VERSION "HNNBNNNYNNNNNNNNNNNNNNNNNNNNNNNNNNNNNNNNNN/4/%%%/4/'%**4NNN///"

NS_ :

BS_:

BU_: BAP_Tester Gateway_Max Getriebe_DQ Motor_konv Parksperre Schaltbetaetigung

BO_ 2550530105 ISOx_LCU_SMH_Resp: 8 Vector__XXX
 SG_ ISOx_LCU_SMH_Resp_Data : 0|64@1+ (1.0,0.0) [0.0|18446744073709551615] ""  Gateway_Max

BO_ 2621833273 ISOx_LCU_SMH_Resp_FD: 64 Vector__XXX
 SG_ ISOx_LCU_SMH_Resp_FD_Data : 0|512@1+ (1.0,0.0) [0.0|13407807929942597099574024998205846127479365820592393377723561443721764030073546976801874298166903427690031858186486050853753882811946569946433649006084095] ""  Gateway_Max

BO_ 2549874806 ISOx_MO_01_Req: 8 Gateway_Max
 SG_ ISOx_MO_01_Req_Data : 0|64@1+ (1.0,0.0) [0.0|18446744073709551615] ""  Motor_konv

BO_ 2621440118 ISOx_MO_01_Req_FD: 64 Gateway_Max
 SG_ ISOx_MO_01_Req_FD_Data : 0|512@1+ (1.0,0.0) [0.0|13407807929942597099574024998205846127479365820592393377723561443721764030073546976801874298166903427690031858186486050853753882811946569946433649006084095] ""  Motor_konv

BO_ 2550005878 ISOx_MO_01_Resp: 8 Motor_konv
 SG_ ISOx_MO_01_Resp_Data : 0|64@1+ (1.0,0.0) [0.0|18446744073709551615] ""  Gateway_Max

BO_ 2621571190 ISOx_MO_01_Resp_FD: 64 Motor_konv
 SG_ ISOx_MO_01_Resp_FD_Data : 0|512@1+ (1.0,0.0) [0.0|13407807929942597099574024998205846127479365820592393377723561443721764030073546976801874298166903427690031858186486050853753882811946569946433649006084095] ""  Gateway_Max

BO_ 2549874821 ISOx_RSG_Req: 8 Gateway_Max
 SG_ ISOx_RSG_Req_Data : 0|64@1+ (1.0,0.0) [0.0|18446744073709551615] ""  Vector__XXX

BO_ 2621440133 ISOx_RSG_Req_FD: 64 Gateway_Max
 SG_ ISOx_RSG_Req_FD_Data : 0|512@1+ (1.0,0.0) [0.0|13407807929942597099574024998205846127479365820592393377723561443721764030073546976801874298166903427690031858186486050853753882811946569946433649006084095] ""  Vector__XXX

BO_ 2550005893 ISOx_RSG_Resp: 8 Vector__XXX
 SG_ ISOx_RSG_Resp_Data : 0|64@1+ (1.0,0.0) [0.0|18446744073709551615] ""  Gateway_Max

BO_ 2621571205 ISOx_RSG_Resp_FD: 64 Vector__XXX
 SG_ ISOx_RSG_Resp_FD_Data : 0|512@1+ (1.0,0.0) [0.0|13407807929942597099574024998205846127479365820592393377723561443721764030073546976801874298166903427690031858186486050853753882811946569946433649006084095] ""  Gateway_Max

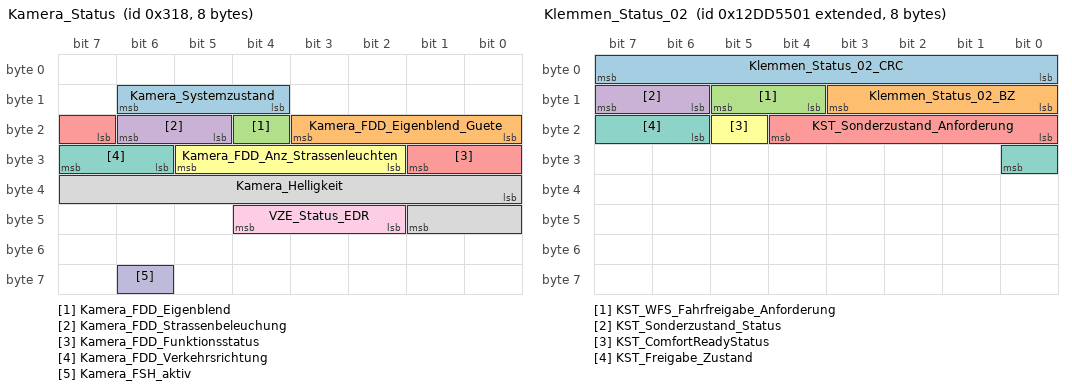
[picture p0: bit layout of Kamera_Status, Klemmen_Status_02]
BO_ 792 Kamera_Status: 8 Gateway_Max
 SG_ Kamera_Systemzustand : 12|3@1+ (1.0,0.0) [0.0|7] ""  Motor_konv
 SG_ Kamera_FDD_Eigenblend_Guete : 16|4@1+ (10,0) [0|100] "Unit_PerCent"  Vector__XXX
 SG_ Kamera_FDD_Eigenblend : 20|1@1+ (1.0,0.0) [0.0|1] ""  Vector__XXX
 SG_ Kamera_FDD_Strassenbeleuchung : 21|2@1+ (1.0,0.0) [0.0|3] ""  Vector__XXX
 SG_ Kamera_FDD_Funktionsstatus : 23|3@1+ (1.0,0.0) [0.0|7] ""  Vector__XXX
 SG_ Kamera_FDD_Anz_Strassenleuchten : 26|4@1+ (1,0) [0|14] ""  Vector__XXX
 SG_ Kamera_FDD_Verkehrsrichtung : 30|2@1+ (1.0,0.0) [0.0|3] ""  Vector__XXX
 SG_ Kamera_Helligkeit : 32|10@1+ (10,0) [0|10000] "Unit_Lux"  Vector__XXX
 SG_ VZE_Status_EDR : 42|3@1+ (1.0,0.0) [0.0|7] ""  Vector__XXX
 SG_ Kamera_FSH_aktiv : 62|1@1+ (1.0,0.0) [0.0|1] ""  Vector__XXX

BO_ 1426 Kessy_04: 8 Gateway_Max
 SG_ KY_ID_Geber1_im_Fzg : 12|1@1+ (1.0,0.0) [0.0|1] ""  Vector__XXX
 SG_ KY_ID_Geber2_im_Fzg : 13|1@1+ (1.0,0.0) [0.0|1] ""  Vector__XXX
 SG_ KY_ID_Geber3_im_Fzg : 14|1@1+ (1.0,0.0) [0.0|1] ""  Vector__XXX
 SG_ KY_ID_Geber4_im_Fzg : 15|1@1+ (1.0,0.0) [0.0|1] ""  Vector__XXX
 SG_ KY_Startknopf_Bel : 16|1@1+ (1.0,0.0) [0.0|1] ""  Vector__XXX
 SG_ KY_ID_Geber_Suche : 17|1@1+ (1.0,0.0) [0.0|1] ""  Vector__XXX
 SG_ KY_Meldungen : 18|4@1+ (1.0,0.0) [0.0|15] ""  Vector__XXX
 SG_ KY_Gong_600 : 22|1@1+ (1.0,0.0) [0.0|1] ""  Vector__XXX
 SG_ KY_Passiv_Autolock_Menue : 23|1@1+ (1.0,0.0) [0.0|1] ""  Vector__XXX
 SG_ KY_Passiv_Autolock_Akt : 24|1@1+ (1.0,0.0) [0.0|1] ""  Vector__XXX
 SG_ KY_Passiv_Autolock : 25|1@1+ (1.0,0.0) [0.0|1] ""  Vector__XXX
 SG_ KY_Passiv_Autounlock : 26|1@1+ (1.0,0.0) [0.0|1] ""  Vector__XXX
 SG_ KY_Gestik_HD : 27|1@1+ (1.0,0.0) [0.0|1] ""  Vector__XXX
 SG_ KY_StartStopp_Info : 28|2@1+ (1.0,0.0) [0.0|3] ""  Motor_konv
 SG_ KY_Fzg_Verlassen_erkannt : 30|1@1+ (1.0,0.0) [0.0|1] ""  Vector__XXX
 SG_ KY_Fzg_Zugang_erkannt : 31|1@1+ (1.0,0.0) [0.0|1] ""  Vector__XXX
 SG_ KY_EasyClose_Abbruch : 32|1@1+ (1.0,0.0) [0.0|1] ""  Vector__XXX
 SG_ KY_EasyClose_Status : 33|3@1+ (1.0,0.0) [0.0|7] ""  Vector__XXX
 SG_ KY_HD_Auffahrt : 36|1@1+ (1.0,0.0) [0.0|1] ""  Vector__XXX
 SG_ KY_HD_Zufahrt : 37|1@1+ (1.0,0.0) [0.0|1] ""  Vector__XXX
 SG_ KY_Aktive_LFScans : 38|4@1+ (1.0,0.0) [0.0|15] ""  Vector__XXX
 SG_ KY_LF_Aktiv : 42|1@1+ (1.0,0.0) [0.0|1] ""  Vector__XXX
 SG_ KY_AnzKoord_Info : 43|2@1+ (1.0,0.0) [0.0|3] ""  Vector__XXX
 SG_ KY_Schluesselposition_9 : 45|2@1+ (1.0,0.0) [0.0|3] ""  Vector__XXX
 SG_ KY_Schluesselposition_1 : 48|2@1+ (1.0,0.0) [0.0|3] ""  Vector__XXX
 SG_ KY_Schluesselposition_2 : 50|2@1+ (1.0,0.0) [0.0|3] ""  Vector__XXX
 SG_ KY_Schluesselposition_3 : 52|2@1+ (1.0,0.0) [0.0|3] ""  Vector__XXX
 SG_ KY_Schluesselposition_4 : 54|2@1+ (1.0,0.0) [0.0|3] ""  Vector__XXX
 SG_ KY_Schluesselposition_5 : 56|2@1+ (1.0,0.0) [0.0|3] ""  Vector__XXX
 SG_ KY_Schluesselposition_6 : 58|2@1+ (1.0,0.0) [0.0|3] ""  Vector__XXX
 SG_ KY_Schluesselposition_7 : 60|2@1+ (1.0,0.0) [0.0|3] ""  Vector__XXX
 SG_ KY_Schluesselposition_8 : 62|2@1+ (1.0,0.0) [0.0|3] ""  Vector__XXX

BO_ 960 Klemmen_Status_01: 4 Gateway_Max
 SG_ Klemmen_Status_01_CRC : 0|8@1+ (1,0) [0|255] ""  Getriebe_DQ,Motor_konv
 SG_ Klemmen_Status_01_BZ : 8|4@1+ (1,0) [0|15] ""  Getriebe_DQ,Motor_konv
 SG_ RSt_Fahrerhinweise : 12|4@1+ (1.0,0.0) [0.0|15] ""  Vector__XXX
 SG_ ZAS_Kl_S : 16|1@1+ (1.0,0.0) [0.0|1] ""  Vector__XXX
 SG_ ZAS_Kl_15 : 17|1@1+ (1.0,0.0) [0.0|1] ""  Getriebe_DQ,Motor_konv,Parksperre,Schaltbetaetigung
 SG_ ZAS_Kl_X : 18|1@1+ (1.0,0.0) [0.0|1] ""  Vector__XXX
 SG_ ZAS_Kl_50_Startanforderung : 19|1@1+ (1.0,0.0) [0.0|1] ""  Motor_konv
 SG_ BCM_Remotestart_Betrieb : 20|1@1+ (1.0,0.0) [0.0|1] ""  Motor_konv
 SG_ ZAS_Kl_Infotainment : 21|1@1+ (1.0,0.0) [0.0|1] ""  Vector__XXX
 SG_ BCM_Remotestart_KL15_Anf : 22|1@1+ (1.0,0.0) [0.0|1] ""  Getriebe_DQ,Motor_konv
 SG_ BCM_Remotestart_MO_Start : 23|1@1+ (1.0,0.0) [0.0|1] ""  Motor_konv
 SG_ KST_Warn_P1_ZST_def : 24|1@1+ (1.0,0.0) [0.0|1] ""  Vector__XXX
 SG_ KST_Warn_P2_ZST_def : 25|1@1+ (1.0,0.0) [0.0|1] ""  Vector__XXX
 SG_ KST_Fahrerhinweis_1 : 26|1@1+ (1.0,0.0) [0.0|1] ""  Vector__XXX
 SG_ KST_Fahrerhinweis_2 : 27|1@1+ (1.0,0.0) [0.0|1] ""  Vector__XXX
 SG_ BCM_Ausparken_Betrieb : 28|1@1+ (1.0,0.0) [0.0|1] ""  Vector__XXX
 SG_ KST_Fahrerhinweis_4 : 29|1@1+ (1.0,0.0) [0.0|1] ""  Vector__XXX
 SG_ KST_Fahrerhinweis_5 : 30|1@1+ (1.0,0.0) [0.0|1] ""  Vector__XXX
 SG_ KST_Fahrerhinweis_6 : 31|1@1+ (1.0,0.0) [0.0|1] ""  Vector__XXX

BO_ 2463978753 Klemmen_Status_02: 8 Gateway_Max
 SG_ Klemmen_Status_02_CRC : 0|8@1+ (1,0) [0|255] ""  Motor_konv
 SG_ Klemmen_Status_02_BZ : 8|4@1+ (1,0) [0|15] ""  Motor_konv
 SG_ KST_WFS_Fahrfreigabe_Anforderung : 12|2@1+ (1.0,0.0) [0.0|3] ""  Getriebe_DQ
 SG_ KST_Sonderzustand_Status : 14|2@1+ (1.0,0.0) [0.0|3] ""  Getriebe_DQ,Motor_konv
 SG_ KST_Sonderzustand_Anforderung : 16|5@1+ (1.0,0.0) [0.0|31] ""  Getriebe_DQ,Motor_konv
 SG_ KST_ComfortReadyStatus : 21|1@1+ (1.0,0.0) [0.0|1] ""  Vector__XXX
 SG_ KST_Freigabe_Zustand : 22|3@1+ (1.0,0.0) [0.0|7] ""  Vector__XXX

BO_ 1420 Klemmen_Steuerung_01: 8 Gateway_Max
 SG_ Klemmen_Steuerung_01_CRC : 0|8@1+ (1,0) [0|255] ""  Motor_konv
 SG_ Klemmen_Steuerung_01_BZ : 8|4@1+ (1,0) [0|15] ""  Motor_konv
 SG_ KST_Anf_Klemme_15 : 12|1@1+ (1.0,0.0) [0.0|1] ""  Vector__XXX
 SG_ KST_Anf_Klemme_50 : 13|1@1+ (1.0,0.0) [0.0|1] ""  Motor_konv
 SG_ KST_Anf_Klemme_S : 14|1@1+ (1.0,0.0) [0.0|1] ""  Vector__XXX
 SG_ KST_Txt_Werkstatt : 15|1@1+ (1.0,0.0) [0.0|1] ""  Vector__XXX
 SG_ KST_Txt_P_Gang : 16|1@1+ (1.0,0.0) [0.0|1] ""  Vector__XXX
 SG_ KST_Txt_Panikabschaltung : 17|1@1+ (1.0,0.0) [0.0|1] ""  Vector__XXX
 SG_ KST_Anf_Klemmenfreigabe_ELV : 18|1@1+ (1.0,0.0) [0.0|1] ""  Vector__XXX
 SG_ KST_Txt_Komfortabschaltung : 19|1@1+ (1.0,0.0) [0.0|1] ""  Vector__XXX
 SG_ KST_ZAT_betaetigt : 20|1@1+ (1.0,0.0) [0.0|1] ""  Vector__XXX
 SG_ KST_Unterdr_Zuendungsmeldung : 21|1@1+ (1.0,0.0) [0.0|1] ""  Vector__XXX
 SG_ KST_aut_Abschaltung_Zuendung : 22|1@1+ (1.0,0.0) [0.0|1] ""  Vector__XXX
 SG_ KST_Anf_Klemmenfreigabe_WFS : 23|1@1+ (1.0,0.0) [0.0|1] ""  Vector__XXX
 SG_ KST_Anf_ZV_Verriegelung : 24|1@1+ (1.0,0.0) [0.0|1] ""  Vector__XXX
 SG_ Relais_VoKo_angesteuert : 25|1@1+ (1.0,0.0) [0.0|1] ""  Vector__XXX
 SG_ RSt_Anforderung_HMS : 26|3@1+ (1.0,0.0) [0.0|7] ""  Vector__XXX
 SG_ KST_Zuendungswarnung : 29|2@1+ (1.0,0.0) [0.0|3] ""  Vector__XXX
 SG_ KST_Anzeige_Klemmenzustand : 36|3@1+ (1.0,0.0) [0.0|7] ""  Vector__XXX

BO_ 949 Klima_11: 8 Gateway_Max
 SG_ KL_Drehz_Anh : 0|1@1+ (1.0,0.0) [0.0|1] ""  Motor_konv
 SG_ KL_Vorwarn_Komp_ein : 1|1@1+ (1.0,0.0) [0.0|1] ""  Motor_konv
 SG_ KL_AC_Schalter : 2|1@1+ (1.0,0.0) [0.0|1] ""  Vector__XXX
 SG_ KL_Komp_Moment_alt : 3|1@1+ (1.0,0.0) [0.0|1] ""  Vector__XXX
 SG_ KL_Vorwarn_Zuheizer_ein : 6|1@1+ (1.0,0.0) [0.0|1] ""  Vector__XXX
 SG_ KL_Zustand : 7|1@1+ (1.0,0.0) [0.0|1] ""  Motor_konv
 SG_ KL_Kompressorkupplung_linear : 8|8@1+ (20,0) [0|4000] "Unit_MilliAmper"  Vector__XXX
 SG_ KL_Charisma_FahrPr : 16|4@1+ (1.0,0.0) [0.0|15] ""  Vector__XXX
 SG_ KL_Charisma_Status : 20|2@1+ (1.0,0.0) [0.0|3] ""  Vector__XXX
 SG_ KL_nachtr_Stopp_Anf : 22|1@1+ (1.0,0.0) [0.0|1] ""  Motor_konv
 SG_ KL_T_Charge : 23|1@1+ (1.0,0.0) [0.0|1] ""  Vector__XXX
 SG_ KL_Last_Kompr : 24|8@1+ (0.25,0) [0.00|63.50] "Unit_NewtoMeter"  Motor_konv
 SG_ KL_Spannungs_Anf : 32|2@1+ (1.0,0.0) [0.0|3] ""  Vector__XXX
 SG_ KL_Thermomanagement : 34|2@1+ (1.0,0.0) [0.0|3] ""  Motor_konv
 SG_ KL_StartStopp_Info : 36|2@1+ (1.0,0.0) [0.0|3] ""  Motor_konv
 SG_ KL_Freilauf_Info : 38|2@1+ (1.0,0.0) [0.0|3] ""  Motor_konv
 SG_ KL_Anf_KL : 40|8@1+ (0.4,0) [0.0|101.6] "Unit_PerCent"  Motor_konv
 SG_ KL_el_Zuheizer_Stufe : 48|3@1+ (1.0,0.0) [0.0|7] ""  Motor_konv
 SG_ KL_Ausstattung_Klima : 51|3@1+ (1.0,0.0) [0.0|7] ""  Motor_konv
 SG_ KL_Variante_Standheizung : 54|2@1+ (1.0,0.0) [0.0|3] ""  Vector__XXX
 SG_ KL_AirCleaner_aktiv : 56|1@1+ (1.0,0.0) [0.0|1] ""  Vector__XXX
 SG_ KL_Anf_KV : 57|7@1+ (1,0) [0|100] "Unit_PerCent"  Vector__XXX

BO_ 1640 Klima_12: 8 Gateway_Max
 SG_ KL_LRH_Taster : 0|1@1+ (1.0,0.0) [0.0|1] ""  Vector__XXX
 SG_ KL_LRH_Stufe : 1|2@1+ (1.0,0.0) [0.0|3] ""  Vector__XXX
 SG_ HSH_Taster : 3|2@1+ (1.0,0.0) [0.0|3] ""  Vector__XXX
 SG_ FSH_Taster : 5|1@1+ (1.0,0.0) [0.0|1] ""  Vector__XXX
 SG_ KL_Zuheizer_Freigabe : 6|1@1+ (1.0,0.0) [0.0|1] ""  Vector__XXX
 SG_ KL_Beschlagsgefahr : 7|1@1+ (1.0,0.0) [0.0|1] ""  Vector__XXX
 SG_ KL_SIH_Soll_li : 8|3@1+ (1,0) [0|6] ""  Vector__XXX
 SG_ KL_SIH_Soll_re : 11|3@1+ (1,0) [0|6] ""  Vector__XXX
 SG_ KRH_Soll_li : 14|2@1+ (1.0,0.0) [0.0|3] ""  Vector__XXX
 SG_ KL_SIL_Soll_li : 16|3@1+ (1,0) [0|6] ""  Vector__XXX
 SG_ KL_SIL_Soll_re : 19|3@1+ (1,0) [0|6] ""  Vector__XXX
 SG_ KRH_Soll_re : 22|2@1+ (1.0,0.0) [0.0|3] ""  Vector__XXX
 SG_ KL_Geblspng_Soll : 24|8@1+ (0.05,1.45) [1.50|14.00] "Unit_Volt"  Vector__XXX
 SG_ KL_Geblspng_Fond_Soll : 32|8@1+ (0.05,1.45) [1.50|14.00] "Unit_Volt"  Vector__XXX
 SG_ KL_I_Geblaese : 40|8@1+ (0.25,0) [0.00|63.50] "Unit_Amper"  Vector__XXX
 SG_ KL_Kompressorstrom_soll : 48|10@1+ (1,0) [0|1021] ""  Vector__XXX
 SG_ KL_Umluftklappe_Status : 58|4@1+ (1.0,0.0) [0.0|15] ""  Vector__XXX
 SG_ KL_PTC_Verbauinfo : 62|2@1+ (1.0,0.0) [0.0|3] ""  Motor_konv

BO_ 1511 Klima_EV_03: 8 Gateway_Max
 SG_ KL_HV_Heizer_Strom : 0|8@1+ (0.25,0) [0.00|63.50] "Unit_Amper"  Vector__XXX
 SG_ KL_EKK_Strom : 8|8@1+ (0.25,0) [0.00|63.50] "Unit_Amper"  Vector__XXX
 SG_ KL_Pumpe_02_Soll : 16|7@1+ (1,0) [0|100] "Unit_PerCent"  Vector__XXX
 SG_ KL_Ventil_03_Soll : 23|1@1+ (1.0,0.0) [0.0|1] ""  Vector__XXX
 SG_ KL_Ventil_10_Status : 24|3@1+ (1.0,0.0) [0.0|7] ""  Vector__XXX
 SG_ KL_Senderkennung : 27|1@1+ (1.0,0.0) [0.0|1] ""  Vector__XXX
 SG_ WP_KJ_Soll : 28|2@1+ (1.0,0.0) [0.0|3] ""  Vector__XXX
 SG_ KL_Fehler_HV_EKK : 30|2@1+ (1.0,0.0) [0.0|3] ""  Vector__XXX
 SG_ KL_Fehler_HV_Heizer : 32|2@1+ (1.0,0.0) [0.0|3] ""  Vector__XXX
 SG_ KL_BattKond_WaPu_DZMax : 34|6@1+ (2,0) [0|100] "Unit_PerCent"  Vector__XXX
 SG_ WP_Kuehlerluefter_Anf : 40|8@1+ (0.4,0) [0.0|101.6] "Unit_PerCent"  Vector__XXX
 SG_ KL_KM_ASV_01_Status : 48|2@1+ (1.0,0.0) [0.0|3] ""  Vector__XXX
 SG_ KL_KM_ASV_02_Status : 50|2@1+ (1.0,0.0) [0.0|3] ""  Vector__XXX
 SG_ KL_Vorwarn_HVHeizer_Leistung : 52|4@1+ (1.0,0.0) [0.0|15] ""  Vector__XXX
 SG_ KL_Status_EoHVL_EKK : 56|2@1+ (1.0,0.0) [0.0|3] ""  Vector__XXX
 SG_ KL_Status_EoHVL_Heizer : 58|2@1+ (1.0,0.0) [0.0|3] ""  Vector__XXX
 SG_ KL_Status_EoHVL_EKK_2 : 60|2@1+ (1.0,0.0) [0.0|3] ""  Vector__XXX
 SG_ KL_Status_EoHVL_Heizer_2 : 62|2@1+ (1.0,0.0) [0.0|3] ""  Vector__XXX

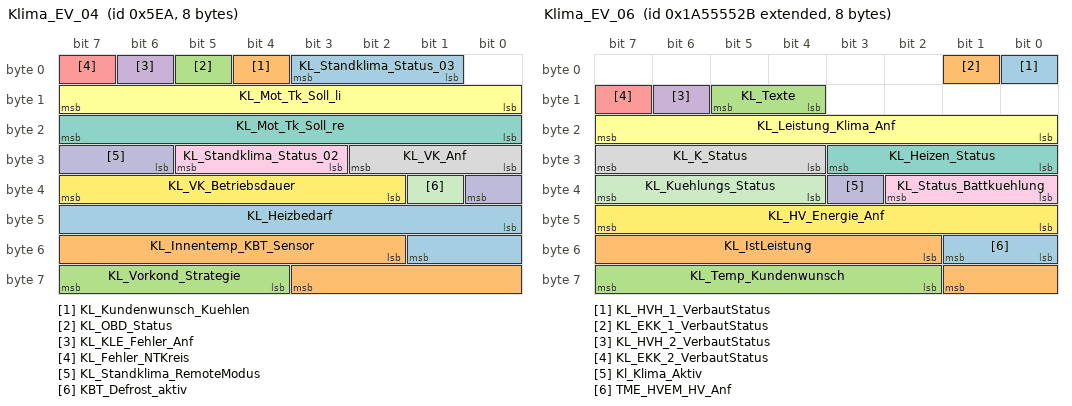
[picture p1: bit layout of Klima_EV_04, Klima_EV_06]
BO_ 1514 Klima_EV_04: 8 Gateway_Max
 SG_ KL_Standklima_Status_03 : 1|3@1+ (1.0,0.0) [0.0|7] ""  Vector__XXX
 SG_ KL_Kundenwunsch_Kuehlen : 4|1@1+ (1.0,0.0) [0.0|1] ""  Vector__XXX
 SG_ KL_OBD_Status : 5|1@1+ (1.0,0.0) [0.0|1] ""  Vector__XXX
 SG_ KL_KLE_Fehler_Anf : 6|1@1+ (1.0,0.0) [0.0|1] ""  Vector__XXX
 SG_ KL_Fehler_NTKreis : 7|1@1+ (1.0,0.0) [0.0|1] ""  Vector__XXX
 SG_ KL_Mot_Tk_Soll_li : 8|8@1+ (0.5,0) [0.0|100.0] "Unit_PerCent"  Vector__XXX
 SG_ KL_Mot_Tk_Soll_re : 16|8@1+ (0.5,0) [0.0|100.0] "Unit_PerCent"  Vector__XXX
 SG_ KL_VK_Anf : 24|3@1+ (1.0,0.0) [0.0|7] ""  Vector__XXX
 SG_ KL_Standklima_Status_02 : 27|3@1+ (1.0,0.0) [0.0|7] ""  Vector__XXX
 SG_ KL_Standklima_RemoteModus : 30|3@1+ (1.0,0.0) [0.0|7] ""  Vector__XXX
 SG_ KBT_Defrost_aktiv : 33|1@1+ (1.0,0.0) [0.0|1] ""  Vector__XXX
 SG_ KL_VK_Betriebsdauer : 34|6@1+ (1,0) [0|60] "Unit_Minut"  Vector__XXX
 SG_ KL_Heizbedarf : 40|10@1+ (0.1,0) [0.1|90.0] "Unit_DegreCelsi"  Vector__XXX
 SG_ KL_Innentemp_KBT_Sensor : 50|10@1+ (0.1,-40) [-40.0|62.0] "Unit_DegreCelsi"  Vector__XXX
 SG_ KL_Vorkond_Strategie : 60|4@1+ (1.0,0.0) [0.0|15] ""  Vector__XXX

BO_ 2589283627 Klima_EV_06: 8 Gateway_Max
 SG_ KL_HVH_1_VerbautStatus : 0|1@1+ (1.0,0.0) [0.0|1] ""  Vector__XXX
 SG_ KL_EKK_1_VerbautStatus : 1|1@1+ (1.0,0.0) [0.0|1] ""  Vector__XXX
 SG_ KL_Texte : 12|2@1+ (1.0,0.0) [0.0|3] ""  Vector__XXX
 SG_ KL_HVH_2_VerbautStatus : 14|1@1+ (1.0,0.0) [0.0|1] ""  Vector__XXX
 SG_ KL_EKK_2_VerbautStatus : 15|1@1+ (1.0,0.0) [0.0|1] ""  Vector__XXX
 SG_ KL_Leistung_Klima_Anf : 16|8@1+ (50,0) [0|12650] "Unit_Watt"  Vector__XXX
 SG_ KL_Heizen_Status : 24|4@1+ (1.0,0.0) [0.0|15] ""  Vector__XXX
 SG_ KL_K_Status : 28|4@1+ (1.0,0.0) [0.0|15] ""  Vector__XXX
 SG_ KL_Status_Battkuehlung : 32|3@1+ (1.0,0.0) [0.0|7] ""  Vector__XXX
 SG_ Kl_Klima_Aktiv : 35|1@1+ (1.0,0.0) [0.0|1] ""  Vector__XXX
 SG_ KL_Kuehlungs_Status : 36|4@1+ (1.0,0.0) [0.0|15] ""  Vector__XXX
 SG_ KL_HV_Energie_Anf : 40|8@1+ (50,0) [0|12600] "Unit_WattHour"  Vector__XXX
 SG_ TME_HVEM_HV_Anf : 48|2@1+ (1.0,0.0) [0.0|3] ""  Vector__XXX
 SG_ KL_IstLeistung : 50|8@1+ (50,0) [0|12650] "Unit_Watt"  Vector__XXX
 SG_ KL_Temp_Kundenwunsch : 58|6@1+ (0.5,15) [16.0|29.5] "Unit_DegreCelsi"  Vector__XXX

BO_ 2589283574 Klima_EV_10: 16 Gateway_Max
 SG_ KL_OBD_Status_Auth : 12|1@1+ (1.0,0.0) [0.0|1] ""  Vector__XXX
 SG_ OBDProtocol_Klima : 16|8@1+ (1.0,0.0) [0.0|255] ""  Motor_konv
 SG_ SOK_Klima_EV_10_Signatur : 64|64@1+ (1,0) [1|18446744073709551615] "Unit_None"  Vector__XXX

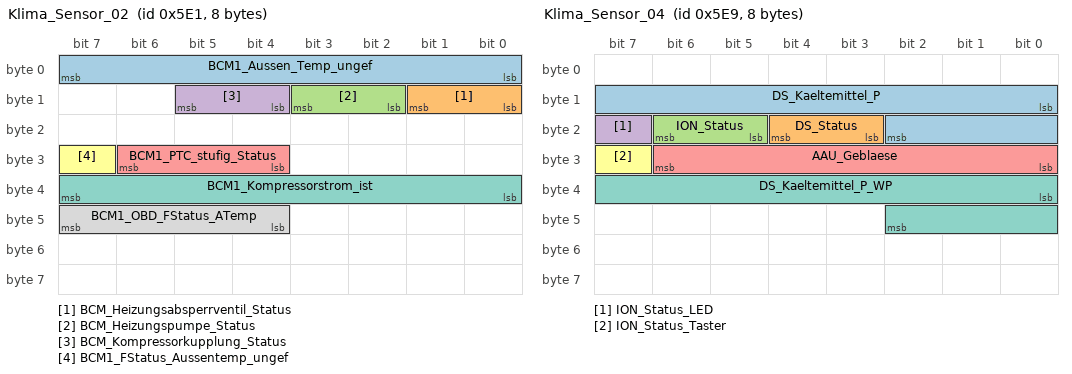
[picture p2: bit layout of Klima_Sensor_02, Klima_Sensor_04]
BO_ 1505 Klima_Sensor_02: 8 Gateway_Max
 SG_ BCM1_Aussen_Temp_ungef : 0|8@1+ (0.5,-50) [-50.0|76.0] "Unit_DegreCelsi"  Motor_konv
 SG_ BCM_Heizungsabsperrventil_Status : 8|2@1+ (1.0,0.0) [0.0|3] ""  Vector__XXX
 SG_ BCM_Heizungspumpe_Status : 10|2@1+ (1.0,0.0) [0.0|3] ""  Vector__XXX
 SG_ BCM_Kompressorkupplung_Status : 12|2@1+ (1.0,0.0) [0.0|3] ""  Vector__XXX
 SG_ BCM1_PTC_stufig_Status : 28|3@1+ (1.0,0.0) [0.0|7] ""  Vector__XXX
 SG_ BCM1_FStatus_Aussentemp_ungef : 31|1@1+ (1.0,0.0) [0.0|1] ""  Vector__XXX
 SG_ BCM1_Kompressorstrom_ist : 32|8@1+ (4,0) [0|1000] "Unit_MilliAmper"  Vector__XXX
 SG_ BCM1_OBD_FStatus_ATemp : 44|4@1+ (1.0,0.0) [0.0|15] ""  Motor_konv

BO_ 1513 Klima_Sensor_04: 8 Gateway_Max
 SG_ DS_Kaeltemittel_P : 8|11@1+ (0.0161,0) [0.0000|32.9245] "Unit_Bar"  Motor_konv
 SG_ DS_Status : 19|2@1+ (1.0,0.0) [0.0|3] ""  Vector__XXX
 SG_ ION_Status : 21|2@1+ (1.0,0.0) [0.0|3] ""  Vector__XXX
 SG_ ION_Status_LED : 23|1@1+ (1.0,0.0) [0.0|1] ""  Vector__XXX
 SG_ AAU_Geblaese : 24|7@1+ (1,0) [0|100] "Unit_PerCent"  Vector__XXX
 SG_ ION_Status_Taster : 31|1@1+ (1.0,0.0) [0.0|1] ""  Vector__XXX
 SG_ DS_Kaeltemittel_P_WP : 32|11@1+ (0.5,0) [0.0|180.0] "Unit_Bar"  Vector__XXX

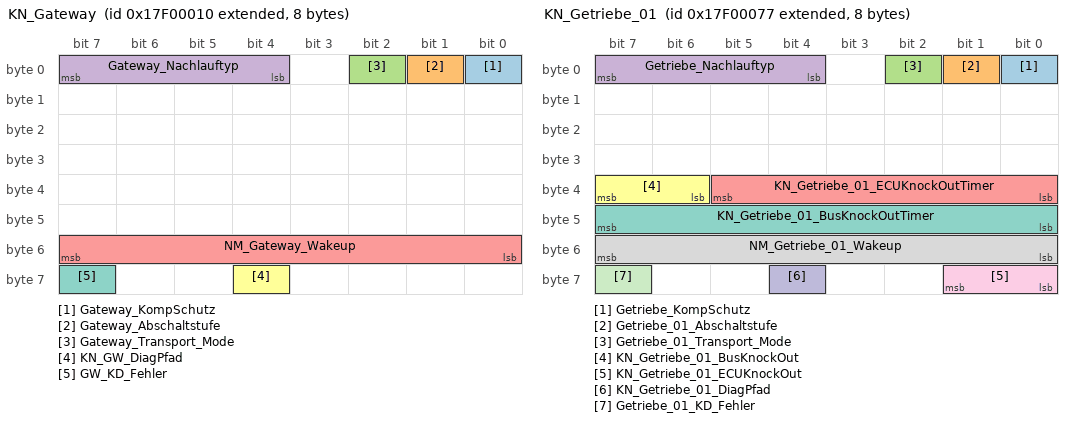
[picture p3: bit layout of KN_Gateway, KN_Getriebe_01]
BO_ 2549088272 KN_Gateway: 8 Gateway_Max
 SG_ Gateway_KompSchutz : 0|1@1+ (1.0,0.0) [0.0|1] ""  Vector__XXX
 SG_ Gateway_Abschaltstufe : 1|1@1+ (1.0,0.0) [0.0|1] ""  Vector__XXX
 SG_ Gateway_Transport_Mode : 2|1@1+ (1.0,0.0) [0.0|1] ""  Vector__XXX
 SG_ Gateway_Nachlauftyp : 4|4@1+ (1.0,0.0) [0.0|15] ""  Vector__XXX
 SG_ NM_Gateway_Wakeup : 48|8@1+ (1.0,0.0) [0.0|255] ""  Vector__XXX
 SG_ KN_GW_DiagPfad : 60|1@1+ (1.0,0.0) [0.0|1] ""  Vector__XXX
 SG_ GW_KD_Fehler : 63|1@1+ (1.0,0.0) [0.0|1] ""  Vector__XXX

BO_ 2549088375 KN_Getriebe_01: 8 Getriebe_DQ
 SG_ Getriebe_KompSchutz : 0|1@1+ (1.0,0.0) [0.0|1] ""  Vector__XXX
 SG_ Getriebe_01_Abschaltstufe : 1|1@1+ (1.0,0.0) [0.0|1] ""  Vector__XXX
 SG_ Getriebe_01_Transport_Mode : 2|1@1+ (1.0,0.0) [0.0|1] ""  Vector__XXX
 SG_ Getriebe_Nachlauftyp : 4|4@1+ (1.0,0.0) [0.0|15] ""  Gateway_Max
 SG_ KN_Getriebe_01_ECUKnockOutTimer : 32|6@1+ (1,0) [0|62] ""  Vector__XXX
 SG_ KN_Getriebe_01_BusKnockOut : 38|2@1+ (1.0,0.0) [0.0|3] ""  Vector__XXX
 SG_ KN_Getriebe_01_BusKnockOutTimer : 40|8@1+ (1,0) [0|254] ""  Vector__XXX
 SG_ NM_Getriebe_01_Wakeup : 48|8@1+ (1.0,0.0) [0.0|255] ""  Vector__XXX
 SG_ KN_Getriebe_01_ECUKnockOut : 56|2@1+ (1.0,0.0) [0.0|3] ""  Vector__XXX
 SG_ KN_Getriebe_01_DiagPfad : 60|1@1+ (1.0,0.0) [0.0|1] ""  Gateway_Max
 SG_ Getriebe_01_KD_Fehler : 63|1@1+ (1.0,0.0) [0.0|1] ""  Gateway_Max

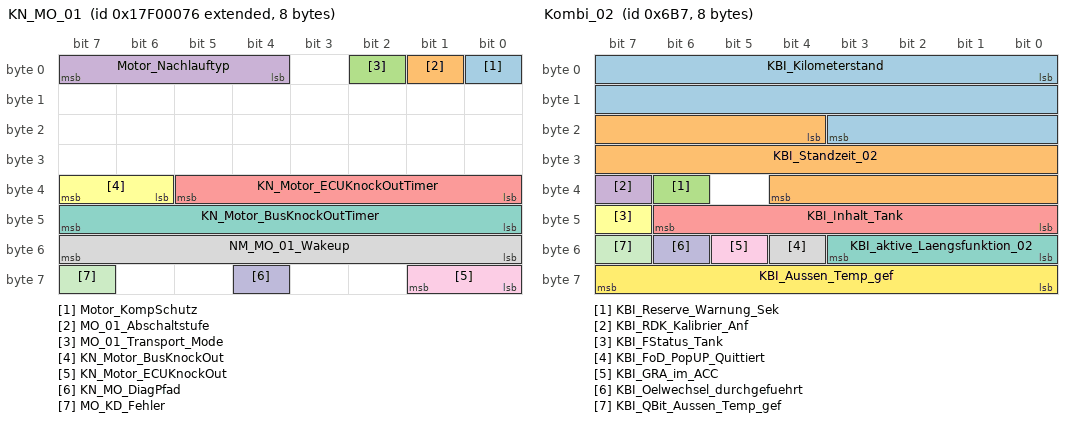
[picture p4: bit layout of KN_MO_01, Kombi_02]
BO_ 2549088374 KN_MO_01: 8 Motor_konv
 SG_ Motor_KompSchutz : 0|1@1+ (1.0,0.0) [0.0|1] ""  Vector__XXX
 SG_ MO_01_Abschaltstufe : 1|1@1+ (1.0,0.0) [0.0|1] ""  Vector__XXX
 SG_ MO_01_Transport_Mode : 2|1@1+ (1.0,0.0) [0.0|1] ""  Vector__XXX
 SG_ Motor_Nachlauftyp : 4|4@1+ (1.0,0.0) [0.0|15] ""  Gateway_Max
 SG_ KN_Motor_ECUKnockOutTimer : 32|6@1+ (1,0) [0|62] "Unit_Minut"  Vector__XXX
 SG_ KN_Motor_BusKnockOut : 38|2@1+ (1.0,0.0) [0.0|3] ""  Vector__XXX
 SG_ KN_Motor_BusKnockOutTimer : 40|8@1+ (1,0) [0|254] ""  Vector__XXX
 SG_ NM_MO_01_Wakeup : 48|8@1+ (1.0,0.0) [0.0|255] ""  Vector__XXX
 SG_ KN_Motor_ECUKnockOut : 56|2@1+ (1.0,0.0) [0.0|3] ""  Vector__XXX
 SG_ KN_MO_DiagPfad : 60|1@1+ (1.0,0.0) [0.0|1] ""  Gateway_Max
 SG_ MO_KD_Fehler : 63|1@1+ (1.0,0.0) [0.0|1] ""  Gateway_Max

BO_ 779 Kombi_01: 8 Gateway_Max
 SG_ KBI_ABS_Lampe : 0|1@1+ (1.0,0.0) [0.0|1] ""  Vector__XXX
 SG_ KBI_ESP_Lampe : 1|1@1+ (1.0,0.0) [0.0|1] ""  Vector__XXX
 SG_ KBI_BKL_Lampe : 2|1@1+ (1.0,0.0) [0.0|1] ""  Vector__XXX
 SG_ KBI_Airbag_Lampe : 3|1@1+ (1.0,0.0) [0.0|1] ""  Vector__XXX
 SG_ KBI_SILA_gueltig : 4|1@1+ (1.0,0.0) [0.0|1] ""  Vector__XXX
 SG_ KBI_Lenkung_Lampe : 5|1@1+ (1,0) [0|1] ""  Vector__XXX
 SG_ KBI_Vorglueh_System_Lampe : 6|1@1+ (1.0,0.0) [0.0|1] ""  Motor_konv
 SG_ KBI_NV_in_Anzeige : 7|1@1+ (1.0,0.0) [0.0|1] ""  Vector__XXX
 SG_ Kombi_01_BZ : 8|4@1+ (1,0) [0|15] ""  Vector__XXX
 SG_ KBI_Anzeigestatus_ACC : 12|1@1+ (1.0,0.0) [0.0|1] ""  Vector__XXX
 SG_ KBI_Anzeigestatus_GRA : 13|2@1+ (1.0,0.0) [0.0|3] ""  Motor_konv
 SG_ KBI_Oeldruck_Schalter : 15|1@1+ (1.0,0.0) [0.0|1] ""  Vector__XXX
 SG_ KBI_Tankwarnung : 16|1@1+ (1.0,0.0) [0.0|1] ""  Motor_konv
 SG_ KBI_MFA_v_Einheit_01 : 17|1@1+ (1.0,0.0) [0.0|1] ""  Motor_konv
 SG_ KBI_im_Stellgliedtest : 18|1@1+ (1.0,0.0) [0.0|1] ""  Vector__XXX
 SG_ KBI_Anzeigefehler_LDW : 19|2@1+ (1.0,0.0) [0.0|3] ""  Vector__XXX
 SG_ KBI_Tankwarnung_ungueltig : 21|1@1+ (1.0,0.0) [0.0|1] ""  Vector__XXX
 SG_ KBI_Oeldruckwarnung : 22|1@1+ (1.0,0.0) [0.0|1] ""  Vector__XXX
 SG_ KBI_Handbremse : 23|1@1+ (1.0,0.0) [0.0|1] ""  Motor_konv
 SG_ KBI_V_Digital : 24|9@1+ (1,0) [0|511] ""  Vector__XXX
 SG_ KBI_PLA_in_Anzeige : 33|1@1+ (1.0,0.0) [0.0|1] ""  Vector__XXX
 SG_ KBI_Anzeigefehler_NV : 34|1@1+ (1.0,0.0) [0.0|1] ""  Vector__XXX
 SG_ KBI_Anzeigestatus_LIM : 35|2@1+ (1.0,0.0) [0.0|3] ""  Motor_konv
 SG_ KBI_ARA_in_Anzeige : 37|1@1+ (1.0,0.0) [0.0|1] ""  Vector__XXX
 SG_ KBI_Taster_Lift : 38|1@1+ (1.0,0.0) [0.0|1] ""  Vector__XXX
 SG_ KBI_Taster_Fahrwerk : 39|1@1+ (1.0,0.0) [0.0|1] ""  Vector__XXX
 SG_ KBI_Audioabsenkung_MIB : 40|2@1+ (1.0,0.0) [0.0|3] ""  Vector__XXX
 SG_ KBI_Bestaetigung_ESP_Off : 42|2@1+ (1.0,0.0) [0.0|3] ""  Vector__XXX
 SG_ KBI_Anzeigestatus_RHP : 44|2@1+ (1.0,0.0) [0.0|3] ""  Vector__XXX
 SG_ KBI_angez_Geschw : 48|10@1+ (0.32,0) [0.00|325.12] "Unit_KiloMeterPerHour"  Motor_konv
 SG_ KBI_Konsistenz_ACC : 59|1@1+ (1.0,0.0) [0.0|1] ""  Vector__XXX
 SG_ KBI_Fehler_Anzeige_ACC : 60|1@1+ (1.0,0.0) [0.0|1] ""  Vector__XXX
 SG_ KBI_Anzeigefehler_SWA : 61|2@1+ (1.0,0.0) [0.0|3] ""  Vector__XXX
 SG_ KBI_Systemstatus : 63|1@1+ (1.0,0.0) [0.0|1] ""  Vector__XXX

BO_ 1719 Kombi_02: 8 Gateway_Max
 SG_ KBI_Kilometerstand : 0|20@1+ (1,0) [0|1048573] "Unit_KiloMeter"  Vector__XXX
 SG_ KBI_Standzeit_02 : 20|17@1+ (1,0) [0|131068] "Unit_Secon"  Getriebe_DQ,Motor_konv
 SG_ KBI_Reserve_Warnung_Sek : 38|1@1+ (1.0,0.0) [0.0|1] ""  Vector__XXX
 SG_ KBI_RDK_Kalibrier_Anf : 39|1@1+ (1.0,0.0) [0.0|1] ""  Vector__XXX
 SG_ KBI_Inhalt_Tank : 40|7@1+ (1,0) [0|125] "Unit_Liter"  Motor_konv
 SG_ KBI_FStatus_Tank : 47|1@1+ (1.0,0.0) [0.0|1] ""  Motor_konv
 SG_ KBI_aktive_Laengsfunktion_02 : 48|4@1+ (1.0,0.0) [0.0|15] ""  Motor_konv
 SG_ KBI_FoD_PopUP_Quittiert : 52|1@1+ (1.0,0.0) [0.0|1] ""  Vector__XXX
 SG_ KBI_GRA_im_ACC : 53|1@1+ (1.0,0.0) [0.0|1] ""  Vector__XXX
 SG_ KBI_Oelwechsel_durchgefuehrt : 54|1@1+ (1.0,0.0) [0.0|1] ""  Motor_konv
 SG_ KBI_QBit_Aussen_Temp_gef : 55|1@1+ (1.0,0.0) [0.0|1] ""  Motor_konv
 SG_ KBI_Aussen_Temp_gef : 56|8@1+ (0.5,-50) [-50.0|75.0] "Unit_DegreCelsi"  Motor_konv

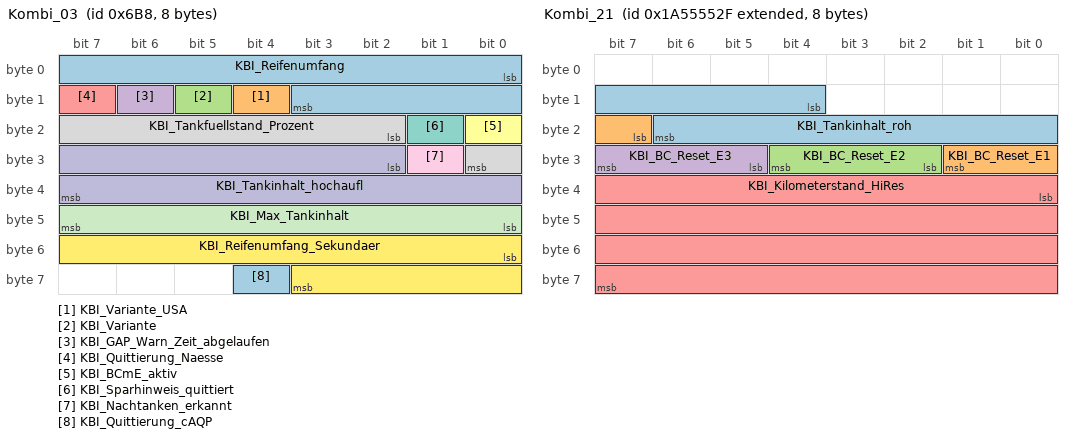
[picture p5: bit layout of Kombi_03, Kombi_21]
BO_ 1720 Kombi_03: 8 Gateway_Max
 SG_ KBI_Reifenumfang : 0|12@1+ (1,0) [0|4095] "Unit_MilliMeter"  Vector__XXX
 SG_ KBI_Variante_USA : 12|1@1+ (1.0,0.0) [0.0|1] ""  Vector__XXX
 SG_ KBI_Variante : 13|1@1+ (1.0,0.0) [0.0|1] ""  Motor_konv
 SG_ KBI_GAP_Warn_Zeit_abgelaufen : 14|1@1+ (1.0,0.0) [0.0|1] ""  Motor_konv
 SG_ KBI_Quittierung_Naesse : 15|1@1+ (1.0,0.0) [0.0|1] ""  Vector__XXX
 SG_ KBI_BCmE_aktiv : 16|1@1+ (1.0,0.0) [0.0|1] ""  Vector__XXX
 SG_ KBI_Sparhinweis_quittiert : 17|1@1+ (1.0,0.0) [0.0|1] ""  Vector__XXX
 SG_ KBI_Tankfuellstand_Prozent : 18|7@1+ (1,0) [0|100] "Unit_PerCent"  Motor_konv
 SG_ KBI_Nachtanken_erkannt : 25|1@1+ (1.0,0.0) [0.0|1] ""  Vector__XXX
 SG_ KBI_Tankinhalt_hochaufl : 26|14@1+ (0.01,0) [0.00|163.81] "Unit_Liter"  Motor_konv
 SG_ KBI_Max_Tankinhalt : 40|8@1+ (0.5,0) [0.0|126.5] ""  Vector__XXX
 SG_ KBI_Reifenumfang_Sekundaer : 48|12@1+ (1,0) [0|4095] "Unit_MilliMeter"  Vector__XXX
 SG_ KBI_Quittierung_cAQP : 60|1@1+ (1.0,0.0) [0.0|1] ""  Vector__XXX

BO_ 2589283631 Kombi_21: 8 Gateway_Max
 SG_ KBI_Tankinhalt_roh : 12|11@1+ (0.1,0) [0.0|204.5] "Unit_Liter"  Vector__XXX
 SG_ KBI_BC_Reset_E1 : 23|3@1+ (1.0,0.0) [0.0|7] ""  Vector__XXX
 SG_ KBI_BC_Reset_E2 : 26|3@1+ (1.0,0.0) [0.0|7] ""  Vector__XXX
 SG_ KBI_BC_Reset_E3 : 29|3@1+ (1.0,0.0) [0.0|7] ""  Vector__XXX
 SG_ KBI_Kilometerstand_HiRes : 32|32@1+ (0.1,0) [0.0|429496729.5] "Unit_KiloMeter"  Motor_konv

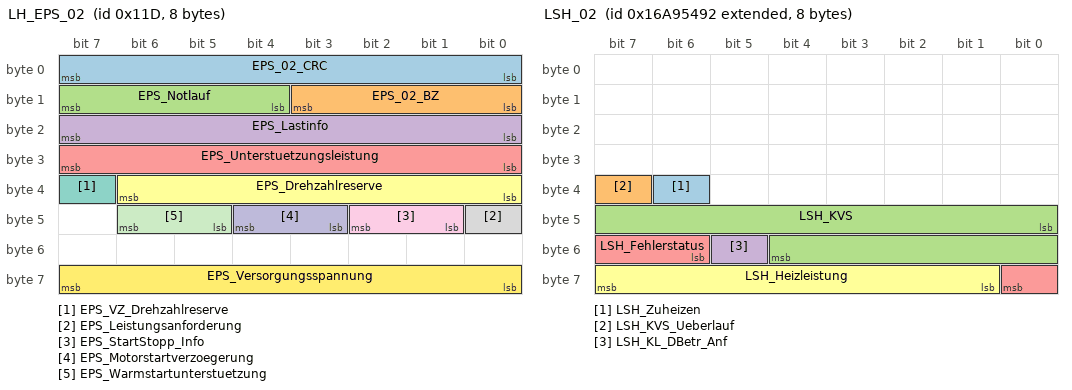
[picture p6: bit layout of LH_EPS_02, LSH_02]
BO_ 285 LH_EPS_02: 8 Gateway_Max
 SG_ EPS_02_CRC : 0|8@1+ (1,0) [0|255] ""  Vector__XXX
 SG_ EPS_02_BZ : 8|4@1+ (1,0) [0|15] ""  Vector__XXX
 SG_ EPS_Notlauf : 12|4@1+ (1.0,0.0) [0.0|15] ""  Vector__XXX
 SG_ EPS_Lastinfo : 16|8@1+ (1,0) [0|253] "Unit_Amper"  Vector__XXX
 SG_ EPS_Unterstuetzungsleistung : 24|8@1+ (0.5,0) [0.0|100.0] "Unit_PerCent"  Vector__XXX
 SG_ EPS_Drehzahlreserve : 32|7@1+ (10,0) [0|1000] "Unit_DegreOfArcPerSecon"  Vector__XXX
 SG_ EPS_VZ_Drehzahlreserve : 39|1@1+ (1.0,0.0) [0.0|1] ""  Vector__XXX
 SG_ EPS_Leistungsanforderung : 40|1@1+ (1.0,0.0) [0.0|1] ""  Vector__XXX
 SG_ EPS_StartStopp_Info : 41|2@1+ (1.0,0.0) [0.0|3] ""  Motor_konv
 SG_ EPS_Motorstartverzoegerung : 43|2@1+ (1.0,0.0) [0.0|3] ""  Vector__XXX
 SG_ EPS_Warmstartunterstuetzung : 45|2@1+ (1.0,0.0) [0.0|3] ""  Vector__XXX
 SG_ EPS_Versorgungsspannung : 56|8@1+ (0.05,5.05) [5.05|17.70] "Unit_Volt"  Vector__XXX

BO_ 982 Licht_hinten_01: 8 Gateway_Max
 SG_ Licht_hinten_01_BZ : 0|4@1+ (1,0) [0|15] ""  Vector__XXX
 SG_ BCM2_Bremsl_durch_ECD_invers : 4|1@1+ (1.0,0.0) [0.0|1] ""  Vector__XXX
 SG_ BCM2_Bremsl_durch_ECD : 5|1@1+ (1.0,0.0) [0.0|1] ""  Motor_konv
 SG_ LH_Aussenlicht_def : 7|1@1+ (1.0,0.0) [0.0|1] ""  Vector__XXX
 SG_ LH_Standlicht_H_aktiv : 8|1@1+ (1.0,0.0) [0.0|1] ""  Vector__XXX
 SG_ LH_Parklicht_HL_aktiv : 9|1@1+ (1.0,0.0) [0.0|1] ""  Vector__XXX
 SG_ LH_Parklicht_HR_aktiv : 10|1@1+ (1.0,0.0) [0.0|1] ""  Vector__XXX
 SG_ LH_Bremslicht_H_aktiv : 11|1@1+ (1.0,0.0) [0.0|1] ""  Vector__XXX
 SG_ LH_Nebelschluss_aktiv : 12|1@1+ (1.0,0.0) [0.0|1] ""  Vector__XXX
 SG_ LH_Rueckfahrlicht_aktiv : 13|1@1+ (1.0,0.0) [0.0|1] ""  Vector__XXX
 SG_ LH_Blinker_HL_akt : 14|1@1+ (1.0,0.0) [0.0|1] ""  Vector__XXX
 SG_ LH_Blinker_HR_akt : 15|1@1+ (1.0,0.0) [0.0|1] ""  Vector__XXX
 SG_ LH_Blinker_li_def : 16|1@1+ (1.0,0.0) [0.0|1] ""  Vector__XXX
 SG_ LH_Bremsl_li_def : 17|1@1+ (1.0,0.0) [0.0|1] ""  Vector__XXX
 SG_ LH_Schlusslicht_li_def : 18|1@1+ (1.0,0.0) [0.0|1] ""  Vector__XXX
 SG_ LH_Rueckf_li_def : 19|1@1+ (1.0,0.0) [0.0|1] ""  Vector__XXX
 SG_ LH_Nebel_li_def : 20|1@1+ (1.0,0.0) [0.0|1] ""  Vector__XXX
 SG_ LH_Schluss_Brems_Nebel_li_def : 21|1@1+ (1.0,0.0) [0.0|1] ""  Vector__XXX
 SG_ LH_Schluss_Brems_Nebel_re_def : 22|1@1+ (1.0,0.0) [0.0|1] ""  Vector__XXX
 SG_ LH_Zusatzschlussl_def : 23|1@1+ (1.0,0.0) [0.0|1] ""  Vector__XXX
 SG_ LH_Schluss_Brems_li_def : 24|1@1+ (1.0,0.0) [0.0|1] ""  Vector__XXX
 SG_ LH_Schluss_Nebel_li_def : 25|1@1+ (1.0,0.0) [0.0|1] ""  Vector__XXX
 SG_ LH_SL_BRL_BLK_li_def : 26|1@1+ (1.0,0.0) [0.0|1] ""  Vector__XXX
 SG_ LH_Brems_Blk_li_def : 27|1@1+ (1.0,0.0) [0.0|1] ""  Vector__XXX
 SG_ LH_Diag_Status_re_def : 28|1@1+ (1.0,0.0) [0.0|1] ""  Vector__XXX
 SG_ LH_Diag_Status_li_def : 29|1@1+ (1.0,0.0) [0.0|1] ""  Vector__XXX
 SG_ LH_Diag_LED_li_def : 30|1@1+ (1.0,0.0) [0.0|1] ""  Vector__XXX
 SG_ LH_Diag_LED_re_def : 31|1@1+ (1.0,0.0) [0.0|1] ""  Vector__XXX
 SG_ LH_Blinker_re_def : 32|1@1+ (1.0,0.0) [0.0|1] ""  Vector__XXX
 SG_ LH_Bremsl_re_def : 33|1@1+ (1.0,0.0) [0.0|1] ""  Vector__XXX
 SG_ LH_Schlusslicht_re_def : 34|1@1+ (1.0,0.0) [0.0|1] ""  Vector__XXX
 SG_ LH_Rueckf_re_def : 35|1@1+ (1.0,0.0) [0.0|1] ""  Vector__XXX
 SG_ LH_Nebel_re_def : 36|1@1+ (1.0,0.0) [0.0|1] ""  Vector__XXX
 SG_ LH_Schluss_Brems_re_def : 40|1@1+ (1.0,0.0) [0.0|1] ""  Vector__XXX
 SG_ LH_Schluss_Nebel_re_def : 41|1@1+ (1.0,0.0) [0.0|1] ""  Vector__XXX
 SG_ LH_SL_BRL_BLK_re_def : 42|1@1+ (1.0,0.0) [0.0|1] ""  Vector__XXX
 SG_ LH_Brems_Blk_re_def : 43|1@1+ (1.0,0.0) [0.0|1] ""  Vector__XXX
 SG_ LH_Kennzl_def : 48|1@1+ (1.0,0.0) [0.0|1] ""  Vector__XXX
 SG_ LH_3_Bremsl_def : 49|1@1+ (1.0,0.0) [0.0|1] ""  Motor_konv
 SG_ LH_Nebel_mi_def : 50|1@1+ (1.0,0.0) [0.0|1] ""  Vector__XXX
 SG_ LH_Rueckf_mi_def : 51|1@1+ (1.0,0.0) [0.0|1] ""  Vector__XXX
 SG_ LH_Bremsl_li_ges_def : 54|1@1+ (1.0,0.0) [0.0|1] ""  Motor_konv
 SG_ LH_Bremsl_re_ges_def : 55|1@1+ (1.0,0.0) [0.0|1] ""  Motor_konv

BO_ 2527679634 LSH_02: 8 Gateway_Max
 SG_ LSH_Zuheizen : 38|1@1+ (1.0,0.0) [0.0|1] ""  Vector__XXX
 SG_ LSH_KVS_Ueberlauf : 39|1@1+ (1.0,0.0) [0.0|1] ""  Vector__XXX
 SG_ LSH_KVS : 40|13@1+ (1,0) [0|8191] "Unit_MilliLiter"  Vector__XXX
 SG_ LSH_KL_DBetr_Anf : 53|1@1+ (1.0,0.0) [0.0|1] ""  Vector__XXX
 SG_ LSH_Fehlerstatus : 54|3@1+ (1.0,0.0) [0.0|7] ""  Vector__XXX
 SG_ LSH_Heizleistung : 57|7@1+ (1,0) [0|100] "Unit_PerCent"  Vector__XXX

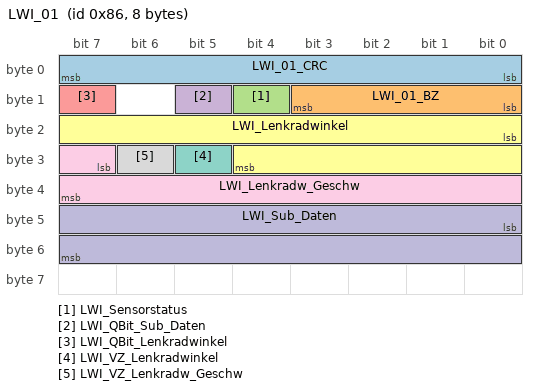
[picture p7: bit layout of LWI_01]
BO_ 134 LWI_01: 8 Gateway_Max
 SG_ LWI_01_CRC : 0|8@1+ (1,0) [0|255] ""  Vector__XXX
 SG_ LWI_01_BZ : 8|4@1+ (1,0) [0|15] ""  Vector__XXX
 SG_ LWI_Sensorstatus : 12|1@1+ (1.0,0.0) [0.0|1] ""  Motor_konv
 SG_ LWI_QBit_Sub_Daten : 13|1@1+ (1.0,0.0) [0.0|1] ""  Vector__XXX
 SG_ LWI_QBit_Lenkradwinkel : 15|1@1+ (1.0,0.0) [0.0|1] ""  Getriebe_DQ,Motor_konv
 SG_ LWI_Lenkradwinkel : 16|13@1+ (0.1,0) [0.0|800.0] "Unit_DegreOfArc"  Getriebe_DQ,Motor_konv
 SG_ LWI_VZ_Lenkradwinkel : 29|1@1+ (1.0,0.0) [0.0|1] ""  Getriebe_DQ,Motor_konv
 SG_ LWI_VZ_Lenkradw_Geschw : 30|1@1+ (1.0,0.0) [0.0|1] ""  Motor_konv
 SG_ LWI_Lenkradw_Geschw : 31|9@1+ (5,0) [0|2500] "Unit_DegreOfArcPerSecon"  Motor_konv
 SG_ LWI_Sub_Daten : 40|16@1+ (1,0) [0|65535] ""  Vector__XXX

BO_ 1153 MainUnit_01: 8 Gateway_Max
 SG_ ZR_LoGeWa_Event_Kombiwarnung : 0|4@1+ (1.0,0.0) [0.0|15] ""  Vector__XXX
 SG_ Nav_FoD_Status : 4|3@1+ (1.0,0.0) [0.0|7] ""  Motor_konv
 SG_ MIB_ASW_Diagnose : 7|1@1+ (1.0,0.0) [0.0|1] ""  Vector__XXX
 SG_ ZR_Lichter_Tag : 8|1@1+ (1.0,0.0) [0.0|1] ""  Vector__XXX
 SG_ MIB_Tongenerator_PH_verfuegbar : 9|3@1+ (1.0,0.0) [0.0|7] ""  Vector__XXX
 SG_ MMI_Counter_Bedienevent : 12|4@1+ (1.0,0.0) [0.0|15] ""  Vector__XXX
 SG_ DSSS_Warning : 16|5@1+ (1.0,0.0) [0.0|31] ""  Vector__XXX
 SG_ ZR_Kindersicherung_RSE : 21|1@1+ (1.0,0.0) [0.0|1] ""  Vector__XXX
 SG_ ZR_RSE_aktivieren : 22|1@1+ (1.0,0.0) [0.0|1] ""  Vector__XXX
 SG_ MMI_SDS_aktiv : 23|1@1+ (1.0,0.0) [0.0|1] ""  Vector__XXX
 SG_ MU_SecondDisplay : 24|3@1+ (1.0,0.0) [0.0|7] ""  Vector__XXX
 SG_ MMI_Telefon_aktiv : 27|1@1+ (1.0,0.0) [0.0|1] ""  Vector__XXX
 SG_ MMI_Gurt_Mic_ref : 28|1@1+ (1.0,0.0) [0.0|1] ""  Vector__XXX
 SG_ ZR_Sta_Inszenierung : 29|2@1+ (1.0,0.0) [0.0|3] ""  Vector__XXX
 SG_ ZR_AppConnect_Zustand : 31|1@1+ (1.0,0.0) [0.0|1] ""  Vector__XXX
 SG_ MU_Update_Time : 32|8@1+ (0.1,0) [0.0|25.5] "Unit_Hours"  Vector__XXX
 SG_ ZR_Parken_Sondermodus : 48|4@1+ (1.0,0.0) [0.0|15] ""  Vector__XXX

CM_ BO_ 960 "MQB";
CM_ BO_ 949 "ab MQB 7.4";
CM_ BO_ 1640 "ab MQB IS-4";
CM_ BO_ 1505 "ab MQB 7.3";
CM_ BO_ 779 "MQB";
CM_ BO_ 982 "MQB";
CM_ BO_ 134 "ab MQB mit CRC in Byte 1";

CM_ SG_ 2550530105 ISOx_LCU_SMH_Resp_Data "OffBoard Tester Diagnose Response LCU_SMH";

CM_ SG_ 2621833273 ISOx_LCU_SMH_Resp_FD_Data "OffBoard Tester Diagnose Response LCU_SMH";

CM_ SG_ 2549874806 ISOx_MO_01_Req_Data "Diagnose Request";

CM_ SG_ 2621440118 ISOx_MO_01_Req_FD_Data "Diagnose Request MO_01";

CM_ SG_ 2550005878 ISOx_MO_01_Resp_Data "OffBoard Tester Diagnose Response MO_01";

CM_ SG_ 2621571190 ISOx_MO_01_Resp_FD_Data "Diagnose Response MO_01";

CM_ SG_ 2549874821 ISOx_RSG_Req_Data "OffBoard Tester Diagnose Request RSG";

CM_ SG_ 2621440133 ISOx_RSG_Req_FD_Data "OffBoard Tester Diagnose Response RSG";

CM_ SG_ 2550005893 ISOx_RSG_Resp_Data "OffBoard Tester Diagnose Response RSG";

CM_ SG_ 2621571205 ISOx_RSG_Resp_FD_Data "OffBoard Tester Diagnose Response RSG";

CM_ SG_ 792 Kamera_FDD_Anz_Strassenleuchten "Anzahl der erkannten Straßenleuchten";
CM_ SG_ 792 Kamera_FDD_Eigenblend "Dieses Signal gibt an, ob von der Kamera eine Eigenblendung, z.B. Nebel, erkannt wird.";
CM_ SG_ 792 Kamera_FDD_Eigenblend_Guete "Diese Signal gibt an, welches Maß einer Eigenblendung vorliegt.";
CM_ SG_ 792 Kamera_FDD_Funktionsstatus "Status der Fahrzeugdetektion bei Dunkelheit";
CM_ SG_ 792 Kamera_FDD_Strassenbeleuchung "Status Straßenbeleuchungsdetektion";
CM_ SG_ 792 Kamera_FDD_Verkehrsrichtung "Gibt bei Nacht die auf Grund der entgegenkommenden Fahrzeuge erkannte Verkehrsrichtung an";
CM_ SG_ 792 Kamera_FSH_aktiv "Bei aktivierter (lokaler) Frontscheibenheizung wird die Scheibentemperaturmessung des Klimafeuchtesensors beeinflusst. Über das Signal wird dem Klima-SG mitgeteilt, dass die lokale Scheibenheizung aktiviert ist, um entsprechende Korrekturwerte bei der Sch";
CM_ SG_ 792 Kamera_Helligkeit "Helligkeitsinformation der gemessenen Aussenhelligkeit der multifunktionalen Kamera
Bei mehr als 10.000 Lux geht das Signal in die Sättigung.";
CM_ SG_ 792 Kamera_Systemzustand "Systemzustand der Kamera";
CM_ SG_ 792 VZE_Status_EDR "Das Signal zeigt den Status der VZE für den EventDataRecorder an.";

CM_ SG_ 1426 KY_Aktive_LFScans "Signalisierung eines aktiven Kessy-Scans (LF auf 125kHz) mit Angabe der Scanart";
CM_ SG_ 1426 KY_AnzKoord_Info "Signalisierung, ob beim Kessy-Scan ein Schlüssel gefunden wurde (1) oder nicht (2)";
CM_ SG_ 1426 KY_EasyClose_Abbruch "ID-Geber während HD-Zufahrt im Nahbereich EasyClose erkannt";
CM_ SG_ 1426 KY_EasyClose_Status "Signal zur LED Ansteuerung im HD-Verriegelungstaster für die Funktion EasyClose.";
CM_ SG_ 1426 KY_Fzg_Verlassen_erkannt "Fahrer/Schlüssel hat das Fahrzeug verlassen und FT wurde geschlossen";
CM_ SG_ 1426 KY_Fzg_Zugang_erkannt "Fahrer/Schlüssel hat Fahrzeug betreten und die FT geschlossen";
CM_ SG_ 1426 KY_Gestik_HD "Aktive Funktion (Gestikgesteuerte Heckklappe) im Kessy-SG";
CM_ SG_ 1426 KY_Gong_600 "Gong zum Meldungstext (1=aktiv)";
CM_ SG_ 1426 KY_HD_Auffahrt "Auffahrt HD nach Wiedereintritt ID-Geber in EasyClose Nahbereich";
CM_ SG_ 1426 KY_HD_Zufahrt "Zufahrt HD nach erfolgreicher Funktion EasyClose";
CM_ SG_ 1426 KY_ID_Geber1_im_Fzg "1 = ID-Geber 1 im Innenraum erkannt";
CM_ SG_ 1426 KY_ID_Geber2_im_Fzg "1 = ID-Geber 2 im Innenraum erkannt";
CM_ SG_ 1426 KY_ID_Geber3_im_Fzg "1 = ID-Geber 3 im Innenraum erkannt";
CM_ SG_ 1426 KY_ID_Geber4_im_Fzg "1 = ID-Geber 4 im Innenraum erkannt";
CM_ SG_ 1426 KY_ID_Geber_Suche "1 = Transponder Scan aktiv";
CM_ SG_ 1426 KY_LF_Aktiv "LF Schluesselkommunikation
";
CM_ SG_ 1426 KY_Meldungen "Kessy-Meldungen:
0 = keine Meldung
1 = Meldung: 'Schlüssel nicht gefunden!' bei Kl.15 ein
2= Meldung: 'Schlüssel im Kofferraum!'
3 = Meldung: 'Schlüssel im Fahrzeug'
4 = Meldung: 'KESSY defekt'
5-15: tbd";
CM_ SG_ 1426 KY_Passiv_Autolock "Aktive Funktion (Passiv Autolock) im Kessy-SG";
CM_ SG_ 1426 KY_Passiv_Autolock_Akt "1 = Funktionszustand im Kessy-SG: 'Passiv Autolock / Autounlock'";
CM_ SG_ 1426 KY_Passiv_Autolock_Menue "1 = Menue-Eintrag 'Passiv Autolock / Autounlock' aktivieren";
CM_ SG_ 1426 KY_Passiv_Autounlock "Aktive Funktion (Passiv Autounlock) im Kessy-SG";
CM_ SG_ 1426 KY_Schluesselposition_1 "Status des ID-Gebers 1 aus der letzten durchgeführten Schlüsselsuche für Remote Parkfunktionen

0 = nicht_gefunden
1 = im_Innenraum_gefunden
2 = im_Außenraum_gefunden_nah, Distanz <= parametrierter Schwelle
3 = im_Außenraum_gefunden_fern, Distanz > p";
CM_ SG_ 1426 KY_Schluesselposition_2 "Status des ID-Gebers 2 aus der letzten durchgeführten Schlüsselsuche für Remote Parkfunktionen

0 = nicht_gefunden
1 = im_Innenraum_gefunden
2 = im_Außenraum_gefunden_nah, Distanz <= parametrierter Schwelle
3 = im_Außenraum_gefunden_fern, Distanz > p";
CM_ SG_ 1426 KY_Schluesselposition_3 "Status des ID-Gebers 3 aus der letzten durchgeführten Schlüsselsuche für Remote Parkfunktionen

0 = nicht_gefunden
1 = im_Innenraum_gefunden
2 = im_Außenraum_gefunden_nah, Distanz <= parametrierter Schwelle
3 = im_Außenraum_gefunden_fern, Distanz > p";
CM_ SG_ 1426 KY_Schluesselposition_4 "Status des ID-Gebers 4 aus der letzten durchgeführten Schlüsselsuche für Remote Parkfunktionen

0 = nicht_gefunden
1 = im_Innenraum_gefunden
2 = im_Außenraum_gefunden_nah, Distanz <= parametrierter Schwelle
3 = im_Außenraum_gefunden_fern, Distanz > p";
CM_ SG_ 1426 KY_Schluesselposition_5 "Status des ID-Gebers 5 aus der letzten durchgeführten Schlüsselsuche für Remote Parkfunktionen

0 = nicht_gefunden
1 = im_Innenraum_gefunden
2 = im_Außenraum_gefunden_nah, Distanz <= parametrierter Schwelle
3 = im_Außenraum_gefunden_fern, Distanz > p";
CM_ SG_ 1426 KY_Schluesselposition_6 "Status des ID-Gebers 6 aus der letzten durchgeführten Schlüsselsuche für Remote Parkfunktionen

0 = nicht_gefunden
1 = im_Innenraum_gefunden
2 = im_Außenraum_gefunden_nah, Distanz <= parametrierter Schwelle
3 = im_Außenraum_gefunden_fern, Distanz > p";
CM_ SG_ 1426 KY_Schluesselposition_7 "Status des ID-Gebers 7 aus der letzten durchgeführten Schlüsselsuche für Remote Parkfunktionen

0 = nicht_gefunden
1 = im_Innenraum_gefunden
2 = im_Außenraum_gefunden_nah, Distanz <= parametrierter Schwelle
3 = im_Außenraum_gefunden_fern, Distanz > p";
CM_ SG_ 1426 KY_Schluesselposition_8 "Status des ID-Gebers 8 aus der letzten durchgeführten Schlüsselsuche für Remote Parkfunktionen

0 = nicht_gefunden
1 = im_Innenraum_gefunden
2 = im_Außenraum_gefunden_nah, Distanz <= parametrierter Schwelle
3 = im_Außenraum_gefunden_fern, Distanz > p";
CM_ SG_ 1426 KY_Schluesselposition_9 "Status des ID-Gebers 9 (MDK) aus der letzten durchgeführten Schlüsselsuche für Remote Parkfunktionen

0 = nicht_gefunden
1 = im_Innenraum_gefunden
2 = im_Außenraum_gefunden_nah, Distanz <= parametrierter Schwelle
3 = im_Außenraum_gefunden_fern, Dista";
CM_ SG_ 1426 KY_Startknopf_Bel "Startknopf beleuchten";
CM_ SG_ 1426 KY_StartStopp_Info "Stopp-Freigabe und Start-Anforderung an den Start-Stopp-Koordinator";

CM_ SG_ 960 BCM_Ausparken_Betrieb "Anforderung zur erneuten Lampenaufprüfung und Anzeige von Warnhinweisen nach einem pilotierten Ausparkvorgang (Trigger: fallende Flanke)";
CM_ SG_ 960 BCM_Remotestart_Betrieb "Zeigt den Status des RemoteStarts an, d.h. KL15_RSt ist aktiviert und der Motorlauf ist im RSt-Betrieb aktiv.";
CM_ SG_ 960 BCM_Remotestart_KL15_Anf "Zeigt den Status der Aktivierung der KL15_RST durch das BCM an.";
CM_ SG_ 960 BCM_Remotestart_MO_Start "Nachdem das BCM die Remotestart MSG Freigabe sicher erkannt hat, fordert das BCM wiederum über dieses Signal vom MSG einen Motorstart durchzuführen.";
CM_ SG_ 960 Klemmen_Status_01_BZ "4bit Botschaftszaehler; wird in jeder Sendebotschaft inkrementiert";
CM_ SG_ 960 Klemmen_Status_01_CRC "Für MLB:
'Berechnung siehe Lastenheft 'Kommunikationsabsicherung für FlexRay und CAN''

Ab MQB und MLBevo:
'Berechnung siehe Lastenheft 'End-to-End Kommunikationsabsicherung''

Endwerte siehe Begleitdokument 'S-PDU Kennungsfolgen'";
CM_ SG_ 960 KST_Fahrerhinweis_1 "Signalisierung Fahrerhinweis 1 der Klemmensteuerung an das Kombi";
CM_ SG_ 960 KST_Fahrerhinweis_2 "Signalisierung Fahrerhinweis 2 der Klemmensteuerung an das Kombi";
CM_ SG_ 960 KST_Fahrerhinweis_4 "Signalisierung Fahrerhinweis 4 der Klemmensteuerung an das Kombi";
CM_ SG_ 960 KST_Fahrerhinweis_5 "Anzeigesignal für RemoteStart";
CM_ SG_ 960 KST_Fahrerhinweis_6 "Signal aktiviert die Kombi-Anzeigeinstrumente (Drehzahl, Tankinhalt, Kühlmitteltemperatur) während aktiviertem RemoteStart-Betrieb";
CM_ SG_ 960 KST_Warn_P1_ZST_def "Kombi Prio Warnung Klemmensteuerung 
Zündschloß defekt, Service aufsuchen!";
CM_ SG_ 960 KST_Warn_P2_ZST_def "Kombi Prio Warnung Klemmensteuerung
Zündschloß defekt!
";
CM_ SG_ 960 RSt_Fahrerhinweise "Über das Signal fordert das BCM Fahrerhinweise im Kombi für die Funktion RemoteStart an.";
CM_ SG_ 960 ZAS_Kl_15 "Klemme 15: Zuendung (SW-Kl.15)
";
CM_ SG_ 960 ZAS_Kl_50_Startanforderung "Klemme 50: Startwunsch Fahrer
";
CM_ SG_ 960 ZAS_Kl_Infotainment "Separate Klemmeninformation für das Infotainment. Signal entspricht im wesentlichen einer Klemme S Information, kann aber über einen Vor - bzw. Nachlauf zu Klemme S verfügen. 
Ein konkreter Anwendungsfall für einen Nachlauf ist die Abschaltung der Klemme";
CM_ SG_ 960 ZAS_Kl_S "Klemme S: S-Kontakt (Schluessel steckt)
";
CM_ SG_ 960 ZAS_Kl_X "Klemme 75
";

CM_ SG_ 2463978753 Klemmen_Status_02_BZ "4bit Botschaftszähler, wird mit jeder Sendebotschaft inkrementiert";
CM_ SG_ 2463978753 Klemmen_Status_02_CRC "Für MLB:
Berechnung siehe Lastenheft 'Kommunikationsabsicherung für FlexRay und CAN'
Ab MQB und MLBevo:
Berechnung siehe Lastenheft 'End-to-End Kommunikationsabsicherung'

Endwerte siehe Begleitdokument 'S-PDU Kennungsfolgen'";
CM_ SG_ 2463978753 KST_ComfortReadyStatus "Zustand des ComfortReadyStatus über den Komfortfunktionen aktiviert werden können.";
CM_ SG_ 2463978753 KST_Freigabe_Zustand "Gibt den Sperr- bzw. Freigabezustand der Klemmensteuerung während SW-Update (z. B. Infotainment) an";
CM_ SG_ 2463978753 KST_Sonderzustand_Anforderung "Hiermit wird die aktive bzw. aktuell angeforderte (s. KST_Sonderzustand_Status) Sonderfunktion identifiziert";
CM_ SG_ 2463978753 KST_Sonderzustand_Status "Hiermit wird signalisiert, dass eine Sonderfunktion aktiv ist und die Klemme 15 durch diese angefordert wurde bzw. ein Übergang von Sonderfunktionen stattfindet";
CM_ SG_ 2463978753 KST_WFS_Fahrfreigabe_Anforderung "Hiermit wird den Wegfahrsperren-Teilnehmern signalisiert welche Art der Fahrfreigabe von der anfordernden Sonderfunktion benötigt wird";

CM_ SG_ 1420 Klemmen_Steuerung_01_BZ "4bit Botschaftszaehler; wird in jeder Sendebotschaft inkrementiert";
CM_ SG_ 1420 Klemmen_Steuerung_01_CRC "Ab MQB und MLBevo:
'Berechnung siehe Lastenheft 'End-to-End Kommunikationsabsicherung''

Endwerte siehe Begleitdokument 'S-PDU Kennungsfolgen'";
CM_ SG_ 1420 KST_Anf_Klemme_15 "Anforderung der Klemme 15 an das BCM. Signal wird zur Plausibilisierung parallel zum Klemmensignal auf dem CAN übertragen.";
CM_ SG_ 1420 KST_Anf_Klemme_50 "Anforderung der Klemme 50 an das MSG. Signal wird zur Plausibilisierung parallel zum Klemmensignal auf dem CAN übertragen.";
CM_ SG_ 1420 KST_Anf_Klemme_S "Anforderung der Klemme S an das BCM. Signal wird zur Plausibilisierung parallel zum Klemmensignal auf dem CAN übertragen.";
CM_ SG_ 1420 KST_Anf_Klemmenfreigabe_ELV "Klemmensteuerung fordert Klemmen-Freigabe durch die ELV an.";
CM_ SG_ 1420 KST_Anf_Klemmenfreigabe_WFS "Anforderung der Freigabe von der WFS zum Einschalten von Klemme 15 und Klemme S";
CM_ SG_ 1420 KST_Anf_ZV_Verriegelung "Neuer Verriegelungstrigger für die ZV nach der automatischen Klemmenabschaltung.

Wird bei Kessyfahrzeugen mit StartStop ein aktiver Stop-Mode und Fahrerverlassen erkannt, startet ein 30 Sekunden-Timer. Innerhalb dieser 30 Sekunden hat der Fahrer die Mö";
CM_ SG_ 1420 KST_Anzeige_Klemmenzustand "Klemmensteuerung zeigt (Fehler-)zustände nach/während Update Infotainment bzgl. Klemme 50 an";
CM_ SG_ 1420 KST_aut_Abschaltung_Zuendung "Falls bei eingeschalteter Zündung das Abblendlicht aktiv war, muss nach der automatischen Abschaltung der Kl_15 & Kl_S, dass Standlicht aktiv bleiben. Das Signal sendet die Information, dass eine automatische Abschaltung der Kl_15 und Kl_S erfogt.";
CM_ SG_ 1420 KST_Txt_Komfortabschaltung "Dieses Signal fordert im Kombi die Meldung an, die den Fahrer über die ausgeführte automatische Zündungsabschaltung informiert. Signal wird für10s gesendet.";
CM_ SG_ 1420 KST_Txt_P_Gang "Text: 'Wählhebel in Position P bringen!'";
CM_ SG_ 1420 KST_Txt_Panikabschaltung "Text: 'Notabschaltung''";
CM_ SG_ 1420 KST_Txt_Werkstatt "Text: 'Klemmensteuerung! Werkstatt!'";
CM_ SG_ 1420 KST_Unterdr_Zuendungsmeldung "Bei aktivem Signal soll die Zündungsmeldung durch das Kombi unterdrückt werden.";
CM_ SG_ 1420 KST_ZAT_betaetigt "Zündanlass-Taster (ZAT) betätigt";
CM_ SG_ 1420 KST_Zuendungswarnung "Bei aktivem Signal soll je nach gesetztem Status eine Warnung durch das Kombi ausgegeben werden";
CM_ SG_ 1420 Relais_VoKo_angesteuert "Signal zur Rückmeldung, ob das Relais für die Verbraucher von erweiterte Voko / RemoteStart angesteuert wird.";
CM_ SG_ 1420 RSt_Anforderung_HMS "Anforderung vom RSt (Remote Start) an das HMS (Haltemanagement System)";

CM_ SG_ 949 KL_AC_Schalter "AC Schalter
";
CM_ SG_ 949 KL_AirCleaner_aktiv "Status des Zustands der AirCare Funktion (Umluft) im Fahrzeug";
CM_ SG_ 949 KL_Anf_KL "Anforderung Kühlerlüfter der Klimaanlage in Prozent

";
CM_ SG_ 949 KL_Anf_KV "Anforderung des Kühlerrollos in %";
CM_ SG_ 949 KL_Ausstattung_Klima "Austtattungsart der Klimabedienung";
CM_ SG_ 949 KL_Charisma_FahrPr "MLBevo: Aktuelles Fahrprogramm des Charisma-Teilnehmers (siehe Systemlastenheft Drive Select)
MQB: Istwert der Kennlinie (siehe Systemlastenheft MQB FPA)";
CM_ SG_ 949 KL_Charisma_Status "Charisma Systemstatus des Charisma-Teilnehmers

Wert 0x3 ist nur für Fahrzeuge ab MQB relevant";
CM_ SG_ 949 KL_Drehz_Anh "Drehzahlanhebung vom Motor angefordert

";
CM_ SG_ 949 KL_el_Zuheizer_Stufe "Vorgabe für Motorsteuergeraet PTC-Stufe; im MLB-B8 und MQB nur Stufe 0...3

";
CM_ SG_ 949 KL_Freilauf_Info "Freilauf Informationssignal von Klima zum Freilaufkoordinator. Klima kann über dieses Signal den Freilauf freigeben, verhindern bzw. explizit anfordern.";
CM_ SG_ 949 KL_Kompressorkupplung_linear "Sollwert zur Ansteuerung der Kompressorkupplung";
CM_ SG_ 949 KL_Last_Kompr "Aktuelles Verlustmoment der Klimaanlage bezogen auf die Kurbelwelle. Wird der Klimakompressor nicht angesteuert, ist das Schleppmoment bezogen auf die Kurbelwelle zu senden.";
CM_ SG_ 949 KL_nachtr_Stopp_Anf "Dieses Signal dient dem Motor als Trigger, dass ein nachträglicher Motorstopp eingeleitet werden kann, wenn es die Bedingungen des StSt Koordinators dies zulassen. ";
CM_ SG_ 949 KL_Spannungs_Anf "Forderung des Klima-SG's zur Spannungsanhebung.";
CM_ SG_ 949 KL_StartStopp_Info "Stopp-Freigabe und Start-Anforderung an den Start-Stopp-Koordinator";
CM_ SG_ 949 KL_T_Charge "Signal für Tastenbetätigung Charge-Taste (SOC Increasing)";
CM_ SG_ 949 KL_Thermomanagement "Stufen des Thermomanagements;
Bei Klemme 15 AUS und erkannten Timeout zum Klimabedienteil (z.B. Klimabedienteil während des Motorsteuergeräte-Kommunikations-Nachlaufs bereits im NM-Zustand ¿Bus Sleep¿)
erfolgt keine Ansteuerung der Wasserpumpe durch die";
CM_ SG_ 949 KL_Variante_Standheizung "Identifikation der Variante der Standheizungen zur Berechnung der energetischen Zielzeit";
CM_ SG_ 949 KL_Vorwarn_Komp_ein "Vorwarnung Kompressor ein; 140ms vorher; Information für Motor zum Aufbau Momentenreserve";
CM_ SG_ 949 KL_Vorwarn_Zuheizer_ein "Vorwarnung Zuheizerbetrieb
";
CM_ SG_ 949 KL_Zustand "Beschreibt den Zustand des Klima-/Heizungsbedienteils. (OFF-Mode Bedienteil)

PAG (MLB): Beschreibt den Zustand des Kompressors";

CM_ SG_ 1640 FSH_Taster "Tasterbetätigung Frontscheibenheizung
";
CM_ SG_ 1640 HSH_Taster "An-/Abforderung Heckscheibenheizung über spezielles Tastersignal
";
CM_ SG_ 1640 KL_Beschlagsgefahr "Beschlagsgefahr auf der Frontscheibe im Bereich des Spiegelfusses. Dient zur präventiven Ansteuerung der  Kamera-Scheibenheizung, um Kamera-Blindheit zu vermeiden
PHEV: volle Leistungsfreigabe 
HV Heizer und HV EKK bei Scheibenbeschlag ";
CM_ SG_ 1640 KL_Geblspng_Fond_Soll "Ausgabe des Sollwertes für die Spannung des Klimagebläsemotores hinten.






";
CM_ SG_ 1640 KL_Geblspng_Soll "Ausgabe des Sollwertes für die Spannung des Klimagebläsemotores vorne.







";
CM_ SG_ 1640 KL_I_Geblaese "Stromaufnahme Gebläse";
CM_ SG_ 1640 KL_Kompressorstrom_soll "Sollvorgabe Klima-Kompressorstrom";
CM_ SG_ 1640 KL_LRH_Stufe "Eingestellte Temperaturstufe der Lenkradheizung";
CM_ SG_ 1640 KL_LRH_Taster "Tasterbetätigung Lenkradheizung";
CM_ SG_ 1640 KL_PTC_Verbauinfo "Im Klima- bzw. Heizungsbedienteil wird der Verbau eines PTCs und dessen elektr. Leistungsklasse codiert";
CM_ SG_ 1640 KL_SIH_Soll_li "Einstellung Sitzheizung Fahrer (0...6)";
CM_ SG_ 1640 KL_SIH_Soll_re "Einstellung Sitzheizung Beifahrer (0...6)";
CM_ SG_ 1640 KL_SIL_Soll_li "Einstellung Sitzlüftung Fahrer (0...6)";
CM_ SG_ 1640 KL_SIL_Soll_re "Einstellung Sitzlüftung Beifahrer (0...6)";
CM_ SG_ 1640 KL_Umluftklappe_Status "Status Umluftklappe";
CM_ SG_ 1640 KL_Zuheizer_Freigabe "Freigabe Zuheizer
";
CM_ SG_ 1640 KRH_Soll_li "Ausgabe des Sollwertes für die Kopfraumheizung links.";
CM_ SG_ 1640 KRH_Soll_re "Ausgabe des Sollwertes für die Kopfraumheizung rechts.";

CM_ SG_ 1511 KL_BattKond_WaPu_DZMax "Maximal-Drehzahl der Wasserpumpe im Batteriekühlkreislauf als Vorgabe für BMS";
CM_ SG_ 1511 KL_EKK_Strom "EKK  Stromaufnahme (Hochvolt)";
CM_ SG_ 1511 KL_Fehler_HV_EKK "Fehlersignal bei Erkennung HV Fehler am elektrischen Klimakompressor EKK
Sender: Klima MQB (evtl. Wärmepumpen SG MQB, OBD SG MQB)";
CM_ SG_ 1511 KL_Fehler_HV_Heizer "Fehlersignal bei Erkennung HV Fehler am HV Heizer
Sender: Klima MQB (evtl. Wärmepumpen SG MQB, OBD SG MQB)";
CM_ SG_ 1511 KL_HV_Heizer_Strom "Strom HV-Heizer für Reichweitenberechnung";
CM_ SG_ 1511 KL_KM_ASV_01_Status "Schaltstatus Kältemittel Absperrventil
VW370/9 PHEV = Ventil vor Verdampfer";
CM_ SG_ 1511 KL_KM_ASV_02_Status "Schaltstatus Kältemittel Absperrventil
VW370/9 PHEV = Ventil vor Chiller";
CM_ SG_ 1511 KL_Pumpe_02_Soll "Anforderung KM-Pumpe Klimakreislauf
Init (126dec)      = 0% Ansteuerung Pumpe
Fehler (127dec) = 100% Ansteuerung Pumpe";
CM_ SG_ 1511 KL_Senderkennung "Gibt an, welches SG (Klima oder WP) die Botschaft sendet";
CM_ SG_ 1511 KL_Status_EoHVL_EKK "Erkennung einer offenen HV-Leitung (EoHVL). Bewertet anhand einer Spannungsgrenze.";
CM_ SG_ 1511 KL_Status_EoHVL_EKK_2 "Erkennung einer offenen HV-Leitung (EoHVL). Bewertet anhand einer Spannungsgrenze.";
CM_ SG_ 1511 KL_Status_EoHVL_Heizer "Erkennung einer offenen HV-Leitung (EoHVL). Bewertet anhand einer Spannungsgrenze.";
CM_ SG_ 1511 KL_Status_EoHVL_Heizer_2 "Erkennung einer offenen HV-Leitung (EoHVL). Bewertet anhand einer Spannungsgrenze.";
CM_ SG_ 1511 KL_Ventil_03_Soll "Anforderung Batteriebypass-Ventil im Klimakreislauf";
CM_ SG_ 1511 KL_Ventil_10_Status "Status Ventil_Wärmepumpe; 
nicht angesteuert: Motor- und Heizkreislauf getrennt; 
angesteuert: Motor- und Heizkreislauf verbunden.";
CM_ SG_ 1511 KL_Vorwarn_HVHeizer_Leistung "Vorwarnung der Heizerleistung für die Stromregelung. Botschaft: Klima_EV_03, da das Signal entweder vom Klimasteuergerät oder dem Wärmepumpensteuergerät gesendet werden soll.";
CM_ SG_ 1511 WP_KJ_Soll "Anforderung der Kuehlerjalousiestellung durch Waermepumpen SG";
CM_ SG_ 1511 WP_Kuehlerluefter_Anf "Anforderung Kühlerlüfter durch Wärmepumpen SG";

CM_ SG_ 1514 KBT_Defrost_aktiv "Defrostmodus im KBT aktiv";
CM_ SG_ 1514 KL_Fehler_NTKreis "Über dieses Fehlersignal werden andere Steuergeräte am NT-Kreis über einen Fehler in der Klimatisierung informiert und können so Folgefehlereinträge vermeiden.";
CM_ SG_ 1514 KL_Heizbedarf "Bedarf an Heizmenge für Innenraumklimatisierung";
CM_ SG_ 1514 KL_Innentemp_KBT_Sensor "Temperatur Innenraum vor Klimabedienteil";
CM_ SG_ 1514 KL_KLE_Fehler_Anf "Anfrage der Klimatisierung an das MSG, ob ein Fehler im Kühlerlüfter vorliegt.";
CM_ SG_ 1514 KL_Kundenwunsch_Kuehlen "KBT meldet aktiven Kühlungswunsch an Waermepumpen SG";
CM_ SG_ 1514 KL_Mot_Tk_Soll_li "Stellung Temperaturklappe Soll links";
CM_ SG_ 1514 KL_Mot_Tk_Soll_re "Stellung Temperaturklappe Soll rechts";
CM_ SG_ 1514 KL_OBD_Status "Dieses Bit steuert die MIL-Lampe an (Motorsteuergerät reicht diese Info an Kombi weiter).";
CM_ SG_ 1514 KL_Standklima_RemoteModus "Modus (Lüften, Kühlen, Heizen) der Standklimatisierung (Innenraum) zur Remote Anzeige";
CM_ SG_ 1514 KL_Standklima_Status_02 "Status der Standklimatisierung (Innenraum)";
CM_ SG_ 1514 KL_Standklima_Status_03 "Standklimatisierung Innenraum";
CM_ SG_ 1514 KL_VK_Anf "Starten einer Standklimatisierung ausgehend von der Climatronic Richtung Lademanagment.";
CM_ SG_ 1514 KL_VK_Betriebsdauer "Berechnete notwendige Betriebsdauer der Vorkonditionierung des Innerraumes (Standklimatisierung). ";
CM_ SG_ 1514 KL_Vorkond_Strategie "Strategie der Vorkonditionierung des Innenraums";

CM_ SG_ 2589283627 KL_EKK_1_VerbautStatus "Verbaustatus EKK1";
CM_ SG_ 2589283627 KL_EKK_2_VerbautStatus "Verbau Information zweiter EKK";
CM_ SG_ 2589283627 KL_Heizen_Status "Anforderungspriorität Unterkomponente zur Priorisierung und Leistungsverteilung im HV-EM";
CM_ SG_ 2589283627 KL_HV_Energie_Anf "Anforderung HV - Energiebedarf, für VoKo 
";
CM_ SG_ 2589283627 KL_HVH_1_VerbautStatus "Verbau Information HV_Heizer1";
CM_ SG_ 2589283627 KL_HVH_2_VerbautStatus "Verbau Information zusaetzlicher Heizer";
CM_ SG_ 2589283627 KL_IstLeistung "Gesamt-Ist-Leistung für Komfort- und Thermomanagement";
CM_ SG_ 2589283627 KL_K_Status "Satus der Klimatisierung und Wärmepumpe wird ausgegeben.";
CM_ SG_ 2589283627 Kl_Klima_Aktiv "Rückmeldung über HV Klimaaktivität durch Klimasteuergerät für BEV/PHEV";
CM_ SG_ 2589283627 KL_Kuehlungs_Status "Anforderungspriorität Unterkomponente zur Priorisierung und Leistungsverteilung im HV-EM";
CM_ SG_ 2589283627 KL_Leistung_Klima_Anf "Leistungsanforderung ans HVEM von Klima";
CM_ SG_ 2589283627 KL_Status_Battkuehlung "Statusinformation über den akuellen Zustand der aktiven Batteriekühlung durch die Klimaanlage";
CM_ SG_ 2589283627 KL_Temp_Kundenwunsch "Temeratur, die auf der Fahrerseite der Climatronic vom Kunden vorgegeben wird.";
CM_ SG_ 2589283627 KL_Texte "Ein Defizit in Heizleistung bzw. Kühlleistung soll dem Kunden angezeigt werden";
CM_ SG_ 2589283627 TME_HVEM_HV_Anf "Anforderung 'HV-Netz aktivieren' wegen Innenraumkonditionierung mit HV-Komponente";

CM_ SG_ 2589283574 KL_OBD_Status_Auth "Ansteuerung der MIL-Lampe über den MIL-Master (Motorsteuergerät)
Redundantes Signal (SOK gesichert) zu KL_OBD_Status";
CM_ SG_ 2589283574 OBDProtocol_Klima "Bestätigung des aktuell umgesetzten Scan Tool Protokolls";
CM_ SG_ 2589283574 SOK_Klima_EV_10_Signatur "Signatur im Rahmen der durch SOK geschützen Broadcast-Kommunikation

Geschützte Funktion: OBD-Malfunction Indicator Light (MIL)
Geschützte PDU: Klima_EV_10";

CM_ SG_ 1505 BCM1_Aussen_Temp_ungef "ungefilterter Wert des Aussentemperatursensors
";
CM_ SG_ 1505 BCM1_FStatus_Aussentemp_ungef "Fehlerstatus für Aussentemperatur (Kombianzeige)";
CM_ SG_ 1505 BCM1_Kompressorstrom_ist "IST-Strom vom Klima-Kompressor";
CM_ SG_ 1505 BCM1_OBD_FStatus_ATemp "Fehlerstatus Umgebungstemperatursensor (OBD relevanter Sensor)
";
CM_ SG_ 1505 BCM1_PTC_stufig_Status "Status des BCM1-Heizverbrauchers PTC (stufig)";
CM_ SG_ 1505 BCM_Heizungsabsperrventil_Status "Das Signal beschreibt den Zustand des Heizungsabsperrventils, welches als Portexpander vom BCM1 elektrisch angesteuert wird.";
CM_ SG_ 1505 BCM_Heizungspumpe_Status "Das Signal beschreibt den Zustand der Heizungspumpe, welche als Portexpander vom BCM1 elektrisch angesteuert wird.";
CM_ SG_ 1505 BCM_Kompressorkupplung_Status "Das Signal beschreibt den Zustand der Klimakompressorkupplung, welche als Portexpander vom BCM1 elektrisch angesteuert wird.";

CM_ SG_ 1513 AAU_Geblaese "Ansteuergrad des Gebläses";
CM_ SG_ 1513 DS_Kaeltemittel_P "Drucksensor Kältemittel Druck, das Signal wird bei Kl.15 AUS mit dem letzten empfangenen Wert gesendet";
CM_ SG_ 1513 DS_Kaeltemittel_P_WP "Drucksensor Kältemittel Druck, das Signal wird bei Kl.15 AUS mit dem letzten empfangenen Wert gesendet für die Wärmepumpe";
CM_ SG_ 1513 DS_Status "Status des Drucksensors (= LIN-Slave BCM1);
bei Kl.15 AUS wird für 4s noch der letzte Wert gesendet, danach wird das Signal mit dem Wert 3 (= Fehler) gesendet";
CM_ SG_ 1513 ION_Status "Status Hochspannung Ionisator";
CM_ SG_ 1513 ION_Status_LED "Status Funktions LED";
CM_ SG_ 1513 ION_Status_Taster "Status Kundenwunsch (Bedientaster) Ionisator";

CM_ SG_ 2549088272 Gateway_Abschaltstufe "Funktionseinschränkung aufgrund aktiver Abschaltstufe";
CM_ SG_ 2549088272 Gateway_KompSchutz "Funktionseinschränkung aufgrund Komponentenschutz aktiv";
CM_ SG_ 2549088272 Gateway_Nachlauftyp "Abgebildet wird die von der Hardware vorgegebene Möglichkeit, die Kommunikation nach Klemme 15 = AUS aufrecht zu erhalten. Es wird ein Init-Wert gesendet.";
CM_ SG_ 2549088272 Gateway_Transport_Mode "Funktionseinschränkung aufgrund aktivem Transport Mode und/oder Transport Schutz";
CM_ SG_ 2549088272 GW_KD_Fehler "Kundendienstfehlerbit Gateway zur Anzeige eines im Gateway abgelegten Fehlerspeichereintrages.";
CM_ SG_ 2549088272 KN_GW_DiagPfad "Kennzeichnung der Diagnosefähigkeit des BusInterfaces eines Steuergerätes (Knoten)
Umfang LAH 80127

Bei Nutzung des Signal explizit pro angebundenem BusInterface zu setzen:
MQB auf Diag-CAN = 0 (aktiv)
MLBevo auf Diag-CAN = 0 (aktiv)
alle weiteren ";
CM_ SG_ 2549088272 NM_Gateway_Wakeup "enthält die Weckursache; stehen mehrere Weckursachen parallel an, dann muss der kleinste Wert übertragen werden";

CM_ SG_ 2549088375 Getriebe_01_Abschaltstufe "Funktionseinschränkung aufgrund aktiver Abschaltstufe";
CM_ SG_ 2549088375 Getriebe_01_KD_Fehler "Bei gesetztem Bit ist mindestens ein Kundendienstfehler eingetragen";
CM_ SG_ 2549088375 Getriebe_01_Transport_Mode "Funktionseinschränkung aufgrund aktivem Transport Mode und/oder Transport Schutz";
CM_ SG_ 2549088375 Getriebe_KompSchutz "Funktionseinschränkung aufgrund Komponentenschutz aktiv";
CM_ SG_ 2549088375 Getriebe_Nachlauftyp "Abgebildet wird die von der Hardware vorgegebene Möglichkeit, die Kommunikation nach Klemme 15 = AUS aufrecht zu erhalten. Es wird ein Init-Wert gesendet.
0 = Kommunikation nur bei KL15=EIN (kein Nachlauf, nicht weckfähig)
1 = Kommunikation nach KL15=AU";
CM_ SG_ 2549088375 KN_Getriebe_01_BusKnockOut "Ausgabe des BusKnockout-Status";
CM_ SG_ 2549088375 KN_Getriebe_01_BusKnockOutTimer "Ausgabe des BusKnockOut-Timer";
CM_ SG_ 2549088375 KN_Getriebe_01_DiagPfad "Kennzeichnung der Diagnosefähigkeit des BusInterfaces eines Steuergerätes (Knoten)
Umfang LAH 80127

Bei Nutzung des Signal explizit pro angebundenem BusInterface zu setzen:
MQBw_Baseline auf A-CANFD = 0 (aktiv)";
CM_ SG_ 2549088375 KN_Getriebe_01_ECUKnockOut "Ausgabe des ECUKnockout-Status";
CM_ SG_ 2549088375 KN_Getriebe_01_ECUKnockOutTimer "Ausgabe des ECUKnockOut-Timer";
CM_ SG_ 2549088375 NM_Getriebe_01_Wakeup "enthält die Weckursache; stehen mehrere Weckursachen parallel an, dann muss der kleinste Wert übertragen werden";

CM_ SG_ 2549088374 KN_MO_DiagPfad "Kennzeichnung der Diagnosefähigkeit des BusInterfaces eines Steuergerätes (Knoten)
Umfang LAH 80127

Bei Nutzung des Signal explizit pro angebundenem BusInterface zu setzen:

MLBevo auf FlexRay A-Kanal = 0 (aktiv)
MQB auf A-CAN = 0 (aktiv)
MQB2020 ";
CM_ SG_ 2549088374 KN_Motor_BusKnockOut "Ausgabe des BusKnockout-Status in der Knotenbotschaft";
CM_ SG_ 2549088374 KN_Motor_BusKnockOutTimer "Ausgabe des BusKnockOut-Timer in der Knotenbotschaft";
CM_ SG_ 2549088374 KN_Motor_ECUKnockOut "Ausgabe des ECUKnockout-Status in der Knotenbotschaft";
CM_ SG_ 2549088374 KN_Motor_ECUKnockOutTimer "Ausgabe des ECUKnockOut-Timer in der Knotenbotschaft";
CM_ SG_ 2549088374 MO_01_Abschaltstufe "Funktionseinschränkung aufgrund aktiver Abschaltstufe";
CM_ SG_ 2549088374 MO_01_Transport_Mode "Funktionseinschränkung aufgrund aktivem Transport Mode und/oder Transport Schutz";
CM_ SG_ 2549088374 MO_KD_Fehler "Kundendienstfehlerspeicherbit";
CM_ SG_ 2549088374 Motor_KompSchutz "Funktionseinschränkung aufgrund Komponentenschutz aktiv";
CM_ SG_ 2549088374 Motor_Nachlauftyp "Abgebildet wird die von der Hardware vorgegebene Möglichkeit, die Kommunikation nach Klemme 15 = AUS aufrecht zu erhalten. Es wird ein Init-Wert gesendet.
0 = Kommunikation nur bei KL15=EIN (kein Nachlauf, nicht weckfähig)
1 = Kommunikation nach KL15=AU";
CM_ SG_ 2549088374 NM_MO_01_Wakeup "enthält die Weckursache; stehen mehrere Weckursachen parallel an, dann muss der kleinste Wert übertragen werden";

CM_ SG_ 779 KBI_ABS_Lampe "ABS-Sicherheits-Lampe wurde eingeschaltet.";
CM_ SG_ 779 KBI_Airbag_Lampe "Airbag Sicherheits-Lampe wurde eingeschaltet ";
CM_ SG_ 779 KBI_angez_Geschw "Im Tacho angezeigte Geschwindigkeit inklusive der Voreilung

";
CM_ SG_ 779 KBI_Anzeigefehler_NV "Über dieses Signal teilt das Kombiinstrument dem Nightvision-Steuergerät mit, dass ein Fehler vom Kombiinstrument diagnostiziert wurde, der zur Abschaltung der Nightvision-Funktion führen muss.";
CM_ SG_ 779 KBI_Anzeigefehler_SWA "Signal bezieht sich nur auf die SWA-Lampe, Vorhalt für Kombis mit SWA-Lampe. ";
CM_ SG_ 779 KBI_Anzeigestatus_ACC "Status der ACC-Anzeige im nicht permanenten Displaybereich";
CM_ SG_ 779 KBI_Anzeigestatus_GRA "Anzeigestatus der GRA High Wunschgeschwindigkeitsanzeige im Kombiinstrument.
Bei VW bedeutet 'nicht vorhanden' GRA-low fähig (LED immer verbaut).
0 = nicht vorhanden
1 = Wunschgeschwindigkeits-Anzeigemöglichkeit vorhanden
2 = reserviert
3 = Fehler (B";
CM_ SG_ 779 KBI_Anzeigestatus_LIM "Anzeigestatus der Speedlimiter Wunschgeschwindigkeitsanzeige im Kombiinstrument (permanenter Anzeigebereich)
0 = nicht vorhanden
1 = Wunschgeschwindigkeits-Anzeigemöglichkeit vorhanden
2 = reserviert
3 = Fehler (Botschaftsüberwachung, Timeout, Akustik";
CM_ SG_ 779 KBI_Anzeigestatus_RHP "Anzeigestatus des roten RHP-Symbols.";
CM_ SG_ 779 KBI_ARA_in_Anzeige "Anzeige von ARA im Kombi aktiv";
CM_ SG_ 779 KBI_Audioabsenkung_MIB "Anforderung der Audioabsenkung im MIB";
CM_ SG_ 779 KBI_Bestaetigung_ESP_Off "ESP Off Bestätigung vom Kombi ans ESC";
CM_ SG_ 779 KBI_BKL_Lampe "Sicherheits-Lampe Bremskontrolle wurde eingeschaltet;
";
CM_ SG_ 779 KBI_ESP_Lampe "ESP-Sicherheits-Lampe wurde eingeschaltet ";
CM_ SG_ 779 KBI_Fehler_Anzeige_ACC "Rückmeldung an ACC, dass mindestens eine der ACC-relevanten Anzeigen -rote Fahrerübernahme, Mitteldisplay, Gong - fehlerhaft sind.";
CM_ SG_ 779 KBI_Handbremse "Handbremsen-Information vom Kombi.
Das Signal bezieht sich ausschließlich auf den Zustand der konventionellen Handbremse.";
CM_ SG_ 779 KBI_im_Stellgliedtest "Kombi im Stellgliedtest, Signal muss eingelesen werden, um Fehlfunktion aufgrund der Bewegung der Stellglieder (Drehzahlmesser, Tacho) des Kombis zu verhindern";
CM_ SG_ 779 KBI_Konsistenz_ACC "Rückmeldung an ACC, dass die Botschaften zur Ansteuerung von Anzeigen nicht bzw. nicht konsistent empfangen wurden (Timeout-, BZ-, CHK- und DLC-Fehler)                                                                                                        ";
CM_ SG_ 779 KBI_Lenkung_Lampe "Sicherheits-Lampe der Lenkung (Lenkhilfe EPS, Audi-Dynamic-Steering ...) wurde eingeschaltet.

0x0 = Lenkungs-Lampe aus
0x1 = Lenkungs-Lampe ein";
CM_ SG_ 779 KBI_MFA_v_Einheit_01 "Einheit der Geschwindigkeit, die vom Fahrer im Car-Menü gewählt wurde. Veränderliche Grösse, im Gegensatz zur Einheit des Tachokranzes.";
CM_ SG_ 779 KBI_NV_in_Anzeige "Das Bit gibt dem NV die Information, ob NV-Bild im Kombi in der Anzeige ist. (Information ist notwendig um Kontrasverstellungen nur dann zuzulassen, wenn der Fahrer das Feedback über das  Kombidisplay bekommt.)";
CM_ SG_ 779 KBI_Oeldruck_Schalter "Das Signal bildet den Status des Öldrucks über den am Kombi angeschlossenen Öldruckschalter ab.";
CM_ SG_ 779 KBI_Oeldruckwarnung "Öldruckwarnung im Kombi aktiv";
CM_ SG_ 779 KBI_PLA_in_Anzeige "Das Signal wird als aktive Rückmeldung genutzt, ob die Info des PLA im Kombi angezeigt wird. Wenn nach Anforderung des Displays das Signal zweimal auf 0 ist, wird der Parkvorgang abgebrochen.
Ein Kombi, dass PLA Anzeige nicht unterstützt, schickt dauerha";
CM_ SG_ 779 KBI_SILA_gueltig "Rückmeldeinformation (Bit 1-6) ist gültig";
CM_ SG_ 779 KBI_Systemstatus "Signalisiert erkannte FuSi-relevante Fehler im Kombi
(keinen Ausfall der Akustik oder des Displays)";
CM_ SG_ 779 KBI_Tankwarnung "Fahrer wird gewarnt, dass er den Reservebereich erreicht hat. Fzg.spezifische Warnschwelle";
CM_ SG_ 779 KBI_Tankwarnung_ungueltig "Validiert den Inhalt des Signales KBI_Tankwarnung";
CM_ SG_ 779 KBI_Taster_Fahrwerk "Betätigung Taster 'Fahrwerk' im Kombi";
CM_ SG_ 779 KBI_Taster_Lift "Betätigung Taster 'Lift' im Kombi J1 zur Verarbeitung im Porsche EFP Steuergerät";
CM_ SG_ 779 KBI_V_Digital "Ausgabe der im Kombi angezeigten digitalen Geschwindigkeit.

Einheit ist im KBI_MFA_v_Einheit_01 definiert";
CM_ SG_ 779 KBI_Vorglueh_System_Lampe "Rückmeldung der Vorglühlampe bzw. Motor Systemlampe (MO_Systemlampe) an den Motor (bei Diesel und Otto!). Hardwaremässig gleiche LED im Kombi (EPC- oder Glühwendel), Unterscheidung nur über Ziffernblatt.";

CM_ SG_ 1719 KBI_aktive_Laengsfunktion_02 "Auswahl, der vom Fahrer gewünschten Laengsregelfunktion";
CM_ SG_ 1719 KBI_FoD_PopUP_Quittiert "Angezeigte FoD-Warnung im Kombi wurde vom Fahrer quittiert; 
Signal wird für die Dauer von 2 Sekunden gesendet";
CM_ SG_ 1719 KBI_FStatus_Tank "Signal wird gesetzt:

a) Während der Fehlerentprellzeit (20 s Entprellung)

b) Bei erkanntem Fehler wird der Tankinhalt während der laufenden KL15-Phase über den 
    Verbrauch zurückgerechnet. In dieser Zeit ist das Bit ebenfalls gesetzt. Nach einem";
CM_ SG_ 1719 KBI_GRA_im_ACC "Gibt den vom Fahrer ausgewählten Modus (ACC oder GRA_im_ACC) an.";
CM_ SG_ 1719 KBI_Inhalt_Tank "Restmenge 2 bzw. 2,5l nicht auflösbar

";
CM_ SG_ 1719 KBI_Kilometerstand "Fehler wird ausgegeben, falls Kilometerstand nicht restaurierbar
";
CM_ SG_ 1719 KBI_Oelwechsel_durchgefuehrt "Nach einen Ölwechsel (Service) ist die Ethanol Warmfahrwarnung zu unterdrücken.";
CM_ SG_ 1719 KBI_QBit_Aussen_Temp_gef "0x0 = gültiger Wert
0x1 = Ersatz-, Init- oder Fehlerwert";
CM_ SG_ 1719 KBI_RDK_Kalibrier_Anf "Bei gesetztem Bit soll die RDK die aktuellen Istdrücke zu Solldrücken übernehmen (nur bei Nichtverbau einer Headunit erforderlich).";
CM_ SG_ 1719 KBI_Reserve_Warnung_Sek "Signalisiert die Reservewarnung für die Energiespeicher CNG, LPG, HV-Batterie.
Fahrer wird gewarnt, dass er den Reservebereich erreicht hat. Fzg.spezifische Warnschwelle.";
CM_ SG_ 1719 KBI_Standzeit_02 "Zähler welcher die Standzeit des Motors wiedergibt.
Das Signal beschreibt den Anteil der Motor-Standzeit zwischen Zündung aus und nächstem Motorstart.";

CM_ SG_ 1720 KBI_BCmE_aktiv "Anzeige BCmE aktiv (BCmE-Screen oder Einsparhinweis in der Anzeige)";
CM_ SG_ 1720 KBI_GAP_Warn_Zeit_abgelaufen "Die Zeit, z.B. 1460 Tage, bis zur finalen Warnstufe der Gasanlagenprüfung wurde berechnet. Berechnung erfolgt auf Basis der aktuellen Uhrzeit mit einem Tageszähler. Keine Berechnung des Zählers bei Kl.30 AUS.";
CM_ SG_ 1720 KBI_Max_Tankinhalt "Mitteilung des maximalen Tankinhalts an das Reichweitenmodul";
CM_ SG_ 1720 KBI_Nachtanken_erkannt "Statusinformation Nachtankmodus";
CM_ SG_ 1720 KBI_Quittierung_cAQP "Quittierungsbestätigung vom Fahrer für Funktion cAQP";
CM_ SG_ 1720 KBI_Quittierung_Naesse "Quittierungsbestätigung vom Fahrer";
CM_ SG_ 1720 KBI_Reifenumfang "Mittlerer Radumfang aus der K-Zahl gerechnet in Millimeter.  Byte 2 Bit 5,4 reserviert, Byte 2 Bit 3..0 und Byte 1 Bit 7..0; Wertebereich 0..4096 mm
";
CM_ SG_ 1720 KBI_Reifenumfang_Sekundaer "Fahrzeuge mit unterschiedlichen Reifenumfängen Vorderachse / Hinterachse:

Primärachse: KBI_Reifenumfang
Sekundärachse: KBI_Reifenumfang_Sekundaer
";
CM_ SG_ 1720 KBI_Sparhinweis_quittiert "angezeigter Sparhinweis ist quittiert. Signal wird nach zwei Sendebotschaften wieder auf '0' gesetzt.";
CM_ SG_ 1720 KBI_Tankfuellstand_Prozent "Tankfüllstand in %";
CM_ SG_ 1720 KBI_Tankinhalt_hochaufl "angezeigter Tankinhalt hochauflösend zur Restreichweitenberechnung";
CM_ SG_ 1720 KBI_Variante "Zeigt an ob es sich um ein konventionelles Zeiger-Kombiinstrument handelt oder um eine Volldisplay-Kombiinstrument";
CM_ SG_ 1720 KBI_Variante_USA "In diesem Signal wird die HW-Variante des Kombis ausgegeben, ACC plausibilisiert auf dieses Signal hin seine US-Codierung";

CM_ SG_ 2589283631 KBI_BC_Reset_E1 "Signalisierung BC Reset. Bei jedem BC Reset wird um 1 hochgezaehlt, bei 0x6 erfolgt Ueberlauf auf 0x1. Bei SG-Reset und Datenverlust vom BC wird der Wert SG_Reset angenommen. Während der Init-Phase wird Init gesendet, nach der Init-Phase der letzte gültig";
CM_ SG_ 2589283631 KBI_BC_Reset_E2 "Signalisierung BC Reset. Bei jedem BC Reset wird um 1 hochgezaehlt, 
bei 0x6 erfolgt Ueberlauf auf 0x1. Bei SG-Reset und Datenverlust vom 
BC wird der Wert SG_Reset angenommen. Während der Init-Phase wird Init gesendet, nach der Init-Phase der letzte gü";
CM_ SG_ 2589283631 KBI_BC_Reset_E3 "Signalisierung BC Reset. Bei jedem BC Reset wird um 1 hochgezaehlt, 
bei 0x6 erfolgt Ueberlauf auf 0x1. Bei SG-Reset und Datenverlust vom 
BC wird der Wert SG_Reset angenommen. Während der Init-Phase wird Init gesendet, nach der Init-Phase der letzte gü";
CM_ SG_ 2589283631 KBI_Kilometerstand_HiRes "Aufgrund gesetzlicher Anforderung muß Motor-SG den Kilometerstand an GST Mode$01 ausgeben.
Vgl. SAEJ1979 Festlegung zum PID$A6: Auflösung 0,1km / Bit
4 Byte länge (Doubleword)";
CM_ SG_ 2589283631 KBI_Tankinhalt_roh "Überträgt den ungefilterten und kalibrierten Tankinhalt (incl. Überhub im Vollbereich). Die Bereitstellung des Signale erfolgt nicht nach OBD Richtlinien. Die OBD konforme Verarbeitung erfolgt im Empfänger";

CM_ SG_ 285 EPS_02_BZ "Botschaft asynchron geroutet. Zählerwert kann springen.";
CM_ SG_ 285 EPS_02_CRC "Für MLB:
'Berechnung siehe Lastenheft 'Kommunikationsabsicherung für FlexRay und CAN''

Ab MQB und MLBevo:
'Berechnung siehe Lastenheft 'End-to-End Kommunikationsabsicherung''

Endwerte siehe Begleitdokument 'S-PDU Kennungsfolgen'
";
CM_ SG_ 285 EPS_Drehzahlreserve "Signal beschreibt wieviel Drehzahlreserve in EPS besteht (abhängig von Bordnetzspannung)";
CM_ SG_ 285 EPS_Lastinfo "entspricht Stromaufnahme des Lenkhilfe-SG, Auflösung = 1A";
CM_ SG_ 285 EPS_Leistungsanforderung "Signal informiert BEM, daß EPS einen erhöhten Leistungs-/Spannungsbedarf hat";
CM_ SG_ 285 EPS_Motorstartverzoegerung "Das Signal gibt eine Empfehlung, ob der Motorstart verzögert werden sollte. Es beschreibt aber kein Motorstartverbot. Der Motor darf trotz gesetztem Bit einen Motorstart vollziehen.";
CM_ SG_ 285 EPS_Notlauf "Bit-Feld zeigt an, dass sich die Lenkhilfe in einem Notlaufprogramm 
befindet und durch welche Ursache dieses aktiviert wurde; 
das Betriebsverhalten der Lenkhilfe wird an das bestehende Defizit angepasst.

Erläuterung Notlauf-Ursachen:

- Unterspan";
CM_ SG_ 285 EPS_StartStopp_Info "Das Signal gibt eine Motorstoppempfehlung für StartStop. 
Bei einem zu großem Handlenkmoment von X Nm wird eine Empfehlung ausgesprochen keinen Motorstopp durchzuführen.";
CM_ SG_ 285 EPS_Unterstuetzungsleistung "Die Unterstützungsleistung gibt prozentual an, in welchem Verhältnis die tatsächlich abgegebene Leistung zur Nominalleistung steht, d.h.:

0% = keine Servounterstützung

100% = maximale Servounterstützung (Nominalleistung);

0% < Unterstützungsleist";
CM_ SG_ 285 EPS_Versorgungsspannung "Gibt die am Steuergerät anliegende Spannung aus.
";
CM_ SG_ 285 EPS_VZ_Drehzahlreserve "Vorzeichen zur Drehzahlsreserve";
CM_ SG_ 285 EPS_Warmstartunterstuetzung "Erweiterte Spannungsanforderung für den Start-Stopp-Wiederstart";

CM_ SG_ 982 BCM2_Bremsl_durch_ECD "Bremslicht (ECD-Bremsung)
";
CM_ SG_ 982 BCM2_Bremsl_durch_ECD_invers "Inversbit Bremslicht (ECD-Bremsung) (Kommunikationsabsicherung)";
CM_ SG_ 982 LH_3_Bremsl_def "Fehlerstatus 3. Bremsleuchte
";
CM_ SG_ 982 LH_Aussenlicht_def "Aussenlicht kann nicht mehr korrekt angesteuert werden (EEPROM Codierung kann nicht mehr ausgelesen werden)
";
CM_ SG_ 982 LH_Blinker_HL_akt "Blinker hinten links
";
CM_ SG_ 982 LH_Blinker_HR_akt "Blinker hinten rechts
";
CM_ SG_ 982 LH_Blinker_li_def "Fehlerstatus Blinker hinten links
";
CM_ SG_ 982 LH_Blinker_re_def "Fehlerstatus Blinker hinten rechts
";
CM_ SG_ 982 LH_Brems_Blk_li_def "Konfiguration BRL + BLK links 
";
CM_ SG_ 982 LH_Brems_Blk_re_def "Konfiguration BRL + BLK rechts
";
CM_ SG_ 982 LH_Bremsl_li_def "Fehlerstatus Bremslicht hinten links (Detektion Einzelausfall)
";
CM_ SG_ 982 LH_Bremsl_li_ges_def "Fehlerstatus Bremslicht hinten links (Detektion Totalausfall)
";
CM_ SG_ 982 LH_Bremsl_re_def "Fehlerstatus Bremslicht hinten rechts  (Detektion Einzelausfall)
";
CM_ SG_ 982 LH_Bremsl_re_ges_def "Fehlerstatus Bremslicht hinten rechts (Detektion Totalausfall)";
CM_ SG_ 982 LH_Bremslicht_H_aktiv "Bremslicht hinten
";
CM_ SG_ 982 LH_Diag_LED_li_def "Heckleuchte links defekt";
CM_ SG_ 982 LH_Diag_LED_re_def "Heckleuchte rechts defekt";
CM_ SG_ 982 LH_Diag_Status_li_def "Außenlicht Diagnose 
Systemstörung links";
CM_ SG_ 982 LH_Diag_Status_re_def "Außenlicht Diagnose Systemstörung rechts ";
CM_ SG_ 982 LH_Kennzl_def "Fehlerstatus Kennzeichenbeleuchtung hinten
";
CM_ SG_ 982 LH_Nebel_li_def "Fehlererkennung Nebelschlusslicht hinten links";
CM_ SG_ 982 LH_Nebel_mi_def "Fehlererkennung Nebelschlusslicht hinten Mitte


";
CM_ SG_ 982 LH_Nebel_re_def "Fehlererkennung Nebelschlusslicht hinten rechts
";
CM_ SG_ 982 LH_Nebelschluss_aktiv "Nebelschlusslicht
";
CM_ SG_ 982 LH_Parklicht_HL_aktiv "Parklicht hinten links 
";
CM_ SG_ 982 LH_Parklicht_HR_aktiv "Parklicht hinten rechts 
";
CM_ SG_ 982 LH_Rueckf_li_def "Fehlererkennung Rückfahrlicht hinten links
";
CM_ SG_ 982 LH_Rueckf_mi_def "Fehlererkennung Rückfahrlicht Mitte
";
CM_ SG_ 982 LH_Rueckf_re_def "Fehlererkennung Rückfahrlicht hinten rechts
";
CM_ SG_ 982 LH_Rueckfahrlicht_aktiv "Rueckfahrlicht";
CM_ SG_ 982 LH_Schluss_Brems_li_def "Konfiguration SL+ BRL + PL links und SL+ BRL  links
";
CM_ SG_ 982 LH_Schluss_Brems_Nebel_li_def "Signal wird gesetzt, wenn eine Unterbrechung oder  ein Kurzschluss am Lampenausgang für Schluss_Brems_Nebelschlusslicht erkannt wird.";
CM_ SG_ 982 LH_Schluss_Brems_Nebel_re_def "Signal wird gesetzt, wenn eine Unterbrechung oder  ein Kurzschluss am Lampenausgang für Schluss_Brems_Nebelschlusslicht erkannt wird.";
CM_ SG_ 982 LH_Schluss_Brems_re_def "Konfiguration SL+ BRL + PL rechts und SL+ BRL  rechts
";
CM_ SG_ 982 LH_Schluss_Nebel_li_def "Konfiguration SL + NSL links oder SL + NSL + PL links
";
CM_ SG_ 982 LH_Schluss_Nebel_re_def "Konfiguration SL + NSL rechts oder SL + NSL + PL rechts
";
CM_ SG_ 982 LH_Schlusslicht_li_def "Fehlererkennung Schlusslicht hinten links
";
CM_ SG_ 982 LH_Schlusslicht_re_def "Fehlererkennung Schlusslicht hinten rechts";
CM_ SG_ 982 LH_SL_BRL_BLK_li_def "Konfiguration SL + BRL + BLK links oder SL + BRL + BLK + PL links
";
CM_ SG_ 982 LH_SL_BRL_BLK_re_def "Konfiguration SL + BRL + BLK rechts oder SL + BRL + BLK + PL rechts
";
CM_ SG_ 982 LH_Standlicht_H_aktiv "Standlicht hinten
";
CM_ SG_ 982 LH_Zusatzschlussl_def "mindestens ein Zusatzschlusslicht in der Heckbeleuchtung defekt.";
CM_ SG_ 982 Licht_hinten_01_BZ "überlaufender 4bit Botschaftszaehler; wird in jeder Sendebotschaft inkrementiert";

CM_ SG_ 2527679634 LSH_Fehlerstatus "Fehlerstatus Luftstandheizung";
CM_ SG_ 2527679634 LSH_Heizleistung "Heizleistung in %";
CM_ SG_ 2527679634 LSH_KL_DBetr_Anf "Sicherheitsabfrage der Luftstandheizung, ob Dauerstandheizbetrieb wirklich gestartet werden soll.
Bestätigungsbit für Anforderung KL_LSH_DBetr_Ein";
CM_ SG_ 2527679634 LSH_KVS "Kraftstoffverbrauch";
CM_ SG_ 2527679634 LSH_KVS_Ueberlauf "Kraftstoffverbrauch Ueberlauf";
CM_ SG_ 2527679634 LSH_Zuheizen "Rückmeldung von der Luftstandheizung, dass das Gerät im Zuheizbetrieb ist.";

CM_ SG_ 134 LWI_01_CRC "Für MLB:
'Berechnung siehe Lastenheft 'Kommunikationsabsicherung für FlexRay und CAN''

Ab MQB und MLBevo:
'Berechnung siehe Lastenheft 'End-to-End Kommunikationsabsicherung'

Endwerte siehe Begleitdokument 'S-PDU Kennungsfolgen'";
CM_ SG_ 134 LWI_Lenkradw_Geschw "Wertebereich = +/- 2500 Grad/s
Auflösung = 5 Grad/s

Hinweis: Zusätzlich gestellte Winkel bei Dynamiklenkung beachten !";
CM_ SG_ 134 LWI_Lenkradwinkel "Wertebereich = +/- 800 Grad
Auflösung = 0,1 Grad
ACHTUNG: spezifizierte Interne Auflösung des Sensors beträgt aber nur Schrittweite 0,5 Grad!

Hinweis:
MLB: Zusätzlich gestellte Winkel bei Dynamiklenkung beachten !
MQB: Nicht konstante Lenkübersetzu";
CM_ SG_ 134 LWI_QBit_Lenkradwinkel "Das QBit wird auch bei nicht abgeglichenem Lenkradwinkelsensor gesetzt";
CM_ SG_ 134 LWI_QBit_Sub_Daten "Es gilt die Signalspezifikation laut LAH";
CM_ SG_ 134 LWI_Sub_Daten "Verschlüsseltes Datenpaket vom Sub-Rechner des LWS, Verwendung nur durch SCU und ESP_ADS
Verwendung gemäß 'Sicherheitsanforderungen an Empfängersteuergeräte'

Im MLB gilt die Signalspezifikation: LAH 8K0953B
Im MLBevo gilt die Signalspezifikation LAH.";
CM_ SG_ 134 LWI_VZ_Lenkradw_Geschw "Vorzeichen Lenkradwinkelgeschwindigkeit gemäss DIN70000; 
Nullstellung = +0";
CM_ SG_ 134 LWI_VZ_Lenkradwinkel "Vorzeichen Lenkradwinkel gemäss DIN70000; 
Nullstellung = +0";

CM_ SG_ 1153 DSSS_Warning "DSSS - Driving Safety Support System Meldungen";
CM_ SG_ 1153 MIB_ASW_Diagnose "Diagnose Rückmeldung vom MIB zu Heckradar Entry. ASW Warnton Verfügbarkeit.";
CM_ SG_ 1153 MIB_Tongenerator_PH_verfuegbar "Verfügbarkeit des Tongenerators im MIB für die Nutzung durch die Parkhilfe";
CM_ SG_ 1153 MMI_Counter_Bedienevent "Signal wird inkrementiert, wenn Bedienevent stattgefunden hat.";
CM_ SG_ 1153 MMI_Gurt_Mic_ref "Referenzsignal für das Gurtmikrofon Steuergerät zur Signalisierung ob der Downlink aktiv oder inaktiv ist";
CM_ SG_ 1153 MMI_SDS_aktiv "Signal wird gesetzt, solange die Sprachbedienung aktiv ist.";
CM_ SG_ 1153 MU_SecondDisplay "Dient zur Überwachung der zweiten LVDS Leitung.";
CM_ SG_ 1153 MU_Update_Time "Ermöglicht auslesen der Historiendaten, wann ein Update lief";
CM_ SG_ 1153 Nav_FoD_Status "FoD Status der Navigation";
CM_ SG_ 1153 ZR_AppConnect_Zustand "Ist Zustand des AppConnect Kontextes im MIB";
CM_ SG_ 1153 ZR_Kindersicherung_RSE "Sperren der Rearseat Unit (Komplette Weckfähigkeit)";
CM_ SG_ 1153 ZR_Lichter_Tag "Berechnete Kennzeichnung des Sonnenstandes über bzw. oder unter Horizont.";
CM_ SG_ 1153 ZR_LoGeWa_Event_Kombiwarnung "Event für Kombiwarnung";
CM_ SG_ 1153 ZR_Parken_Sondermodus "Rückkanal zum pilotierten Parken zur Signalisierung Status Sondermodus";
CM_ SG_ 1153 ZR_RSE_aktivieren "Weckfähigkeit der RSE";
CM_ SG_ 1153 ZR_Sta_Inszenierung "MIB sendet Status über Inszenierungssound (welcome sound) an BCM1
Zweck: Synchronisierung mit weiteren Teilnehmern der Startupinszenierung";
BA_DEF_REL_ BU_SG_REL_  "GenSigTimeoutTime" INT 0 65535;
BA_DEF_ BO_  "DiagRequest" ENUM "No", "Yes";
BA_DEF_ BO_  "DiagResponse" ENUM "No", "Yes";
BA_DEF_ BO_  "DiagState" ENUM "No", "Yes";
BA_DEF_ BO_  "GenMsgChkConstant" HEX 0 4095;
BA_DEF_ BO_  "GenMsgCycleTime" INT 0 65535;
BA_DEF_ BO_  "GenMsgCycleTimeFast" INT 0 65535;
BA_DEF_ BO_  "GenMsgDelayTime" INT 0 100000;
BA_DEF_ BO_  "GenMsgILSupport" ENUM "No", "Yes";
BA_DEF_ BO_  "GenMsgNrOfRepetition" INT 0 100;
BA_DEF_ BO_  "GenMsgPDUConstants" STRING;
BA_DEF_ BO_  "GenMsgSendType" ENUM "Cyclic", "not_used", "not_used", "not_used", "not_used", "not_used", "not_used", "IfActive", "NoMsgSendType";
BA_DEF_ BO_  "GenMsgStartDelayTime" INT 0 100000;
BA_DEF_ BO_  "NmMessage" ENUM "No", "Yes";
BA_DEF_ BO_  "NmhMessage" ENUM "No", "Yes";
BA_DEF_ BO_  "MsgType" ENUM "Application", "NM ", "NMH", "TP2.0", "ISO-TP ", "BAP", "EID", "KS", "XCP_PRE_CONFIGURED", "XCP_RUNTIME_CONFIGURED";
BA_DEF_ BO_  "VAGTP20_API" HEX 0 255;
BA_DEF_ BO_  "VAGTP20_DynConnection" ENUM "No", "Yes";
BA_DEF_ BO_  "VAGTP20_DynSetup" ENUM "No", "Yes";
BA_DEF_ BO_  "VAGTP20_StatConnection" ENUM "No", "Yes";
BA_DEF_ BO_  "CANFD_BRS" ENUM "0", "1";
BA_DEF_ BO_  "VFrameFormat" ENUM "StandardCAN", "ExtendedCAN", "reserved", "reserved", "reserved", "reserved", "reserved", "reserved", "reserved", "reserved", "reserved", "reserved", "reserved", "reserved", "StandardCAN_FD", "ExtendedCAN_FD";
BA_DEF_ SG_  "GenSigActiveRepetitions" INT -2147483648 2147483647;
BA_DEF_ SG_  "GenSigInactiveValue" INT -2147483648 2147483647;
BA_DEF_ SG_  "GenSigSendType" ENUM "Cyclic", "OnWrite", "OnWriteWithRepetition", "OnChange", "OnChangeWithRepetition", "IfActive", "IfActiveWithRepetition", "NoSigSendType", "OnChangeAndIfActive", "OnChangeAndIfActiveWithRepetition";
BA_DEF_ SG_  "GenSigStartValue" INT -2147483648 2147483647;
BA_DEF_ SG_  "NWM-WakeupAllowed" ENUM "No", "Yes";
BA_DEF_ SG_  "GenSigFuncType" ENUM "NoFunction", "MsgCounter", "CRC-8", "XOR", "XOR-2", "DatedBit", "SW-Kl15", "CHK", "Constant", "Protocol", "CRC-8-SAE_J1850", "CRC-32", "DataLength", "DataID", "MsgCounter16", "SOK-Signatur", "Cluster";
BA_DEF_ SG_  "GenSigSwitchedByIgnition" ENUM "No", "Yes";
BA_DEF_ SG_  "Fehlerwert" HEX 0 2147483647;
BA_DEF_ SG_  "GenSigMissingSourceValue" HEX 0 2147483647;
BA_DEF_DEF_REL_  "GenSigTimeoutTime" 0;
BA_DEF_DEF_  "DiagRequest" "No";
BA_DEF_DEF_  "DiagResponse" "No";
BA_DEF_DEF_  "DiagState" "No";
BA_DEF_DEF_  "GenMsgChkConstant" 0;
BA_DEF_DEF_  "GenMsgCycleTime" 0;
BA_DEF_DEF_  "GenMsgCycleTimeFast" 0;
BA_DEF_DEF_  "GenMsgDelayTime" 0;
BA_DEF_DEF_  "GenMsgILSupport" "No";
BA_DEF_DEF_  "GenMsgNrOfRepetition" 0;
BA_DEF_DEF_  "GenMsgPDUConstants" "";
BA_DEF_DEF_  "GenMsgSendType" "NoMsgSendType";
BA_DEF_DEF_  "GenMsgStartDelayTime" 0;
BA_DEF_DEF_  "NmMessage" "No";
BA_DEF_DEF_  "NmhMessage" "No";
BA_DEF_DEF_  "MsgType" "Application";
BA_DEF_DEF_  "VAGTP20_API" 0;
BA_DEF_DEF_  "VAGTP20_DynConnection" "No";
BA_DEF_DEF_  "VAGTP20_DynSetup" "No";
BA_DEF_DEF_  "VAGTP20_StatConnection" "No";
BA_DEF_DEF_  "CANFD_BRS" "1";
BA_DEF_DEF_  "VFrameFormat" "StandardCAN";
BA_DEF_DEF_  "GenSigActiveRepetitions" 0;
BA_DEF_DEF_  "GenSigInactiveValue" 0;
BA_DEF_DEF_  "GenSigSendType" "NoSigSendType";
BA_DEF_DEF_  "GenSigStartValue" 0;
BA_DEF_DEF_  "NWM-WakeupAllowed" "No";
BA_DEF_DEF_  "GenSigFuncType" "NoFunction";
BA_DEF_DEF_  "GenSigSwitchedByIgnition" "Yes";
BA_DEF_DEF_  "Fehlerwert" 0;
BA_DEF_DEF_  "GenSigMissingSourceValue" 0;
BA_ "DiagResponse" BO_ 2550530105 1;
BA_ "MsgType" BO_ 2550530105 4;
BA_ "VFrameFormat" BO_ 2550530105 15;
BA_ "DiagResponse" BO_ 2621833273 1;
BA_ "MsgType" BO_ 2621833273 4;
BA_ "VFrameFormat" BO_ 2621833273 15;
BA_ "DiagRequest" BO_ 2549874806 1;
BA_ "MsgType" BO_ 2549874806 4;
BA_ "VFrameFormat" BO_ 2549874806 15;
BA_ "DiagRequest" BO_ 2621440118 1;
BA_ "MsgType" BO_ 2621440118 4;
BA_ "VFrameFormat" BO_ 2621440118 15;
BA_ "DiagResponse" BO_ 2550005878 1;
BA_ "MsgType" BO_ 2550005878 4;
BA_ "VFrameFormat" BO_ 2550005878 15;
BA_ "DiagResponse" BO_ 2621571190 1;
BA_ "MsgType" BO_ 2621571190 4;
BA_ "VFrameFormat" BO_ 2621571190 15;
BA_ "DiagRequest" BO_ 2549874821 1;
BA_ "MsgType" BO_ 2549874821 4;
BA_ "VFrameFormat" BO_ 2549874821 15;
BA_ "DiagRequest" BO_ 2621440133 1;
BA_ "MsgType" BO_ 2621440133 4;
BA_ "VFrameFormat" BO_ 2621440133 15;
BA_ "DiagResponse" BO_ 2550005893 1;
BA_ "MsgType" BO_ 2550005893 4;
BA_ "VFrameFormat" BO_ 2550005893 15;
BA_ "DiagResponse" BO_ 2621571205 1;
BA_ "MsgType" BO_ 2621571205 4;
BA_ "VFrameFormat" BO_ 2621571205 15;
BA_ "GenMsgCycleTime" BO_ 792 80;
BA_ "GenMsgILSupport" BO_ 792 1;
BA_ "GenMsgSendType" BO_ 792 0;
BA_ "VFrameFormat" BO_ 792 14;
BA_ "GenMsgCycleTime" BO_ 1426 200;
BA_ "GenMsgDelayTime" BO_ 1426 20;
BA_ "GenMsgILSupport" BO_ 1426 1;
BA_ "GenMsgSendType" BO_ 1426 0;
BA_ "VFrameFormat" BO_ 1426 14;
BA_ "GenMsgChkConstant" BO_ 960 195;
BA_ "GenMsgCycleTime" BO_ 960 100;
BA_ "GenMsgDelayTime" BO_ 960 10;
BA_ "GenMsgILSupport" BO_ 960 1;
BA_ "GenMsgPDUConstants" BO_ 960 "0xc3,0xc3,0xc3,0xc3,0xc3,0xc3,0xc3,0xc3,0xc3,0xc3,0xc3,0xc3,0xc3,0xc3,0xc3,0xc3";
BA_ "GenMsgSendType" BO_ 960 0;
BA_ "VFrameFormat" BO_ 960 14;
BA_ "GenMsgCycleTime" BO_ 2463978753 1000;
BA_ "GenMsgCycleTimeFast" BO_ 2463978753 100;
BA_ "GenMsgDelayTime" BO_ 2463978753 10;
BA_ "GenMsgILSupport" BO_ 2463978753 1;
BA_ "GenMsgNrOfRepetition" BO_ 2463978753 5;
BA_ "GenMsgPDUConstants" BO_ 2463978753 "0x80,0xf1,0xa5,0xaf,0x94,0x59,0xe8,0x8c,0x03,0xd4,0xf5,0x5e,0xec,0x73,0x81,0x50";
BA_ "GenMsgSendType" BO_ 2463978753 0;
BA_ "VFrameFormat" BO_ 2463978753 15;
BA_ "GenMsgCycleTime" BO_ 1420 1000;
BA_ "GenMsgCycleTimeFast" BO_ 1420 20;
BA_ "GenMsgDelayTime" BO_ 1420 10;
BA_ "GenMsgILSupport" BO_ 1420 1;
BA_ "GenMsgNrOfRepetition" BO_ 1420 5;
BA_ "GenMsgPDUConstants" BO_ 1420 "0x9b,0xb5,0x9d,0x06,0x01,0xe7,0x8f,0xc1,0xd0,0x10,0x47,0xe9,0xd3,0xca,0x05,0xf0";
BA_ "GenMsgSendType" BO_ 1420 0;
BA_ "VFrameFormat" BO_ 1420 14;
BA_ "GenMsgCycleTime" BO_ 949 100;
BA_ "GenMsgILSupport" BO_ 949 1;
BA_ "GenMsgSendType" BO_ 949 0;
BA_ "VFrameFormat" BO_ 949 14;
BA_ "GenMsgCycleTime" BO_ 1640 200;
BA_ "GenMsgCycleTimeFast" BO_ 1640 100;
BA_ "GenMsgDelayTime" BO_ 1640 50;
BA_ "GenMsgILSupport" BO_ 1640 1;
BA_ "GenMsgNrOfRepetition" BO_ 1640 5;
BA_ "GenMsgSendType" BO_ 1640 0;
BA_ "VFrameFormat" BO_ 1640 14;
BA_ "GenMsgCycleTime" BO_ 1511 200;
BA_ "GenMsgILSupport" BO_ 1511 1;
BA_ "GenMsgSendType" BO_ 1511 0;
BA_ "VFrameFormat" BO_ 1511 14;
BA_ "GenMsgCycleTime" BO_ 1514 500;
BA_ "GenMsgILSupport" BO_ 1514 1;
BA_ "GenMsgSendType" BO_ 1514 0;
BA_ "VFrameFormat" BO_ 1514 14;
BA_ "GenMsgCycleTime" BO_ 2589283627 500;
BA_ "GenMsgILSupport" BO_ 2589283627 1;
BA_ "GenMsgSendType" BO_ 2589283627 0;
BA_ "VFrameFormat" BO_ 2589283627 15;
BA_ "GenMsgCycleTime" BO_ 2589283574 500;
BA_ "GenMsgILSupport" BO_ 2589283574 1;
BA_ "GenMsgSendType" BO_ 2589283574 0;
BA_ "VFrameFormat" BO_ 2589283574 15;
BA_ "GenMsgCycleTime" BO_ 1505 200;
BA_ "GenMsgILSupport" BO_ 1505 1;
BA_ "GenMsgSendType" BO_ 1505 0;
BA_ "VFrameFormat" BO_ 1505 14;
BA_ "GenMsgCycleTime" BO_ 1513 200;
BA_ "GenMsgILSupport" BO_ 1513 1;
BA_ "GenMsgSendType" BO_ 1513 0;
BA_ "VFrameFormat" BO_ 1513 14;
BA_ "GenMsgCycleTime" BO_ 2549088272 500;
BA_ "GenMsgILSupport" BO_ 2549088272 1;
BA_ "GenMsgSendType" BO_ 2549088272 0;
BA_ "VFrameFormat" BO_ 2549088272 15;
BA_ "GenMsgCycleTime" BO_ 2549088375 500;
BA_ "GenMsgILSupport" BO_ 2549088375 1;
BA_ "GenMsgSendType" BO_ 2549088375 0;
BA_ "VFrameFormat" BO_ 2549088375 15;
BA_ "GenMsgCycleTime" BO_ 2549088374 500;
BA_ "GenMsgILSupport" BO_ 2549088374 1;
BA_ "GenMsgSendType" BO_ 2549088374 0;
BA_ "VFrameFormat" BO_ 2549088374 15;
BA_ "GenMsgCycleTime" BO_ 779 50;
BA_ "GenMsgILSupport" BO_ 779 1;
BA_ "GenMsgSendType" BO_ 779 0;
BA_ "VFrameFormat" BO_ 779 14;
BA_ "GenMsgCycleTime" BO_ 1719 1000;
BA_ "GenMsgDelayTime" BO_ 1719 100;
BA_ "GenMsgILSupport" BO_ 1719 1;
BA_ "GenMsgSendType" BO_ 1719 0;
BA_ "VFrameFormat" BO_ 1719 14;
BA_ "GenMsgCycleTime" BO_ 1720 1000;
BA_ "GenMsgILSupport" BO_ 1720 1;
BA_ "GenMsgSendType" BO_ 1720 0;
BA_ "VFrameFormat" BO_ 1720 14;
BA_ "GenMsgCycleTime" BO_ 2589283631 500;
BA_ "GenMsgILSupport" BO_ 2589283631 1;
BA_ "GenMsgSendType" BO_ 2589283631 0;
BA_ "VFrameFormat" BO_ 2589283631 15;
BA_ "GenMsgChkConstant" BO_ 285 28;
BA_ "GenMsgCycleTime" BO_ 285 200;
BA_ "GenMsgDelayTime" BO_ 285 20;
BA_ "GenMsgILSupport" BO_ 285 1;
BA_ "GenMsgPDUConstants" BO_ 285 "0x1c,0x1c,0x1c,0x1c,0x1c,0x1c,0x1c,0x1c,0x1c,0x1c,0x1c,0x1c,0x1c,0x1c,0x1c,0x1c";
BA_ "GenMsgSendType" BO_ 285 0;
BA_ "VFrameFormat" BO_ 285 14;
BA_ "GenMsgCycleTime" BO_ 982 100;
BA_ "GenMsgDelayTime" BO_ 982 20;
BA_ "GenMsgILSupport" BO_ 982 1;
BA_ "GenMsgSendType" BO_ 982 0;
BA_ "VFrameFormat" BO_ 982 14;
BA_ "GenMsgCycleTime" BO_ 2527679634 200;
BA_ "GenMsgILSupport" BO_ 2527679634 1;
BA_ "GenMsgSendType" BO_ 2527679634 0;
BA_ "VFrameFormat" BO_ 2527679634 15;
BA_ "GenMsgChkConstant" BO_ 134 134;
BA_ "GenMsgCycleTime" BO_ 134 10;
BA_ "GenMsgILSupport" BO_ 134 1;
BA_ "GenMsgPDUConstants" BO_ 134 "0x86,0x86,0x86,0x86,0x86,0x86,0x86,0x86,0x86,0x86,0x86,0x86,0x86,0x86,0x86,0x86";
BA_ "GenMsgSendType" BO_ 134 0;
BA_ "VFrameFormat" BO_ 134 14;
BA_ "GenMsgCycleTime" BO_ 1153 500;
BA_ "GenMsgCycleTimeFast" BO_ 1153 50;
BA_ "GenMsgDelayTime" BO_ 1153 50;
BA_ "GenMsgILSupport" BO_ 1153 1;
BA_ "GenMsgNrOfRepetition" BO_ 1153 5;
BA_ "GenMsgSendType" BO_ 1153 0;
BA_ "VFrameFormat" BO_ 1153 14;
BA_ "GenSigSendType" SG_ 2550530105 ISOx_LCU_SMH_Resp_Data 3;
BA_ "GenSigFuncType" SG_ 2550530105 ISOx_LCU_SMH_Resp_Data 9;
BA_ "GenSigSwitchedByIgnition" SG_ 2550530105 ISOx_LCU_SMH_Resp_Data 0;
BA_ "GenSigSendType" SG_ 2621833273 ISOx_LCU_SMH_Resp_FD_Data 3;
BA_ "GenSigFuncType" SG_ 2621833273 ISOx_LCU_SMH_Resp_FD_Data 9;
BA_ "GenSigSwitchedByIgnition" SG_ 2621833273 ISOx_LCU_SMH_Resp_FD_Data 0;
BA_ "GenSigSendType" SG_ 2549874806 ISOx_MO_01_Req_Data 3;
BA_ "GenSigFuncType" SG_ 2549874806 ISOx_MO_01_Req_Data 9;
BA_ "GenSigSwitchedByIgnition" SG_ 2549874806 ISOx_MO_01_Req_Data 0;
BA_ "GenSigSendType" SG_ 2621440118 ISOx_MO_01_Req_FD_Data 3;
BA_ "GenSigFuncType" SG_ 2621440118 ISOx_MO_01_Req_FD_Data 9;
BA_ "GenSigSwitchedByIgnition" SG_ 2621440118 ISOx_MO_01_Req_FD_Data 0;
BA_ "GenSigSendType" SG_ 2550005878 ISOx_MO_01_Resp_Data 3;
BA_ "GenSigFuncType" SG_ 2550005878 ISOx_MO_01_Resp_Data 9;
BA_ "GenSigSwitchedByIgnition" SG_ 2550005878 ISOx_MO_01_Resp_Data 0;
BA_ "GenSigSendType" SG_ 2621571190 ISOx_MO_01_Resp_FD_Data 3;
BA_ "GenSigFuncType" SG_ 2621571190 ISOx_MO_01_Resp_FD_Data 9;
BA_ "GenSigSwitchedByIgnition" SG_ 2621571190 ISOx_MO_01_Resp_FD_Data 0;
BA_ "GenSigSendType" SG_ 2549874821 ISOx_RSG_Req_Data 3;
BA_ "GenSigFuncType" SG_ 2549874821 ISOx_RSG_Req_Data 9;
BA_ "GenSigSwitchedByIgnition" SG_ 2549874821 ISOx_RSG_Req_Data 0;
BA_ "GenSigSendType" SG_ 2621440133 ISOx_RSG_Req_FD_Data 3;
BA_ "GenSigFuncType" SG_ 2621440133 ISOx_RSG_Req_FD_Data 9;
BA_ "GenSigSwitchedByIgnition" SG_ 2621440133 ISOx_RSG_Req_FD_Data 0;
BA_ "GenSigSendType" SG_ 2550005893 ISOx_RSG_Resp_Data 3;
BA_ "GenSigFuncType" SG_ 2550005893 ISOx_RSG_Resp_Data 9;
BA_ "GenSigSwitchedByIgnition" SG_ 2550005893 ISOx_RSG_Resp_Data 0;
BA_ "GenSigSendType" SG_ 2621571205 ISOx_RSG_Resp_FD_Data 3;
BA_ "GenSigFuncType" SG_ 2621571205 ISOx_RSG_Resp_FD_Data 9;
BA_ "GenSigSwitchedByIgnition" SG_ 2621571205 ISOx_RSG_Resp_FD_Data 0;
BA_ "GenSigSendType" SG_ 792 Kamera_FDD_Anz_Strassenleuchten 0;
BA_ "GenSigStartValue" SG_ 792 Kamera_FDD_Anz_Strassenleuchten 15;
BA_ "GenSigSendType" SG_ 792 Kamera_FDD_Eigenblend 0;
BA_ "GenSigSendType" SG_ 792 Kamera_FDD_Eigenblend_Guete 0;
BA_ "GenSigStartValue" SG_ 792 Kamera_FDD_Eigenblend_Guete 14;
BA_ "Fehlerwert" SG_ 792 Kamera_FDD_Eigenblend_Guete 15;
BA_ "GenSigSendType" SG_ 792 Kamera_FDD_Funktionsstatus 0;
BA_ "GenSigStartValue" SG_ 792 Kamera_FDD_Funktionsstatus 6;
BA_ "GenSigSendType" SG_ 792 Kamera_FDD_Strassenbeleuchung 0;
BA_ "GenSigSendType" SG_ 792 Kamera_FDD_Verkehrsrichtung 0;
BA_ "GenSigStartValue" SG_ 792 Kamera_FDD_Verkehrsrichtung 2;
BA_ "GenSigSendType" SG_ 792 Kamera_FSH_aktiv 0;
BA_ "GenSigSendType" SG_ 792 Kamera_Helligkeit 0;
BA_ "GenSigStartValue" SG_ 792 Kamera_Helligkeit 1022;
BA_ "Fehlerwert" SG_ 792 Kamera_Helligkeit 1023;
BA_ "GenSigSendType" SG_ 792 Kamera_Systemzustand 0;
BA_ "GenSigStartValue" SG_ 792 Kamera_Systemzustand 1;
BA_ "GenSigSendType" SG_ 792 VZE_Status_EDR 0;
BA_ "GenSigSendType" SG_ 1426 KY_Aktive_LFScans 3;
BA_ "GenSigSwitchedByIgnition" SG_ 1426 KY_Aktive_LFScans 0;
BA_ "GenSigSendType" SG_ 1426 KY_AnzKoord_Info 3;
BA_ "GenSigSwitchedByIgnition" SG_ 1426 KY_AnzKoord_Info 0;
BA_ "GenSigSendType" SG_ 1426 KY_EasyClose_Abbruch 3;
BA_ "GenSigSwitchedByIgnition" SG_ 1426 KY_EasyClose_Abbruch 0;
BA_ "GenSigSendType" SG_ 1426 KY_EasyClose_Status 3;
BA_ "GenSigSwitchedByIgnition" SG_ 1426 KY_EasyClose_Status 0;
BA_ "GenSigSendType" SG_ 1426 KY_Fzg_Verlassen_erkannt 3;
BA_ "GenSigSwitchedByIgnition" SG_ 1426 KY_Fzg_Verlassen_erkannt 0;
BA_ "GenSigSendType" SG_ 1426 KY_Fzg_Zugang_erkannt 3;
BA_ "GenSigSwitchedByIgnition" SG_ 1426 KY_Fzg_Zugang_erkannt 0;
BA_ "GenSigSendType" SG_ 1426 KY_Gestik_HD 3;
BA_ "GenSigSwitchedByIgnition" SG_ 1426 KY_Gestik_HD 0;
BA_ "GenSigSendType" SG_ 1426 KY_Gong_600 3;
BA_ "GenSigSwitchedByIgnition" SG_ 1426 KY_Gong_600 0;
BA_ "GenSigSendType" SG_ 1426 KY_HD_Auffahrt 3;
BA_ "GenSigSwitchedByIgnition" SG_ 1426 KY_HD_Auffahrt 0;
BA_ "GenSigSendType" SG_ 1426 KY_HD_Zufahrt 3;
BA_ "GenSigSwitchedByIgnition" SG_ 1426 KY_HD_Zufahrt 0;
BA_ "GenSigSendType" SG_ 1426 KY_ID_Geber1_im_Fzg 3;
BA_ "GenSigSwitchedByIgnition" SG_ 1426 KY_ID_Geber1_im_Fzg 0;
BA_ "GenSigSendType" SG_ 1426 KY_ID_Geber2_im_Fzg 3;
BA_ "GenSigSwitchedByIgnition" SG_ 1426 KY_ID_Geber2_im_Fzg 0;
BA_ "GenSigSendType" SG_ 1426 KY_ID_Geber3_im_Fzg 3;
BA_ "GenSigSwitchedByIgnition" SG_ 1426 KY_ID_Geber3_im_Fzg 0;
BA_ "GenSigSendType" SG_ 1426 KY_ID_Geber4_im_Fzg 3;
BA_ "GenSigSwitchedByIgnition" SG_ 1426 KY_ID_Geber4_im_Fzg 0;
BA_ "GenSigSendType" SG_ 1426 KY_ID_Geber_Suche 3;
BA_ "GenSigSwitchedByIgnition" SG_ 1426 KY_ID_Geber_Suche 0;
BA_ "GenSigSendType" SG_ 1426 KY_LF_Aktiv 3;
BA_ "GenSigSwitchedByIgnition" SG_ 1426 KY_LF_Aktiv 0;
BA_ "GenSigSendType" SG_ 1426 KY_Meldungen 3;
BA_ "GenSigSwitchedByIgnition" SG_ 1426 KY_Meldungen 0;
BA_ "GenSigSendType" SG_ 1426 KY_Passiv_Autolock 3;
BA_ "GenSigSwitchedByIgnition" SG_ 1426 KY_Passiv_Autolock 0;
BA_ "GenSigSendType" SG_ 1426 KY_Passiv_Autolock_Akt 3;
BA_ "GenSigSwitchedByIgnition" SG_ 1426 KY_Passiv_Autolock_Akt 0;
BA_ "GenSigSendType" SG_ 1426 KY_Passiv_Autolock_Menue 3;
BA_ "GenSigSwitchedByIgnition" SG_ 1426 KY_Passiv_Autolock_Menue 0;
BA_ "GenSigSendType" SG_ 1426 KY_Passiv_Autounlock 3;
BA_ "GenSigSwitchedByIgnition" SG_ 1426 KY_Passiv_Autounlock 0;
BA_ "GenSigSendType" SG_ 1426 KY_Schluesselposition_1 3;
BA_ "GenSigSwitchedByIgnition" SG_ 1426 KY_Schluesselposition_1 0;
BA_ "GenSigSendType" SG_ 1426 KY_Schluesselposition_2 3;
BA_ "GenSigSwitchedByIgnition" SG_ 1426 KY_Schluesselposition_2 0;
BA_ "GenSigSendType" SG_ 1426 KY_Schluesselposition_3 3;
BA_ "GenSigSwitchedByIgnition" SG_ 1426 KY_Schluesselposition_3 0;
BA_ "GenSigSendType" SG_ 1426 KY_Schluesselposition_4 3;
BA_ "GenSigSwitchedByIgnition" SG_ 1426 KY_Schluesselposition_4 0;
BA_ "GenSigSendType" SG_ 1426 KY_Schluesselposition_5 3;
BA_ "GenSigSwitchedByIgnition" SG_ 1426 KY_Schluesselposition_5 0;
BA_ "GenSigSendType" SG_ 1426 KY_Schluesselposition_6 3;
BA_ "GenSigSwitchedByIgnition" SG_ 1426 KY_Schluesselposition_6 0;
BA_ "GenSigSendType" SG_ 1426 KY_Schluesselposition_7 3;
BA_ "GenSigSwitchedByIgnition" SG_ 1426 KY_Schluesselposition_7 0;
BA_ "GenSigSendType" SG_ 1426 KY_Schluesselposition_8 3;
BA_ "GenSigSwitchedByIgnition" SG_ 1426 KY_Schluesselposition_8 0;
BA_ "GenSigSendType" SG_ 1426 KY_Schluesselposition_9 3;
BA_ "GenSigSwitchedByIgnition" SG_ 1426 KY_Schluesselposition_9 0;
BA_ "GenSigSendType" SG_ 1426 KY_Startknopf_Bel 3;
BA_ "GenSigSwitchedByIgnition" SG_ 1426 KY_Startknopf_Bel 0;
BA_ "GenSigSendType" SG_ 1426 KY_StartStopp_Info 3;
BA_ "GenSigSwitchedByIgnition" SG_ 1426 KY_StartStopp_Info 0;
BA_ "GenSigSendType" SG_ 960 BCM_Ausparken_Betrieb 3;
BA_ "GenSigSwitchedByIgnition" SG_ 960 BCM_Ausparken_Betrieb 0;
BA_ "GenSigSendType" SG_ 960 BCM_Remotestart_Betrieb 3;
BA_ "GenSigSwitchedByIgnition" SG_ 960 BCM_Remotestart_Betrieb 0;
BA_ "GenSigSendType" SG_ 960 BCM_Remotestart_KL15_Anf 3;
BA_ "GenSigSwitchedByIgnition" SG_ 960 BCM_Remotestart_KL15_Anf 0;
BA_ "GenSigSendType" SG_ 960 BCM_Remotestart_MO_Start 3;
BA_ "GenSigSwitchedByIgnition" SG_ 960 BCM_Remotestart_MO_Start 0;
BA_ "GenSigSendType" SG_ 960 Klemmen_Status_01_BZ 0;
BA_ "GenSigFuncType" SG_ 960 Klemmen_Status_01_BZ 1;
BA_ "GenSigSwitchedByIgnition" SG_ 960 Klemmen_Status_01_BZ 0;
BA_ "GenSigSendType" SG_ 960 Klemmen_Status_01_CRC 0;
BA_ "GenSigFuncType" SG_ 960 Klemmen_Status_01_CRC 2;
BA_ "GenSigSwitchedByIgnition" SG_ 960 Klemmen_Status_01_CRC 0;
BA_ "GenSigSendType" SG_ 960 KST_Fahrerhinweis_1 3;
BA_ "GenSigSwitchedByIgnition" SG_ 960 KST_Fahrerhinweis_1 0;
BA_ "GenSigSendType" SG_ 960 KST_Fahrerhinweis_2 3;
BA_ "GenSigSwitchedByIgnition" SG_ 960 KST_Fahrerhinweis_2 0;
BA_ "GenSigSendType" SG_ 960 KST_Fahrerhinweis_4 3;
BA_ "GenSigSwitchedByIgnition" SG_ 960 KST_Fahrerhinweis_4 0;
BA_ "GenSigSendType" SG_ 960 KST_Fahrerhinweis_5 3;
BA_ "GenSigSwitchedByIgnition" SG_ 960 KST_Fahrerhinweis_5 0;
BA_ "GenSigSendType" SG_ 960 KST_Fahrerhinweis_6 3;
BA_ "GenSigSwitchedByIgnition" SG_ 960 KST_Fahrerhinweis_6 0;
BA_ "GenSigSendType" SG_ 960 KST_Warn_P1_ZST_def 3;
BA_ "GenSigSwitchedByIgnition" SG_ 960 KST_Warn_P1_ZST_def 0;
BA_ "GenSigSendType" SG_ 960 KST_Warn_P2_ZST_def 3;
BA_ "GenSigSwitchedByIgnition" SG_ 960 KST_Warn_P2_ZST_def 0;
BA_ "GenSigSendType" SG_ 960 RSt_Fahrerhinweise 3;
BA_ "GenSigSwitchedByIgnition" SG_ 960 RSt_Fahrerhinweise 0;
BA_ "GenSigSendType" SG_ 960 ZAS_Kl_15 3;
BA_ "NWM-WakeupAllowed" SG_ 960 ZAS_Kl_15 1;
BA_ "GenSigFuncType" SG_ 960 ZAS_Kl_15 6;
BA_ "GenSigSwitchedByIgnition" SG_ 960 ZAS_Kl_15 0;
BA_ "GenSigSendType" SG_ 960 ZAS_Kl_50_Startanforderung 3;
BA_ "GenSigSwitchedByIgnition" SG_ 960 ZAS_Kl_50_Startanforderung 0;
BA_ "GenSigSendType" SG_ 960 ZAS_Kl_Infotainment 3;
BA_ "GenSigSwitchedByIgnition" SG_ 960 ZAS_Kl_Infotainment 0;
BA_ "GenSigSendType" SG_ 960 ZAS_Kl_S 3;
BA_ "GenSigSwitchedByIgnition" SG_ 960 ZAS_Kl_S 0;
BA_ "GenSigSendType" SG_ 960 ZAS_Kl_X 3;
BA_ "GenSigSwitchedByIgnition" SG_ 960 ZAS_Kl_X 0;
BA_ "GenSigSendType" SG_ 2463978753 Klemmen_Status_02_BZ 0;
BA_ "GenSigFuncType" SG_ 2463978753 Klemmen_Status_02_BZ 1;
BA_ "GenSigSwitchedByIgnition" SG_ 2463978753 Klemmen_Status_02_BZ 0;
BA_ "GenSigSendType" SG_ 2463978753 Klemmen_Status_02_CRC 0;
BA_ "GenSigFuncType" SG_ 2463978753 Klemmen_Status_02_CRC 2;
BA_ "GenSigSwitchedByIgnition" SG_ 2463978753 Klemmen_Status_02_CRC 0;
BA_ "GenSigSendType" SG_ 2463978753 KST_ComfortReadyStatus 4;
BA_ "GenSigSwitchedByIgnition" SG_ 2463978753 KST_ComfortReadyStatus 0;
BA_ "GenSigSendType" SG_ 2463978753 KST_Freigabe_Zustand 4;
BA_ "GenSigSwitchedByIgnition" SG_ 2463978753 KST_Freigabe_Zustand 0;
BA_ "GenSigSendType" SG_ 2463978753 KST_Sonderzustand_Anforderung 4;
BA_ "GenSigSwitchedByIgnition" SG_ 2463978753 KST_Sonderzustand_Anforderung 0;
BA_ "Fehlerwert" SG_ 2463978753 KST_Sonderzustand_Anforderung 31;
BA_ "GenSigSendType" SG_ 2463978753 KST_Sonderzustand_Status 4;
BA_ "GenSigSwitchedByIgnition" SG_ 2463978753 KST_Sonderzustand_Status 0;
BA_ "Fehlerwert" SG_ 2463978753 KST_Sonderzustand_Status 3;
BA_ "GenSigSendType" SG_ 2463978753 KST_WFS_Fahrfreigabe_Anforderung 4;
BA_ "GenSigSwitchedByIgnition" SG_ 2463978753 KST_WFS_Fahrfreigabe_Anforderung 0;
BA_ "GenSigSendType" SG_ 1420 Klemmen_Steuerung_01_BZ 0;
BA_ "GenSigFuncType" SG_ 1420 Klemmen_Steuerung_01_BZ 1;
BA_ "GenSigSwitchedByIgnition" SG_ 1420 Klemmen_Steuerung_01_BZ 0;
BA_ "GenSigSendType" SG_ 1420 Klemmen_Steuerung_01_CRC 0;
BA_ "GenSigFuncType" SG_ 1420 Klemmen_Steuerung_01_CRC 2;
BA_ "GenSigSwitchedByIgnition" SG_ 1420 Klemmen_Steuerung_01_CRC 0;
BA_ "GenSigSendType" SG_ 1420 KST_Anf_Klemme_15 4;
BA_ "GenSigSwitchedByIgnition" SG_ 1420 KST_Anf_Klemme_15 0;
BA_ "GenSigSendType" SG_ 1420 KST_Anf_Klemme_50 4;
BA_ "GenSigSwitchedByIgnition" SG_ 1420 KST_Anf_Klemme_50 0;
BA_ "GenSigSendType" SG_ 1420 KST_Anf_Klemme_S 3;
BA_ "GenSigSwitchedByIgnition" SG_ 1420 KST_Anf_Klemme_S 0;
BA_ "GenSigSendType" SG_ 1420 KST_Anf_Klemmenfreigabe_ELV 3;
BA_ "GenSigSwitchedByIgnition" SG_ 1420 KST_Anf_Klemmenfreigabe_ELV 0;
BA_ "GenSigSendType" SG_ 1420 KST_Anf_Klemmenfreigabe_WFS 3;
BA_ "GenSigSwitchedByIgnition" SG_ 1420 KST_Anf_Klemmenfreigabe_WFS 0;
BA_ "GenSigSendType" SG_ 1420 KST_Anf_ZV_Verriegelung 3;
BA_ "GenSigSwitchedByIgnition" SG_ 1420 KST_Anf_ZV_Verriegelung 0;
BA_ "GenSigSendType" SG_ 1420 KST_Anzeige_Klemmenzustand 3;
BA_ "GenSigSwitchedByIgnition" SG_ 1420 KST_Anzeige_Klemmenzustand 0;
BA_ "GenSigSendType" SG_ 1420 KST_aut_Abschaltung_Zuendung 4;
BA_ "GenSigSwitchedByIgnition" SG_ 1420 KST_aut_Abschaltung_Zuendung 0;
BA_ "GenSigSendType" SG_ 1420 KST_Txt_Komfortabschaltung 3;
BA_ "GenSigSwitchedByIgnition" SG_ 1420 KST_Txt_Komfortabschaltung 0;
BA_ "GenSigSendType" SG_ 1420 KST_Txt_P_Gang 3;
BA_ "GenSigSwitchedByIgnition" SG_ 1420 KST_Txt_P_Gang 0;
BA_ "GenSigSendType" SG_ 1420 KST_Txt_Panikabschaltung 3;
BA_ "GenSigSwitchedByIgnition" SG_ 1420 KST_Txt_Panikabschaltung 0;
BA_ "GenSigSendType" SG_ 1420 KST_Txt_Werkstatt 3;
BA_ "GenSigSwitchedByIgnition" SG_ 1420 KST_Txt_Werkstatt 0;
BA_ "GenSigSendType" SG_ 1420 KST_Unterdr_Zuendungsmeldung 3;
BA_ "GenSigSwitchedByIgnition" SG_ 1420 KST_Unterdr_Zuendungsmeldung 0;
BA_ "GenSigSendType" SG_ 1420 KST_ZAT_betaetigt 3;
BA_ "GenSigSwitchedByIgnition" SG_ 1420 KST_ZAT_betaetigt 0;
BA_ "GenSigSendType" SG_ 1420 KST_Zuendungswarnung 4;
BA_ "GenSigSwitchedByIgnition" SG_ 1420 KST_Zuendungswarnung 0;
BA_ "GenSigSendType" SG_ 1420 Relais_VoKo_angesteuert 3;
BA_ "GenSigSwitchedByIgnition" SG_ 1420 Relais_VoKo_angesteuert 0;
BA_ "GenSigSendType" SG_ 1420 RSt_Anforderung_HMS 3;
BA_ "GenSigSwitchedByIgnition" SG_ 1420 RSt_Anforderung_HMS 0;
BA_ "GenSigSendType" SG_ 949 KL_AC_Schalter 0;
BA_ "GenSigSwitchedByIgnition" SG_ 949 KL_AC_Schalter 0;
BA_ "GenSigSendType" SG_ 949 KL_AirCleaner_aktiv 0;
BA_ "GenSigSwitchedByIgnition" SG_ 949 KL_AirCleaner_aktiv 0;
BA_ "GenSigSendType" SG_ 949 KL_Anf_KL 0;
BA_ "GenSigSwitchedByIgnition" SG_ 949 KL_Anf_KL 0;
BA_ "Fehlerwert" SG_ 949 KL_Anf_KL 255;
BA_ "GenSigSendType" SG_ 949 KL_Anf_KV 0;
BA_ "GenSigStartValue" SG_ 949 KL_Anf_KV 126;
BA_ "GenSigSwitchedByIgnition" SG_ 949 KL_Anf_KV 0;
BA_ "GenSigSendType" SG_ 949 KL_Ausstattung_Klima 0;
BA_ "GenSigSwitchedByIgnition" SG_ 949 KL_Ausstattung_Klima 0;
BA_ "GenSigSendType" SG_ 949 KL_Charisma_FahrPr 0;
BA_ "GenSigSwitchedByIgnition" SG_ 949 KL_Charisma_FahrPr 0;
BA_ "GenSigSendType" SG_ 949 KL_Charisma_Status 0;
BA_ "GenSigSwitchedByIgnition" SG_ 949 KL_Charisma_Status 0;
BA_ "GenSigSendType" SG_ 949 KL_Drehz_Anh 0;
BA_ "GenSigSwitchedByIgnition" SG_ 949 KL_Drehz_Anh 0;
BA_ "GenSigSendType" SG_ 949 KL_el_Zuheizer_Stufe 0;
BA_ "GenSigSwitchedByIgnition" SG_ 949 KL_el_Zuheizer_Stufe 0;
BA_ "GenSigSendType" SG_ 949 KL_Freilauf_Info 0;
BA_ "GenSigSwitchedByIgnition" SG_ 949 KL_Freilauf_Info 0;
BA_ "GenSigSendType" SG_ 949 KL_Komp_Moment_alt 0;
BA_ "GenSigFuncType" SG_ 949 KL_Komp_Moment_alt 5;
BA_ "GenSigSwitchedByIgnition" SG_ 949 KL_Komp_Moment_alt 0;
BA_ "GenSigSendType" SG_ 949 KL_Kompressorkupplung_linear 0;
BA_ "GenSigStartValue" SG_ 949 KL_Kompressorkupplung_linear 254;
BA_ "GenSigSwitchedByIgnition" SG_ 949 KL_Kompressorkupplung_linear 0;
BA_ "GenSigSendType" SG_ 949 KL_Last_Kompr 0;
BA_ "GenSigSwitchedByIgnition" SG_ 949 KL_Last_Kompr 0;
BA_ "Fehlerwert" SG_ 949 KL_Last_Kompr 255;
BA_ "GenSigSendType" SG_ 949 KL_nachtr_Stopp_Anf 0;
BA_ "GenSigSwitchedByIgnition" SG_ 949 KL_nachtr_Stopp_Anf 0;
BA_ "GenSigSendType" SG_ 949 KL_Spannungs_Anf 0;
BA_ "GenSigSwitchedByIgnition" SG_ 949 KL_Spannungs_Anf 0;
BA_ "GenSigSendType" SG_ 949 KL_StartStopp_Info 0;
BA_ "GenSigSwitchedByIgnition" SG_ 949 KL_StartStopp_Info 0;
BA_ "GenSigSendType" SG_ 949 KL_T_Charge 0;
BA_ "GenSigSwitchedByIgnition" SG_ 949 KL_T_Charge 0;
BA_ "GenSigSendType" SG_ 949 KL_Thermomanagement 0;
BA_ "GenSigSwitchedByIgnition" SG_ 949 KL_Thermomanagement 0;
BA_ "GenSigSendType" SG_ 949 KL_Variante_Standheizung 0;
BA_ "GenSigSwitchedByIgnition" SG_ 949 KL_Variante_Standheizung 0;
BA_ "GenSigSendType" SG_ 949 KL_Vorwarn_Komp_ein 0;
BA_ "GenSigSwitchedByIgnition" SG_ 949 KL_Vorwarn_Komp_ein 0;
BA_ "GenSigSendType" SG_ 949 KL_Vorwarn_Zuheizer_ein 0;
BA_ "GenSigSwitchedByIgnition" SG_ 949 KL_Vorwarn_Zuheizer_ein 0;
BA_ "GenSigSendType" SG_ 949 KL_Zustand 0;
BA_ "GenSigSwitchedByIgnition" SG_ 949 KL_Zustand 0;
BA_ "GenSigActiveRepetitions" SG_ 1640 FSH_Taster 5;
BA_ "GenSigSendType" SG_ 1640 FSH_Taster 4;
BA_ "GenSigSwitchedByIgnition" SG_ 1640 FSH_Taster 0;
BA_ "GenSigActiveRepetitions" SG_ 1640 HSH_Taster 5;
BA_ "GenSigSendType" SG_ 1640 HSH_Taster 4;
BA_ "GenSigSwitchedByIgnition" SG_ 1640 HSH_Taster 0;
BA_ "GenSigSendType" SG_ 1640 KL_Beschlagsgefahr 3;
BA_ "GenSigSwitchedByIgnition" SG_ 1640 KL_Beschlagsgefahr 0;
BA_ "GenSigSendType" SG_ 1640 KL_Geblspng_Fond_Soll 0;
BA_ "GenSigSwitchedByIgnition" SG_ 1640 KL_Geblspng_Fond_Soll 0;
BA_ "Fehlerwert" SG_ 1640 KL_Geblspng_Fond_Soll 255;
BA_ "GenSigSendType" SG_ 1640 KL_Geblspng_Soll 0;
BA_ "GenSigSwitchedByIgnition" SG_ 1640 KL_Geblspng_Soll 0;
BA_ "Fehlerwert" SG_ 1640 KL_Geblspng_Soll 255;
BA_ "GenSigSendType" SG_ 1640 KL_I_Geblaese 0;
BA_ "GenSigSwitchedByIgnition" SG_ 1640 KL_I_Geblaese 0;
BA_ "Fehlerwert" SG_ 1640 KL_I_Geblaese 255;
BA_ "GenSigSendType" SG_ 1640 KL_Kompressorstrom_soll 0;
BA_ "GenSigStartValue" SG_ 1640 KL_Kompressorstrom_soll 1022;
BA_ "GenSigSwitchedByIgnition" SG_ 1640 KL_Kompressorstrom_soll 0;
BA_ "Fehlerwert" SG_ 1640 KL_Kompressorstrom_soll 1023;
BA_ "GenSigSendType" SG_ 1640 KL_LRH_Stufe 3;
BA_ "GenSigStartValue" SG_ 1640 KL_LRH_Stufe 1;
BA_ "GenSigSwitchedByIgnition" SG_ 1640 KL_LRH_Stufe 0;
BA_ "GenSigActiveRepetitions" SG_ 1640 KL_LRH_Taster 5;
BA_ "GenSigSendType" SG_ 1640 KL_LRH_Taster 4;
BA_ "GenSigSwitchedByIgnition" SG_ 1640 KL_LRH_Taster 0;
BA_ "GenSigSendType" SG_ 1640 KL_PTC_Verbauinfo 0;
BA_ "GenSigSwitchedByIgnition" SG_ 1640 KL_PTC_Verbauinfo 0;
BA_ "GenSigSendType" SG_ 1640 KL_SIH_Soll_li 3;
BA_ "GenSigSwitchedByIgnition" SG_ 1640 KL_SIH_Soll_li 0;
BA_ "GenSigSendType" SG_ 1640 KL_SIH_Soll_re 3;
BA_ "GenSigSwitchedByIgnition" SG_ 1640 KL_SIH_Soll_re 0;
BA_ "GenSigSendType" SG_ 1640 KL_SIL_Soll_li 3;
BA_ "GenSigSwitchedByIgnition" SG_ 1640 KL_SIL_Soll_li 0;
BA_ "GenSigSendType" SG_ 1640 KL_SIL_Soll_re 3;
BA_ "GenSigSwitchedByIgnition" SG_ 1640 KL_SIL_Soll_re 0;
BA_ "GenSigSendType" SG_ 1640 KL_Umluftklappe_Status 0;
BA_ "GenSigStartValue" SG_ 1640 KL_Umluftklappe_Status 14;
BA_ "GenSigSwitchedByIgnition" SG_ 1640 KL_Umluftklappe_Status 0;
BA_ "Fehlerwert" SG_ 1640 KL_Umluftklappe_Status 15;
BA_ "GenSigSendType" SG_ 1640 KL_Zuheizer_Freigabe 3;
BA_ "GenSigSwitchedByIgnition" SG_ 1640 KL_Zuheizer_Freigabe 0;
BA_ "GenSigSendType" SG_ 1640 KRH_Soll_li 3;
BA_ "GenSigSwitchedByIgnition" SG_ 1640 KRH_Soll_li 0;
BA_ "GenSigSendType" SG_ 1640 KRH_Soll_re 3;
BA_ "GenSigSwitchedByIgnition" SG_ 1640 KRH_Soll_re 0;
BA_ "GenSigSendType" SG_ 1511 KL_BattKond_WaPu_DZMax 0;
BA_ "GenSigStartValue" SG_ 1511 KL_BattKond_WaPu_DZMax 62;
BA_ "GenSigSwitchedByIgnition" SG_ 1511 KL_BattKond_WaPu_DZMax 0;
BA_ "Fehlerwert" SG_ 1511 KL_BattKond_WaPu_DZMax 63;
BA_ "GenSigSendType" SG_ 1511 KL_EKK_Strom 0;
BA_ "GenSigStartValue" SG_ 1511 KL_EKK_Strom 255;
BA_ "GenSigSwitchedByIgnition" SG_ 1511 KL_EKK_Strom 0;
BA_ "GenSigSendType" SG_ 1511 KL_Fehler_HV_EKK 0;
BA_ "GenSigSwitchedByIgnition" SG_ 1511 KL_Fehler_HV_EKK 0;
BA_ "Fehlerwert" SG_ 1511 KL_Fehler_HV_EKK 3;
BA_ "GenSigSendType" SG_ 1511 KL_Fehler_HV_Heizer 0;
BA_ "GenSigSwitchedByIgnition" SG_ 1511 KL_Fehler_HV_Heizer 0;
BA_ "Fehlerwert" SG_ 1511 KL_Fehler_HV_Heizer 3;
BA_ "GenSigSendType" SG_ 1511 KL_HV_Heizer_Strom 0;
BA_ "GenSigStartValue" SG_ 1511 KL_HV_Heizer_Strom 255;
BA_ "GenSigSwitchedByIgnition" SG_ 1511 KL_HV_Heizer_Strom 0;
BA_ "GenSigSendType" SG_ 1511 KL_KM_ASV_01_Status 0;
BA_ "GenSigSwitchedByIgnition" SG_ 1511 KL_KM_ASV_01_Status 0;
BA_ "Fehlerwert" SG_ 1511 KL_KM_ASV_01_Status 3;
BA_ "GenSigSendType" SG_ 1511 KL_KM_ASV_02_Status 0;
BA_ "GenSigSwitchedByIgnition" SG_ 1511 KL_KM_ASV_02_Status 0;
BA_ "Fehlerwert" SG_ 1511 KL_KM_ASV_02_Status 3;
BA_ "GenSigSendType" SG_ 1511 KL_Pumpe_02_Soll 0;
BA_ "GenSigStartValue" SG_ 1511 KL_Pumpe_02_Soll 126;
BA_ "GenSigSwitchedByIgnition" SG_ 1511 KL_Pumpe_02_Soll 0;
BA_ "Fehlerwert" SG_ 1511 KL_Pumpe_02_Soll 127;
BA_ "GenSigSendType" SG_ 1511 KL_Senderkennung 0;
BA_ "GenSigSwitchedByIgnition" SG_ 1511 KL_Senderkennung 0;
BA_ "GenSigSendType" SG_ 1511 KL_Status_EoHVL_EKK 0;
BA_ "GenSigSwitchedByIgnition" SG_ 1511 KL_Status_EoHVL_EKK 0;
BA_ "Fehlerwert" SG_ 1511 KL_Status_EoHVL_EKK 3;
BA_ "GenSigSendType" SG_ 1511 KL_Status_EoHVL_EKK_2 0;
BA_ "GenSigSwitchedByIgnition" SG_ 1511 KL_Status_EoHVL_EKK_2 0;
BA_ "Fehlerwert" SG_ 1511 KL_Status_EoHVL_EKK_2 3;
BA_ "GenSigSendType" SG_ 1511 KL_Status_EoHVL_Heizer 0;
BA_ "GenSigSwitchedByIgnition" SG_ 1511 KL_Status_EoHVL_Heizer 0;
BA_ "Fehlerwert" SG_ 1511 KL_Status_EoHVL_Heizer 3;
BA_ "GenSigSendType" SG_ 1511 KL_Status_EoHVL_Heizer_2 0;
BA_ "GenSigSwitchedByIgnition" SG_ 1511 KL_Status_EoHVL_Heizer_2 0;
BA_ "Fehlerwert" SG_ 1511 KL_Status_EoHVL_Heizer_2 3;
BA_ "GenSigSendType" SG_ 1511 KL_Ventil_03_Soll 0;
BA_ "GenSigSwitchedByIgnition" SG_ 1511 KL_Ventil_03_Soll 0;
BA_ "GenSigSendType" SG_ 1511 KL_Ventil_10_Status 0;
BA_ "GenSigStartValue" SG_ 1511 KL_Ventil_10_Status 6;
BA_ "GenSigSwitchedByIgnition" SG_ 1511 KL_Ventil_10_Status 0;
BA_ "Fehlerwert" SG_ 1511 KL_Ventil_10_Status 7;
BA_ "GenSigSendType" SG_ 1511 KL_Vorwarn_HVHeizer_Leistung 0;
BA_ "GenSigSwitchedByIgnition" SG_ 1511 KL_Vorwarn_HVHeizer_Leistung 0;
BA_ "Fehlerwert" SG_ 1511 KL_Vorwarn_HVHeizer_Leistung 15;
BA_ "GenSigSendType" SG_ 1511 WP_KJ_Soll 0;
BA_ "GenSigSwitchedByIgnition" SG_ 1511 WP_KJ_Soll 0;
BA_ "Fehlerwert" SG_ 1511 WP_KJ_Soll 3;
BA_ "GenSigSendType" SG_ 1511 WP_Kuehlerluefter_Anf 0;
BA_ "GenSigSwitchedByIgnition" SG_ 1511 WP_Kuehlerluefter_Anf 0;
BA_ "Fehlerwert" SG_ 1511 WP_Kuehlerluefter_Anf 255;
BA_ "GenSigSendType" SG_ 1514 KBT_Defrost_aktiv 0;
BA_ "GenSigSwitchedByIgnition" SG_ 1514 KBT_Defrost_aktiv 0;
BA_ "GenSigSendType" SG_ 1514 KL_Fehler_NTKreis 0;
BA_ "GenSigSwitchedByIgnition" SG_ 1514 KL_Fehler_NTKreis 0;
BA_ "Fehlerwert" SG_ 1514 KL_Fehler_NTKreis 1;
BA_ "GenSigSendType" SG_ 1514 KL_Heizbedarf 0;
BA_ "GenSigStartValue" SG_ 1514 KL_Heizbedarf 1022;
BA_ "GenSigSwitchedByIgnition" SG_ 1514 KL_Heizbedarf 0;
BA_ "Fehlerwert" SG_ 1514 KL_Heizbedarf 1023;
BA_ "GenSigSendType" SG_ 1514 KL_Innentemp_KBT_Sensor 0;
BA_ "GenSigStartValue" SG_ 1514 KL_Innentemp_KBT_Sensor 1022;
BA_ "GenSigSwitchedByIgnition" SG_ 1514 KL_Innentemp_KBT_Sensor 0;
BA_ "Fehlerwert" SG_ 1514 KL_Innentemp_KBT_Sensor 1023;
BA_ "GenSigSendType" SG_ 1514 KL_KLE_Fehler_Anf 0;
BA_ "GenSigSwitchedByIgnition" SG_ 1514 KL_KLE_Fehler_Anf 0;
BA_ "GenSigSendType" SG_ 1514 KL_Kundenwunsch_Kuehlen 0;
BA_ "GenSigSwitchedByIgnition" SG_ 1514 KL_Kundenwunsch_Kuehlen 0;
BA_ "GenSigSendType" SG_ 1514 KL_Mot_Tk_Soll_li 0;
BA_ "GenSigSwitchedByIgnition" SG_ 1514 KL_Mot_Tk_Soll_li 0;
BA_ "GenSigSendType" SG_ 1514 KL_Mot_Tk_Soll_re 0;
BA_ "GenSigSwitchedByIgnition" SG_ 1514 KL_Mot_Tk_Soll_re 0;
BA_ "GenSigSendType" SG_ 1514 KL_OBD_Status 0;
BA_ "GenSigSwitchedByIgnition" SG_ 1514 KL_OBD_Status 0;
BA_ "GenSigSendType" SG_ 1514 KL_Standklima_RemoteModus 0;
BA_ "GenSigSwitchedByIgnition" SG_ 1514 KL_Standklima_RemoteModus 0;
BA_ "GenSigSendType" SG_ 1514 KL_Standklima_Status_02 0;
BA_ "GenSigStartValue" SG_ 1514 KL_Standklima_Status_02 6;
BA_ "GenSigSwitchedByIgnition" SG_ 1514 KL_Standklima_Status_02 0;
BA_ "Fehlerwert" SG_ 1514 KL_Standklima_Status_02 7;
BA_ "GenSigSendType" SG_ 1514 KL_Standklima_Status_03 0;
BA_ "GenSigStartValue" SG_ 1514 KL_Standklima_Status_03 6;
BA_ "GenSigSwitchedByIgnition" SG_ 1514 KL_Standklima_Status_03 0;
BA_ "Fehlerwert" SG_ 1514 KL_Standklima_Status_03 7;
BA_ "GenSigSendType" SG_ 1514 KL_VK_Anf 0;
BA_ "GenSigStartValue" SG_ 1514 KL_VK_Anf 6;
BA_ "GenSigSwitchedByIgnition" SG_ 1514 KL_VK_Anf 0;
BA_ "Fehlerwert" SG_ 1514 KL_VK_Anf 7;
BA_ "GenSigSendType" SG_ 1514 KL_VK_Betriebsdauer 0;
BA_ "GenSigStartValue" SG_ 1514 KL_VK_Betriebsdauer 62;
BA_ "GenSigSwitchedByIgnition" SG_ 1514 KL_VK_Betriebsdauer 0;
BA_ "Fehlerwert" SG_ 1514 KL_VK_Betriebsdauer 63;
BA_ "GenSigSendType" SG_ 1514 KL_Vorkond_Strategie 0;
BA_ "GenSigStartValue" SG_ 1514 KL_Vorkond_Strategie 15;
BA_ "GenSigSwitchedByIgnition" SG_ 1514 KL_Vorkond_Strategie 0;
BA_ "GenSigSendType" SG_ 2589283627 KL_EKK_1_VerbautStatus 0;
BA_ "GenSigSwitchedByIgnition" SG_ 2589283627 KL_EKK_1_VerbautStatus 0;
BA_ "GenSigSendType" SG_ 2589283627 KL_EKK_2_VerbautStatus 0;
BA_ "GenSigSwitchedByIgnition" SG_ 2589283627 KL_EKK_2_VerbautStatus 0;
BA_ "GenSigSendType" SG_ 2589283627 KL_Heizen_Status 0;
BA_ "GenSigStartValue" SG_ 2589283627 KL_Heizen_Status 14;
BA_ "GenSigSwitchedByIgnition" SG_ 2589283627 KL_Heizen_Status 0;
BA_ "Fehlerwert" SG_ 2589283627 KL_Heizen_Status 15;
BA_ "GenSigSendType" SG_ 2589283627 KL_HV_Energie_Anf 0;
BA_ "GenSigStartValue" SG_ 2589283627 KL_HV_Energie_Anf 254;
BA_ "GenSigSwitchedByIgnition" SG_ 2589283627 KL_HV_Energie_Anf 0;
BA_ "Fehlerwert" SG_ 2589283627 KL_HV_Energie_Anf 255;
BA_ "GenSigSendType" SG_ 2589283627 KL_HVH_1_VerbautStatus 0;
BA_ "GenSigSwitchedByIgnition" SG_ 2589283627 KL_HVH_1_VerbautStatus 0;
BA_ "GenSigSendType" SG_ 2589283627 KL_HVH_2_VerbautStatus 0;
BA_ "GenSigSwitchedByIgnition" SG_ 2589283627 KL_HVH_2_VerbautStatus 0;
BA_ "GenSigSendType" SG_ 2589283627 KL_IstLeistung 0;
BA_ "GenSigStartValue" SG_ 2589283627 KL_IstLeistung 254;
BA_ "GenSigSwitchedByIgnition" SG_ 2589283627 KL_IstLeistung 0;
BA_ "Fehlerwert" SG_ 2589283627 KL_IstLeistung 255;
BA_ "GenSigSendType" SG_ 2589283627 KL_K_Status 0;
BA_ "GenSigSwitchedByIgnition" SG_ 2589283627 KL_K_Status 0;
BA_ "Fehlerwert" SG_ 2589283627 KL_K_Status 14;
BA_ "GenSigSendType" SG_ 2589283627 Kl_Klima_Aktiv 0;
BA_ "GenSigSwitchedByIgnition" SG_ 2589283627 Kl_Klima_Aktiv 0;
BA_ "GenSigSendType" SG_ 2589283627 KL_Kuehlungs_Status 0;
BA_ "GenSigStartValue" SG_ 2589283627 KL_Kuehlungs_Status 14;
BA_ "GenSigSwitchedByIgnition" SG_ 2589283627 KL_Kuehlungs_Status 0;
BA_ "Fehlerwert" SG_ 2589283627 KL_Kuehlungs_Status 15;
BA_ "GenSigSendType" SG_ 2589283627 KL_Leistung_Klima_Anf 0;
BA_ "GenSigStartValue" SG_ 2589283627 KL_Leistung_Klima_Anf 254;
BA_ "GenSigSwitchedByIgnition" SG_ 2589283627 KL_Leistung_Klima_Anf 0;
BA_ "GenSigSendType" SG_ 2589283627 KL_Status_Battkuehlung 0;
BA_ "GenSigSwitchedByIgnition" SG_ 2589283627 KL_Status_Battkuehlung 0;
BA_ "GenSigSendType" SG_ 2589283627 KL_Temp_Kundenwunsch 0;
BA_ "GenSigSwitchedByIgnition" SG_ 2589283627 KL_Temp_Kundenwunsch 0;
BA_ "Fehlerwert" SG_ 2589283627 KL_Temp_Kundenwunsch 63;
BA_ "GenSigSendType" SG_ 2589283627 KL_Texte 0;
BA_ "GenSigSwitchedByIgnition" SG_ 2589283627 KL_Texte 0;
BA_ "GenSigSendType" SG_ 2589283627 TME_HVEM_HV_Anf 0;
BA_ "GenSigSwitchedByIgnition" SG_ 2589283627 TME_HVEM_HV_Anf 0;
BA_ "Fehlerwert" SG_ 2589283627 TME_HVEM_HV_Anf 3;
BA_ "GenSigSendType" SG_ 2589283574 KL_OBD_Status_Auth 0;
BA_ "GenSigSwitchedByIgnition" SG_ 2589283574 KL_OBD_Status_Auth 0;
BA_ "GenSigSendType" SG_ 2589283574 OBDProtocol_Klima 0;
BA_ "GenSigStartValue" SG_ 2589283574 OBDProtocol_Klima 254;
BA_ "GenSigSwitchedByIgnition" SG_ 2589283574 OBDProtocol_Klima 0;
BA_ "Fehlerwert" SG_ 2589283574 OBDProtocol_Klima 255;
BA_ "GenSigSendType" SG_ 2589283574 SOK_Klima_EV_10_Signatur 0;
BA_ "GenSigFuncType" SG_ 2589283574 SOK_Klima_EV_10_Signatur 15;
BA_ "GenSigSwitchedByIgnition" SG_ 2589283574 SOK_Klima_EV_10_Signatur 0;
BA_ "GenSigSendType" SG_ 1505 BCM1_Aussen_Temp_ungef 0;
BA_ "GenSigStartValue" SG_ 1505 BCM1_Aussen_Temp_ungef 254;
BA_ "GenSigSwitchedByIgnition" SG_ 1505 BCM1_Aussen_Temp_ungef 0;
BA_ "Fehlerwert" SG_ 1505 BCM1_Aussen_Temp_ungef 255;
BA_ "GenSigSendType" SG_ 1505 BCM1_FStatus_Aussentemp_ungef 0;
BA_ "GenSigStartValue" SG_ 1505 BCM1_FStatus_Aussentemp_ungef 1;
BA_ "GenSigSwitchedByIgnition" SG_ 1505 BCM1_FStatus_Aussentemp_ungef 0;
BA_ "GenSigSendType" SG_ 1505 BCM1_Kompressorstrom_ist 0;
BA_ "GenSigStartValue" SG_ 1505 BCM1_Kompressorstrom_ist 254;
BA_ "GenSigSwitchedByIgnition" SG_ 1505 BCM1_Kompressorstrom_ist 0;
BA_ "Fehlerwert" SG_ 1505 BCM1_Kompressorstrom_ist 255;
BA_ "GenSigSendType" SG_ 1505 BCM1_OBD_FStatus_ATemp 0;
BA_ "GenSigSwitchedByIgnition" SG_ 1505 BCM1_OBD_FStatus_ATemp 0;
BA_ "GenSigSendType" SG_ 1505 BCM1_PTC_stufig_Status 0;
BA_ "GenSigStartValue" SG_ 1505 BCM1_PTC_stufig_Status 6;
BA_ "GenSigSwitchedByIgnition" SG_ 1505 BCM1_PTC_stufig_Status 0;
BA_ "Fehlerwert" SG_ 1505 BCM1_PTC_stufig_Status 7;
BA_ "GenSigSendType" SG_ 1505 BCM_Heizungsabsperrventil_Status 0;
BA_ "GenSigStartValue" SG_ 1505 BCM_Heizungsabsperrventil_Status 2;
BA_ "GenSigSwitchedByIgnition" SG_ 1505 BCM_Heizungsabsperrventil_Status 0;
BA_ "Fehlerwert" SG_ 1505 BCM_Heizungsabsperrventil_Status 3;
BA_ "GenSigSendType" SG_ 1505 BCM_Heizungspumpe_Status 0;
BA_ "GenSigStartValue" SG_ 1505 BCM_Heizungspumpe_Status 2;
BA_ "GenSigSwitchedByIgnition" SG_ 1505 BCM_Heizungspumpe_Status 0;
BA_ "Fehlerwert" SG_ 1505 BCM_Heizungspumpe_Status 3;
BA_ "GenSigSendType" SG_ 1505 BCM_Kompressorkupplung_Status 0;
BA_ "GenSigStartValue" SG_ 1505 BCM_Kompressorkupplung_Status 2;
BA_ "GenSigSwitchedByIgnition" SG_ 1505 BCM_Kompressorkupplung_Status 0;
BA_ "Fehlerwert" SG_ 1505 BCM_Kompressorkupplung_Status 3;
BA_ "GenSigSendType" SG_ 1513 AAU_Geblaese 0;
BA_ "GenSigStartValue" SG_ 1513 AAU_Geblaese 126;
BA_ "GenSigSwitchedByIgnition" SG_ 1513 AAU_Geblaese 0;
BA_ "Fehlerwert" SG_ 1513 AAU_Geblaese 127;
BA_ "GenSigSendType" SG_ 1513 DS_Kaeltemittel_P 0;
BA_ "GenSigStartValue" SG_ 1513 DS_Kaeltemittel_P 2046;
BA_ "GenSigSwitchedByIgnition" SG_ 1513 DS_Kaeltemittel_P 0;
BA_ "Fehlerwert" SG_ 1513 DS_Kaeltemittel_P 2047;
BA_ "GenSigSendType" SG_ 1513 DS_Kaeltemittel_P_WP 0;
BA_ "GenSigStartValue" SG_ 1513 DS_Kaeltemittel_P_WP 2046;
BA_ "GenSigSwitchedByIgnition" SG_ 1513 DS_Kaeltemittel_P_WP 0;
BA_ "Fehlerwert" SG_ 1513 DS_Kaeltemittel_P_WP 2047;
BA_ "GenSigSendType" SG_ 1513 DS_Status 0;
BA_ "GenSigStartValue" SG_ 1513 DS_Status 2;
BA_ "GenSigSwitchedByIgnition" SG_ 1513 DS_Status 0;
BA_ "Fehlerwert" SG_ 1513 DS_Status 3;
BA_ "GenSigSendType" SG_ 1513 ION_Status 0;
BA_ "GenSigStartValue" SG_ 1513 ION_Status 2;
BA_ "GenSigSendType" SG_ 1513 ION_Status_LED 0;
BA_ "GenSigSendType" SG_ 1513 ION_Status_Taster 0;
BA_ "GenSigSendType" SG_ 2549088272 Gateway_Abschaltstufe 0;
BA_ "GenSigSwitchedByIgnition" SG_ 2549088272 Gateway_Abschaltstufe 0;
BA_ "GenSigSendType" SG_ 2549088272 Gateway_KompSchutz 0;
BA_ "GenSigSwitchedByIgnition" SG_ 2549088272 Gateway_KompSchutz 0;
BA_ "GenSigSendType" SG_ 2549088272 Gateway_Nachlauftyp 0;
BA_ "GenSigStartValue" SG_ 2549088272 Gateway_Nachlauftyp 2;
BA_ "GenSigSwitchedByIgnition" SG_ 2549088272 Gateway_Nachlauftyp 0;
BA_ "GenSigSendType" SG_ 2549088272 Gateway_Transport_Mode 0;
BA_ "GenSigSwitchedByIgnition" SG_ 2549088272 Gateway_Transport_Mode 0;
BA_ "GenSigSendType" SG_ 2549088272 GW_KD_Fehler 0;
BA_ "GenSigSendType" SG_ 2549088272 KN_GW_DiagPfad 0;
BA_ "GenSigSwitchedByIgnition" SG_ 2549088272 KN_GW_DiagPfad 0;
BA_ "GenSigSendType" SG_ 2549088272 NM_Gateway_Wakeup 0;
BA_ "NWM-WakeupAllowed" SG_ 2549088272 NM_Gateway_Wakeup 1;
BA_ "GenSigSwitchedByIgnition" SG_ 2549088272 NM_Gateway_Wakeup 0;
BA_ "GenSigSendType" SG_ 2549088375 Getriebe_01_Abschaltstufe 0;
BA_ "GenSigSwitchedByIgnition" SG_ 2549088375 Getriebe_01_Abschaltstufe 0;
BA_ "GenSigSendType" SG_ 2549088375 Getriebe_01_KD_Fehler 0;
BA_ "GenSigSwitchedByIgnition" SG_ 2549088375 Getriebe_01_KD_Fehler 0;
BA_ "GenSigSendType" SG_ 2549088375 Getriebe_01_Transport_Mode 0;
BA_ "GenSigSwitchedByIgnition" SG_ 2549088375 Getriebe_01_Transport_Mode 0;
BA_ "GenSigSendType" SG_ 2549088375 Getriebe_KompSchutz 0;
BA_ "GenSigSwitchedByIgnition" SG_ 2549088375 Getriebe_KompSchutz 0;
BA_ "GenSigSendType" SG_ 2549088375 Getriebe_Nachlauftyp 0;
BA_ "GenSigSwitchedByIgnition" SG_ 2549088375 Getriebe_Nachlauftyp 0;
BA_ "GenSigSendType" SG_ 2549088375 KN_Getriebe_01_BusKnockOut 0;
BA_ "GenSigSwitchedByIgnition" SG_ 2549088375 KN_Getriebe_01_BusKnockOut 0;
BA_ "GenSigSendType" SG_ 2549088375 KN_Getriebe_01_BusKnockOutTimer 0;
BA_ "GenSigSwitchedByIgnition" SG_ 2549088375 KN_Getriebe_01_BusKnockOutTimer 0;
BA_ "GenSigSendType" SG_ 2549088375 KN_Getriebe_01_DiagPfad 0;
BA_ "GenSigSwitchedByIgnition" SG_ 2549088375 KN_Getriebe_01_DiagPfad 0;
BA_ "GenSigSendType" SG_ 2549088375 KN_Getriebe_01_ECUKnockOut 0;
BA_ "GenSigSwitchedByIgnition" SG_ 2549088375 KN_Getriebe_01_ECUKnockOut 0;
BA_ "GenSigSendType" SG_ 2549088375 KN_Getriebe_01_ECUKnockOutTimer 0;
BA_ "GenSigSwitchedByIgnition" SG_ 2549088375 KN_Getriebe_01_ECUKnockOutTimer 0;
BA_ "GenSigSendType" SG_ 2549088375 NM_Getriebe_01_Wakeup 0;
BA_ "NWM-WakeupAllowed" SG_ 2549088375 NM_Getriebe_01_Wakeup 1;
BA_ "GenSigSwitchedByIgnition" SG_ 2549088375 NM_Getriebe_01_Wakeup 0;
BA_ "GenSigSendType" SG_ 2549088374 KN_MO_DiagPfad 0;
BA_ "GenSigSwitchedByIgnition" SG_ 2549088374 KN_MO_DiagPfad 0;
BA_ "GenSigSendType" SG_ 2549088374 KN_Motor_BusKnockOut 0;
BA_ "GenSigSwitchedByIgnition" SG_ 2549088374 KN_Motor_BusKnockOut 0;
BA_ "GenSigSendType" SG_ 2549088374 KN_Motor_BusKnockOutTimer 0;
BA_ "GenSigSwitchedByIgnition" SG_ 2549088374 KN_Motor_BusKnockOutTimer 0;
BA_ "GenSigSendType" SG_ 2549088374 KN_Motor_ECUKnockOut 0;
BA_ "GenSigSwitchedByIgnition" SG_ 2549088374 KN_Motor_ECUKnockOut 0;
BA_ "GenSigSendType" SG_ 2549088374 KN_Motor_ECUKnockOutTimer 0;
BA_ "GenSigSwitchedByIgnition" SG_ 2549088374 KN_Motor_ECUKnockOutTimer 0;
BA_ "GenSigSendType" SG_ 2549088374 MO_01_Abschaltstufe 0;
BA_ "GenSigSwitchedByIgnition" SG_ 2549088374 MO_01_Abschaltstufe 0;
BA_ "GenSigSendType" SG_ 2549088374 MO_01_Transport_Mode 0;
BA_ "GenSigSwitchedByIgnition" SG_ 2549088374 MO_01_Transport_Mode 0;
BA_ "GenSigSendType" SG_ 2549088374 MO_KD_Fehler 0;
BA_ "GenSigSwitchedByIgnition" SG_ 2549088374 MO_KD_Fehler 0;
BA_ "GenSigSendType" SG_ 2549088374 Motor_KompSchutz 0;
BA_ "GenSigSwitchedByIgnition" SG_ 2549088374 Motor_KompSchutz 0;
BA_ "GenSigSendType" SG_ 2549088374 Motor_Nachlauftyp 0;
BA_ "GenSigStartValue" SG_ 2549088374 Motor_Nachlauftyp 2;
BA_ "GenSigSwitchedByIgnition" SG_ 2549088374 Motor_Nachlauftyp 0;
BA_ "GenSigSendType" SG_ 2549088374 NM_MO_01_Wakeup 0;
BA_ "NWM-WakeupAllowed" SG_ 2549088374 NM_MO_01_Wakeup 1;
BA_ "GenSigSwitchedByIgnition" SG_ 2549088374 NM_MO_01_Wakeup 0;
BA_ "GenSigSendType" SG_ 779 KBI_ABS_Lampe 0;
BA_ "GenSigSwitchedByIgnition" SG_ 779 KBI_ABS_Lampe 0;
BA_ "GenSigSendType" SG_ 779 KBI_Airbag_Lampe 0;
BA_ "GenSigSwitchedByIgnition" SG_ 779 KBI_Airbag_Lampe 0;
BA_ "GenSigSendType" SG_ 779 KBI_angez_Geschw 0;
BA_ "GenSigSwitchedByIgnition" SG_ 779 KBI_angez_Geschw 0;
BA_ "GenSigSendType" SG_ 779 KBI_Anzeigefehler_LDW 0;
BA_ "GenSigSwitchedByIgnition" SG_ 779 KBI_Anzeigefehler_LDW 0;
BA_ "GenSigSendType" SG_ 779 KBI_Anzeigefehler_NV 0;
BA_ "GenSigSwitchedByIgnition" SG_ 779 KBI_Anzeigefehler_NV 0;
BA_ "GenSigSendType" SG_ 779 KBI_Anzeigefehler_SWA 0;
BA_ "GenSigSwitchedByIgnition" SG_ 779 KBI_Anzeigefehler_SWA 0;
BA_ "GenSigSendType" SG_ 779 KBI_Anzeigestatus_ACC 0;
BA_ "GenSigSwitchedByIgnition" SG_ 779 KBI_Anzeigestatus_ACC 0;
BA_ "GenSigSendType" SG_ 779 KBI_Anzeigestatus_GRA 0;
BA_ "GenSigSwitchedByIgnition" SG_ 779 KBI_Anzeigestatus_GRA 0;
BA_ "Fehlerwert" SG_ 779 KBI_Anzeigestatus_GRA 3;
BA_ "GenSigSendType" SG_ 779 KBI_Anzeigestatus_LIM 0;
BA_ "GenSigSwitchedByIgnition" SG_ 779 KBI_Anzeigestatus_LIM 0;
BA_ "Fehlerwert" SG_ 779 KBI_Anzeigestatus_LIM 3;
BA_ "GenSigSendType" SG_ 779 KBI_Anzeigestatus_RHP 0;
BA_ "GenSigSwitchedByIgnition" SG_ 779 KBI_Anzeigestatus_RHP 0;
BA_ "GenSigSendType" SG_ 779 KBI_ARA_in_Anzeige 0;
BA_ "GenSigSwitchedByIgnition" SG_ 779 KBI_ARA_in_Anzeige 0;
BA_ "GenSigSendType" SG_ 779 KBI_Audioabsenkung_MIB 0;
BA_ "GenSigSwitchedByIgnition" SG_ 779 KBI_Audioabsenkung_MIB 0;
BA_ "GenSigSendType" SG_ 779 KBI_Bestaetigung_ESP_Off 0;
BA_ "GenSigSwitchedByIgnition" SG_ 779 KBI_Bestaetigung_ESP_Off 0;
BA_ "GenSigSendType" SG_ 779 KBI_BKL_Lampe 0;
BA_ "GenSigSwitchedByIgnition" SG_ 779 KBI_BKL_Lampe 0;
BA_ "GenSigSendType" SG_ 779 KBI_ESP_Lampe 0;
BA_ "GenSigSwitchedByIgnition" SG_ 779 KBI_ESP_Lampe 0;
BA_ "GenSigSendType" SG_ 779 KBI_Fehler_Anzeige_ACC 0;
BA_ "GenSigSwitchedByIgnition" SG_ 779 KBI_Fehler_Anzeige_ACC 0;
BA_ "GenSigSendType" SG_ 779 KBI_Handbremse 0;
BA_ "GenSigSwitchedByIgnition" SG_ 779 KBI_Handbremse 0;
BA_ "GenSigSendType" SG_ 779 KBI_im_Stellgliedtest 0;
BA_ "GenSigSwitchedByIgnition" SG_ 779 KBI_im_Stellgliedtest 0;
BA_ "GenSigSendType" SG_ 779 KBI_Konsistenz_ACC 0;
BA_ "GenSigSwitchedByIgnition" SG_ 779 KBI_Konsistenz_ACC 0;
BA_ "GenSigSendType" SG_ 779 KBI_Lenkung_Lampe 0;
BA_ "GenSigSwitchedByIgnition" SG_ 779 KBI_Lenkung_Lampe 0;
BA_ "GenSigSendType" SG_ 779 KBI_MFA_v_Einheit_01 0;
BA_ "GenSigSwitchedByIgnition" SG_ 779 KBI_MFA_v_Einheit_01 0;
BA_ "GenSigSendType" SG_ 779 KBI_NV_in_Anzeige 0;
BA_ "GenSigSwitchedByIgnition" SG_ 779 KBI_NV_in_Anzeige 0;
BA_ "GenSigSendType" SG_ 779 KBI_Oeldruck_Schalter 0;
BA_ "GenSigSwitchedByIgnition" SG_ 779 KBI_Oeldruck_Schalter 0;
BA_ "GenSigSendType" SG_ 779 KBI_Oeldruckwarnung 0;
BA_ "GenSigSwitchedByIgnition" SG_ 779 KBI_Oeldruckwarnung 0;
BA_ "GenSigSendType" SG_ 779 KBI_PLA_in_Anzeige 0;
BA_ "GenSigSwitchedByIgnition" SG_ 779 KBI_PLA_in_Anzeige 0;
BA_ "GenSigSendType" SG_ 779 KBI_SILA_gueltig 0;
BA_ "GenSigSwitchedByIgnition" SG_ 779 KBI_SILA_gueltig 0;
BA_ "GenSigSendType" SG_ 779 KBI_Systemstatus 0;
BA_ "GenSigSwitchedByIgnition" SG_ 779 KBI_Systemstatus 0;
BA_ "GenSigSendType" SG_ 779 KBI_Tankwarnung 0;
BA_ "GenSigSwitchedByIgnition" SG_ 779 KBI_Tankwarnung 0;
BA_ "GenSigSendType" SG_ 779 KBI_Tankwarnung_ungueltig 0;
BA_ "GenSigStartValue" SG_ 779 KBI_Tankwarnung_ungueltig 1;
BA_ "GenSigSwitchedByIgnition" SG_ 779 KBI_Tankwarnung_ungueltig 0;
BA_ "GenSigSendType" SG_ 779 KBI_Taster_Fahrwerk 0;
BA_ "GenSigSwitchedByIgnition" SG_ 779 KBI_Taster_Fahrwerk 0;
BA_ "GenSigSendType" SG_ 779 KBI_Taster_Lift 0;
BA_ "GenSigSwitchedByIgnition" SG_ 779 KBI_Taster_Lift 0;
BA_ "GenSigSendType" SG_ 779 KBI_V_Digital 0;
BA_ "GenSigSwitchedByIgnition" SG_ 779 KBI_V_Digital 0;
BA_ "GenSigSendType" SG_ 779 KBI_Vorglueh_System_Lampe 0;
BA_ "GenSigSwitchedByIgnition" SG_ 779 KBI_Vorglueh_System_Lampe 0;
BA_ "GenSigSendType" SG_ 779 Kombi_01_BZ 0;
BA_ "GenSigFuncType" SG_ 779 Kombi_01_BZ 1;
BA_ "GenSigSwitchedByIgnition" SG_ 779 Kombi_01_BZ 0;
BA_ "GenSigSendType" SG_ 1719 KBI_aktive_Laengsfunktion_02 3;
BA_ "GenSigSendType" SG_ 1719 KBI_Aussen_Temp_gef 0;
BA_ "GenSigStartValue" SG_ 1719 KBI_Aussen_Temp_gef 254;
BA_ "GenSigSwitchedByIgnition" SG_ 1719 KBI_Aussen_Temp_gef 0;
BA_ "Fehlerwert" SG_ 1719 KBI_Aussen_Temp_gef 255;
BA_ "GenSigSendType" SG_ 1719 KBI_FoD_PopUP_Quittiert 3;
BA_ "GenSigSendType" SG_ 1719 KBI_FStatus_Tank 0;
BA_ "GenSigSwitchedByIgnition" SG_ 1719 KBI_FStatus_Tank 0;
BA_ "GenSigSendType" SG_ 1719 KBI_GRA_im_ACC 3;
BA_ "GenSigSwitchedByIgnition" SG_ 1719 KBI_GRA_im_ACC 0;
BA_ "GenSigSendType" SG_ 1719 KBI_Inhalt_Tank 0;
BA_ "GenSigStartValue" SG_ 1719 KBI_Inhalt_Tank 126;
BA_ "GenSigSwitchedByIgnition" SG_ 1719 KBI_Inhalt_Tank 0;
BA_ "Fehlerwert" SG_ 1719 KBI_Inhalt_Tank 127;
BA_ "GenSigSendType" SG_ 1719 KBI_Kilometerstand 0;
BA_ "GenSigStartValue" SG_ 1719 KBI_Kilometerstand 1048574;
BA_ "GenSigSwitchedByIgnition" SG_ 1719 KBI_Kilometerstand 0;
BA_ "Fehlerwert" SG_ 1719 KBI_Kilometerstand 1048575;
BA_ "GenSigSendType" SG_ 1719 KBI_Oelwechsel_durchgefuehrt 0;
BA_ "GenSigSwitchedByIgnition" SG_ 1719 KBI_Oelwechsel_durchgefuehrt 0;
BA_ "GenSigSendType" SG_ 1719 KBI_QBit_Aussen_Temp_gef 0;
BA_ "GenSigStartValue" SG_ 1719 KBI_QBit_Aussen_Temp_gef 1;
BA_ "GenSigSwitchedByIgnition" SG_ 1719 KBI_QBit_Aussen_Temp_gef 0;
BA_ "GenSigSendType" SG_ 1719 KBI_RDK_Kalibrier_Anf 3;
BA_ "GenSigSwitchedByIgnition" SG_ 1719 KBI_RDK_Kalibrier_Anf 0;
BA_ "GenSigSendType" SG_ 1719 KBI_Reserve_Warnung_Sek 3;
BA_ "GenSigSwitchedByIgnition" SG_ 1719 KBI_Reserve_Warnung_Sek 0;
BA_ "GenSigSendType" SG_ 1719 KBI_Standzeit_02 0;
BA_ "GenSigStartValue" SG_ 1719 KBI_Standzeit_02 131070;
BA_ "GenSigSwitchedByIgnition" SG_ 1719 KBI_Standzeit_02 0;
BA_ "Fehlerwert" SG_ 1719 KBI_Standzeit_02 131071;
BA_ "GenSigSendType" SG_ 1720 KBI_BCmE_aktiv 0;
BA_ "GenSigSwitchedByIgnition" SG_ 1720 KBI_BCmE_aktiv 0;
BA_ "GenSigSendType" SG_ 1720 KBI_GAP_Warn_Zeit_abgelaufen 0;
BA_ "GenSigSwitchedByIgnition" SG_ 1720 KBI_GAP_Warn_Zeit_abgelaufen 0;
BA_ "GenSigSendType" SG_ 1720 KBI_Max_Tankinhalt 0;
BA_ "GenSigStartValue" SG_ 1720 KBI_Max_Tankinhalt 254;
BA_ "GenSigSwitchedByIgnition" SG_ 1720 KBI_Max_Tankinhalt 0;
BA_ "Fehlerwert" SG_ 1720 KBI_Max_Tankinhalt 255;
BA_ "GenSigSendType" SG_ 1720 KBI_Nachtanken_erkannt 0;
BA_ "GenSigSwitchedByIgnition" SG_ 1720 KBI_Nachtanken_erkannt 0;
BA_ "GenSigSendType" SG_ 1720 KBI_Quittierung_cAQP 0;
BA_ "GenSigSwitchedByIgnition" SG_ 1720 KBI_Quittierung_cAQP 0;
BA_ "GenSigSendType" SG_ 1720 KBI_Quittierung_Naesse 0;
BA_ "GenSigSwitchedByIgnition" SG_ 1720 KBI_Quittierung_Naesse 0;
BA_ "GenSigSendType" SG_ 1720 KBI_Reifenumfang 0;
BA_ "GenSigFuncType" SG_ 1720 KBI_Reifenumfang 8;
BA_ "GenSigSwitchedByIgnition" SG_ 1720 KBI_Reifenumfang 0;
BA_ "GenSigSendType" SG_ 1720 KBI_Reifenumfang_Sekundaer 0;
BA_ "GenSigSwitchedByIgnition" SG_ 1720 KBI_Reifenumfang_Sekundaer 0;
BA_ "GenSigSendType" SG_ 1720 KBI_Sparhinweis_quittiert 0;
BA_ "GenSigSwitchedByIgnition" SG_ 1720 KBI_Sparhinweis_quittiert 0;
BA_ "GenSigSendType" SG_ 1720 KBI_Tankfuellstand_Prozent 0;
BA_ "GenSigStartValue" SG_ 1720 KBI_Tankfuellstand_Prozent 126;
BA_ "GenSigSwitchedByIgnition" SG_ 1720 KBI_Tankfuellstand_Prozent 0;
BA_ "Fehlerwert" SG_ 1720 KBI_Tankfuellstand_Prozent 127;
BA_ "GenSigSendType" SG_ 1720 KBI_Tankinhalt_hochaufl 0;
BA_ "GenSigStartValue" SG_ 1720 KBI_Tankinhalt_hochaufl 16382;
BA_ "GenSigSwitchedByIgnition" SG_ 1720 KBI_Tankinhalt_hochaufl 0;
BA_ "Fehlerwert" SG_ 1720 KBI_Tankinhalt_hochaufl 16383;
BA_ "GenSigSendType" SG_ 1720 KBI_Variante 0;
BA_ "GenSigSwitchedByIgnition" SG_ 1720 KBI_Variante 0;
BA_ "GenSigSendType" SG_ 1720 KBI_Variante_USA 0;
BA_ "GenSigSwitchedByIgnition" SG_ 1720 KBI_Variante_USA 0;
BA_ "GenSigSendType" SG_ 2589283631 KBI_BC_Reset_E1 0;
BA_ "GenSigStartValue" SG_ 2589283631 KBI_BC_Reset_E1 7;
BA_ "GenSigSwitchedByIgnition" SG_ 2589283631 KBI_BC_Reset_E1 0;
BA_ "GenSigSendType" SG_ 2589283631 KBI_BC_Reset_E2 0;
BA_ "GenSigStartValue" SG_ 2589283631 KBI_BC_Reset_E2 7;
BA_ "GenSigSwitchedByIgnition" SG_ 2589283631 KBI_BC_Reset_E2 0;
BA_ "GenSigSendType" SG_ 2589283631 KBI_BC_Reset_E3 0;
BA_ "GenSigStartValue" SG_ 2589283631 KBI_BC_Reset_E3 7;
BA_ "GenSigSwitchedByIgnition" SG_ 2589283631 KBI_BC_Reset_E3 0;
BA_ "GenSigSendType" SG_ 2589283631 KBI_Kilometerstand_HiRes 0;
BA_ "GenSigSwitchedByIgnition" SG_ 2589283631 KBI_Kilometerstand_HiRes 0;
BA_ "GenSigSendType" SG_ 2589283631 KBI_Tankinhalt_roh 0;
BA_ "GenSigStartValue" SG_ 2589283631 KBI_Tankinhalt_roh 2046;
BA_ "GenSigSwitchedByIgnition" SG_ 2589283631 KBI_Tankinhalt_roh 0;
BA_ "Fehlerwert" SG_ 2589283631 KBI_Tankinhalt_roh 2047;
BA_ "GenSigSendType" SG_ 285 EPS_02_BZ 0;
BA_ "GenSigFuncType" SG_ 285 EPS_02_BZ 1;
BA_ "GenSigSwitchedByIgnition" SG_ 285 EPS_02_BZ 0;
BA_ "GenSigSendType" SG_ 285 EPS_02_CRC 0;
BA_ "GenSigFuncType" SG_ 285 EPS_02_CRC 2;
BA_ "GenSigSwitchedByIgnition" SG_ 285 EPS_02_CRC 0;
BA_ "GenSigSendType" SG_ 285 EPS_Drehzahlreserve 0;
BA_ "GenSigStartValue" SG_ 285 EPS_Drehzahlreserve 126;
BA_ "GenSigSwitchedByIgnition" SG_ 285 EPS_Drehzahlreserve 0;
BA_ "Fehlerwert" SG_ 285 EPS_Drehzahlreserve 127;
BA_ "GenSigSendType" SG_ 285 EPS_Lastinfo 0;
BA_ "GenSigStartValue" SG_ 285 EPS_Lastinfo 254;
BA_ "GenSigSwitchedByIgnition" SG_ 285 EPS_Lastinfo 0;
BA_ "Fehlerwert" SG_ 285 EPS_Lastinfo 255;
BA_ "GenSigSendType" SG_ 285 EPS_Leistungsanforderung 0;
BA_ "GenSigSwitchedByIgnition" SG_ 285 EPS_Leistungsanforderung 0;
BA_ "GenSigSendType" SG_ 285 EPS_Motorstartverzoegerung 0;
BA_ "GenSigSwitchedByIgnition" SG_ 285 EPS_Motorstartverzoegerung 0;
BA_ "GenSigSendType" SG_ 285 EPS_Notlauf 0;
BA_ "GenSigSwitchedByIgnition" SG_ 285 EPS_Notlauf 0;
BA_ "GenSigSendType" SG_ 285 EPS_StartStopp_Info 3;
BA_ "GenSigSwitchedByIgnition" SG_ 285 EPS_StartStopp_Info 0;
BA_ "GenSigSendType" SG_ 285 EPS_Unterstuetzungsleistung 0;
BA_ "GenSigStartValue" SG_ 285 EPS_Unterstuetzungsleistung 254;
BA_ "GenSigSwitchedByIgnition" SG_ 285 EPS_Unterstuetzungsleistung 0;
BA_ "Fehlerwert" SG_ 285 EPS_Unterstuetzungsleistung 255;
BA_ "GenSigSendType" SG_ 285 EPS_Versorgungsspannung 0;
BA_ "GenSigStartValue" SG_ 285 EPS_Versorgungsspannung 254;
BA_ "GenSigSwitchedByIgnition" SG_ 285 EPS_Versorgungsspannung 0;
BA_ "Fehlerwert" SG_ 285 EPS_Versorgungsspannung 255;
BA_ "GenSigSendType" SG_ 285 EPS_VZ_Drehzahlreserve 0;
BA_ "GenSigSwitchedByIgnition" SG_ 285 EPS_VZ_Drehzahlreserve 0;
BA_ "GenSigSendType" SG_ 285 EPS_Warmstartunterstuetzung 0;
BA_ "GenSigSwitchedByIgnition" SG_ 285 EPS_Warmstartunterstuetzung 0;
BA_ "GenSigSendType" SG_ 982 BCM2_Bremsl_durch_ECD 0;
BA_ "GenSigSwitchedByIgnition" SG_ 982 BCM2_Bremsl_durch_ECD 0;
BA_ "GenSigSendType" SG_ 982 BCM2_Bremsl_durch_ECD_invers 0;
BA_ "GenSigStartValue" SG_ 982 BCM2_Bremsl_durch_ECD_invers 1;
BA_ "GenSigSwitchedByIgnition" SG_ 982 BCM2_Bremsl_durch_ECD_invers 0;
BA_ "GenSigSendType" SG_ 982 LH_3_Bremsl_def 0;
BA_ "GenSigSwitchedByIgnition" SG_ 982 LH_3_Bremsl_def 0;
BA_ "GenSigSendType" SG_ 982 LH_Aussenlicht_def 0;
BA_ "GenSigSwitchedByIgnition" SG_ 982 LH_Aussenlicht_def 0;
BA_ "GenSigSendType" SG_ 982 LH_Blinker_HL_akt 0;
BA_ "GenSigSwitchedByIgnition" SG_ 982 LH_Blinker_HL_akt 0;
BA_ "GenSigSendType" SG_ 982 LH_Blinker_HR_akt 0;
BA_ "GenSigSwitchedByIgnition" SG_ 982 LH_Blinker_HR_akt 0;
BA_ "GenSigSendType" SG_ 982 LH_Blinker_li_def 0;
BA_ "GenSigSwitchedByIgnition" SG_ 982 LH_Blinker_li_def 0;
BA_ "GenSigSendType" SG_ 982 LH_Blinker_re_def 0;
BA_ "GenSigSwitchedByIgnition" SG_ 982 LH_Blinker_re_def 0;
BA_ "GenSigSendType" SG_ 982 LH_Brems_Blk_li_def 0;
BA_ "GenSigSwitchedByIgnition" SG_ 982 LH_Brems_Blk_li_def 0;
BA_ "GenSigSendType" SG_ 982 LH_Brems_Blk_re_def 0;
BA_ "GenSigSwitchedByIgnition" SG_ 982 LH_Brems_Blk_re_def 0;
BA_ "GenSigSendType" SG_ 982 LH_Bremsl_li_def 0;
BA_ "GenSigSwitchedByIgnition" SG_ 982 LH_Bremsl_li_def 0;
BA_ "GenSigSendType" SG_ 982 LH_Bremsl_li_ges_def 0;
BA_ "GenSigSwitchedByIgnition" SG_ 982 LH_Bremsl_li_ges_def 0;
BA_ "GenSigSendType" SG_ 982 LH_Bremsl_re_def 0;
BA_ "GenSigSwitchedByIgnition" SG_ 982 LH_Bremsl_re_def 0;
BA_ "GenSigSendType" SG_ 982 LH_Bremsl_re_ges_def 0;
BA_ "GenSigSwitchedByIgnition" SG_ 982 LH_Bremsl_re_ges_def 0;
BA_ "GenSigSendType" SG_ 982 LH_Bremslicht_H_aktiv 0;
BA_ "GenSigSwitchedByIgnition" SG_ 982 LH_Bremslicht_H_aktiv 0;
BA_ "GenSigSendType" SG_ 982 LH_Diag_LED_li_def 0;
BA_ "GenSigSwitchedByIgnition" SG_ 982 LH_Diag_LED_li_def 0;
BA_ "GenSigSendType" SG_ 982 LH_Diag_LED_re_def 0;
BA_ "GenSigSwitchedByIgnition" SG_ 982 LH_Diag_LED_re_def 0;
BA_ "GenSigSendType" SG_ 982 LH_Diag_Status_li_def 0;
BA_ "GenSigSwitchedByIgnition" SG_ 982 LH_Diag_Status_li_def 0;
BA_ "GenSigSendType" SG_ 982 LH_Diag_Status_re_def 0;
BA_ "GenSigSwitchedByIgnition" SG_ 982 LH_Diag_Status_re_def 0;
BA_ "GenSigSendType" SG_ 982 LH_Kennzl_def 0;
BA_ "GenSigSwitchedByIgnition" SG_ 982 LH_Kennzl_def 0;
BA_ "GenSigSendType" SG_ 982 LH_Nebel_li_def 0;
BA_ "GenSigSwitchedByIgnition" SG_ 982 LH_Nebel_li_def 0;
BA_ "GenSigSendType" SG_ 982 LH_Nebel_mi_def 0;
BA_ "GenSigSwitchedByIgnition" SG_ 982 LH_Nebel_mi_def 0;
BA_ "GenSigSendType" SG_ 982 LH_Nebel_re_def 0;
BA_ "GenSigSwitchedByIgnition" SG_ 982 LH_Nebel_re_def 0;
BA_ "GenSigSendType" SG_ 982 LH_Nebelschluss_aktiv 0;
BA_ "GenSigSwitchedByIgnition" SG_ 982 LH_Nebelschluss_aktiv 0;
BA_ "GenSigSendType" SG_ 982 LH_Parklicht_HL_aktiv 0;
BA_ "GenSigSwitchedByIgnition" SG_ 982 LH_Parklicht_HL_aktiv 0;
BA_ "GenSigSendType" SG_ 982 LH_Parklicht_HR_aktiv 0;
BA_ "GenSigSwitchedByIgnition" SG_ 982 LH_Parklicht_HR_aktiv 0;
BA_ "GenSigSendType" SG_ 982 LH_Rueckf_li_def 0;
BA_ "GenSigSwitchedByIgnition" SG_ 982 LH_Rueckf_li_def 0;
BA_ "GenSigSendType" SG_ 982 LH_Rueckf_mi_def 0;
BA_ "GenSigSwitchedByIgnition" SG_ 982 LH_Rueckf_mi_def 0;
BA_ "GenSigSendType" SG_ 982 LH_Rueckf_re_def 0;
BA_ "GenSigSwitchedByIgnition" SG_ 982 LH_Rueckf_re_def 0;
BA_ "GenSigSendType" SG_ 982 LH_Rueckfahrlicht_aktiv 0;
BA_ "GenSigSwitchedByIgnition" SG_ 982 LH_Rueckfahrlicht_aktiv 0;
BA_ "GenSigSendType" SG_ 982 LH_Schluss_Brems_li_def 0;
BA_ "GenSigSwitchedByIgnition" SG_ 982 LH_Schluss_Brems_li_def 0;
BA_ "GenSigSendType" SG_ 982 LH_Schluss_Brems_Nebel_li_def 0;
BA_ "GenSigSwitchedByIgnition" SG_ 982 LH_Schluss_Brems_Nebel_li_def 0;
BA_ "GenSigSendType" SG_ 982 LH_Schluss_Brems_Nebel_re_def 0;
BA_ "GenSigSwitchedByIgnition" SG_ 982 LH_Schluss_Brems_Nebel_re_def 0;
BA_ "GenSigSendType" SG_ 982 LH_Schluss_Brems_re_def 0;
BA_ "GenSigSwitchedByIgnition" SG_ 982 LH_Schluss_Brems_re_def 0;
BA_ "GenSigSendType" SG_ 982 LH_Schluss_Nebel_li_def 0;
BA_ "GenSigSwitchedByIgnition" SG_ 982 LH_Schluss_Nebel_li_def 0;
BA_ "GenSigSendType" SG_ 982 LH_Schluss_Nebel_re_def 0;
BA_ "GenSigSwitchedByIgnition" SG_ 982 LH_Schluss_Nebel_re_def 0;
BA_ "GenSigSendType" SG_ 982 LH_Schlusslicht_li_def 0;
BA_ "GenSigSwitchedByIgnition" SG_ 982 LH_Schlusslicht_li_def 0;
BA_ "GenSigSendType" SG_ 982 LH_Schlusslicht_re_def 0;
BA_ "GenSigSwitchedByIgnition" SG_ 982 LH_Schlusslicht_re_def 0;
BA_ "GenSigSendType" SG_ 982 LH_SL_BRL_BLK_li_def 0;
BA_ "GenSigSwitchedByIgnition" SG_ 982 LH_SL_BRL_BLK_li_def 0;
BA_ "GenSigSendType" SG_ 982 LH_SL_BRL_BLK_re_def 0;
BA_ "GenSigSwitchedByIgnition" SG_ 982 LH_SL_BRL_BLK_re_def 0;
BA_ "GenSigSendType" SG_ 982 LH_Standlicht_H_aktiv 0;
BA_ "GenSigSwitchedByIgnition" SG_ 982 LH_Standlicht_H_aktiv 0;
BA_ "GenSigSendType" SG_ 982 LH_Zusatzschlussl_def 0;
BA_ "GenSigSwitchedByIgnition" SG_ 982 LH_Zusatzschlussl_def 0;
BA_ "GenSigSendType" SG_ 982 Licht_hinten_01_BZ 0;
BA_ "GenSigFuncType" SG_ 982 Licht_hinten_01_BZ 1;
BA_ "GenSigSwitchedByIgnition" SG_ 982 Licht_hinten_01_BZ 0;
BA_ "GenSigSendType" SG_ 2527679634 LSH_Fehlerstatus 0;
BA_ "GenSigSwitchedByIgnition" SG_ 2527679634 LSH_Fehlerstatus 0;
BA_ "GenSigSendType" SG_ 2527679634 LSH_Heizleistung 0;
BA_ "GenSigSwitchedByIgnition" SG_ 2527679634 LSH_Heizleistung 0;
BA_ "GenSigSendType" SG_ 2527679634 LSH_KL_DBetr_Anf 0;
BA_ "GenSigSwitchedByIgnition" SG_ 2527679634 LSH_KL_DBetr_Anf 0;
BA_ "GenSigSendType" SG_ 2527679634 LSH_KVS 0;
BA_ "GenSigSwitchedByIgnition" SG_ 2527679634 LSH_KVS 0;
BA_ "GenSigSendType" SG_ 2527679634 LSH_KVS_Ueberlauf 0;
BA_ "GenSigSwitchedByIgnition" SG_ 2527679634 LSH_KVS_Ueberlauf 0;
BA_ "GenSigSendType" SG_ 2527679634 LSH_Zuheizen 0;
BA_ "GenSigSwitchedByIgnition" SG_ 2527679634 LSH_Zuheizen 0;
BA_ "GenSigSendType" SG_ 134 LWI_01_BZ 0;
BA_ "GenSigFuncType" SG_ 134 LWI_01_BZ 1;
BA_ "GenSigSendType" SG_ 134 LWI_01_CRC 0;
BA_ "GenSigFuncType" SG_ 134 LWI_01_CRC 2;
BA_ "GenSigSwitchedByIgnition" SG_ 134 LWI_01_CRC 0;
BA_ "GenSigSendType" SG_ 134 LWI_Lenkradw_Geschw 0;
BA_ "GenSigStartValue" SG_ 134 LWI_Lenkradw_Geschw 510;
BA_ "Fehlerwert" SG_ 134 LWI_Lenkradw_Geschw 511;
BA_ "GenSigSendType" SG_ 134 LWI_Lenkradwinkel 0;
BA_ "GenSigStartValue" SG_ 134 LWI_Lenkradwinkel 8190;
BA_ "Fehlerwert" SG_ 134 LWI_Lenkradwinkel 8191;
BA_ "GenSigSendType" SG_ 134 LWI_QBit_Lenkradwinkel 0;
BA_ "GenSigStartValue" SG_ 134 LWI_QBit_Lenkradwinkel 1;
BA_ "GenSigSendType" SG_ 134 LWI_QBit_Sub_Daten 0;
BA_ "GenSigSendType" SG_ 134 LWI_Sensorstatus 0;
BA_ "GenSigSendType" SG_ 134 LWI_Sub_Daten 0;
BA_ "GenSigSendType" SG_ 134 LWI_VZ_Lenkradw_Geschw 0;
BA_ "GenSigSendType" SG_ 134 LWI_VZ_Lenkradwinkel 0;
BA_ "GenSigSendType" SG_ 1153 DSSS_Warning 3;
BA_ "GenSigSwitchedByIgnition" SG_ 1153 DSSS_Warning 0;
BA_ "GenSigSendType" SG_ 1153 MIB_ASW_Diagnose 0;
BA_ "GenSigSwitchedByIgnition" SG_ 1153 MIB_ASW_Diagnose 0;
BA_ "GenSigSendType" SG_ 1153 MIB_Tongenerator_PH_verfuegbar 3;
BA_ "GenSigSwitchedByIgnition" SG_ 1153 MIB_Tongenerator_PH_verfuegbar 0;
BA_ "GenSigSendType" SG_ 1153 MMI_Counter_Bedienevent 0;
BA_ "GenSigSwitchedByIgnition" SG_ 1153 MMI_Counter_Bedienevent 0;
BA_ "GenSigSendType" SG_ 1153 MMI_Gurt_Mic_ref 3;
BA_ "GenSigSwitchedByIgnition" SG_ 1153 MMI_Gurt_Mic_ref 0;
BA_ "GenSigSendType" SG_ 1153 MMI_SDS_aktiv 3;
BA_ "GenSigSwitchedByIgnition" SG_ 1153 MMI_SDS_aktiv 0;
BA_ "GenSigSendType" SG_ 1153 MMI_Telefon_aktiv 3;
BA_ "GenSigSwitchedByIgnition" SG_ 1153 MMI_Telefon_aktiv 0;
BA_ "GenSigSendType" SG_ 1153 MU_SecondDisplay 3;
BA_ "GenSigSwitchedByIgnition" SG_ 1153 MU_SecondDisplay 0;
BA_ "GenSigSendType" SG_ 1153 MU_Update_Time 0;
BA_ "GenSigSwitchedByIgnition" SG_ 1153 MU_Update_Time 0;
BA_ "GenSigSendType" SG_ 1153 Nav_FoD_Status 0;
BA_ "GenSigSwitchedByIgnition" SG_ 1153 Nav_FoD_Status 0;
BA_ "GenSigSendType" SG_ 1153 ZR_AppConnect_Zustand 4;
BA_ "GenSigSwitchedByIgnition" SG_ 1153 ZR_AppConnect_Zustand 0;
BA_ "GenSigSendType" SG_ 1153 ZR_Kindersicherung_RSE 3;
BA_ "GenSigSwitchedByIgnition" SG_ 1153 ZR_Kindersicherung_RSE 0;
BA_ "GenSigSendType" SG_ 1153 ZR_Lichter_Tag 3;
BA_ "GenSigSwitchedByIgnition" SG_ 1153 ZR_Lichter_Tag 0;
BA_ "GenSigSendType" SG_ 1153 ZR_LoGeWa_Event_Kombiwarnung 3;
BA_ "GenSigSwitchedByIgnition" SG_ 1153 ZR_LoGeWa_Event_Kombiwarnung 0;
BA_ "GenSigSendType" SG_ 1153 ZR_Parken_Sondermodus 3;
BA_ "GenSigSwitchedByIgnition" SG_ 1153 ZR_Parken_Sondermodus 0;
BA_ "GenSigSendType" SG_ 1153 ZR_RSE_aktivieren 3;
BA_ "GenSigSwitchedByIgnition" SG_ 1153 ZR_RSE_aktivieren 0;
BA_ "GenSigSendType" SG_ 1153 ZR_Sta_Inszenierung 4;
BA_ "GenSigSwitchedByIgnition" SG_ 1153 ZR_Sta_Inszenierung 0;
BA_REL_ "GenSigTimeoutTime" BU_SG_REL_ Gateway_Max SG_ 2549088375 Getriebe_Nachlauftyp 5000;
BA_REL_ "GenSigTimeoutTime" BU_SG_REL_ Gateway_Max SG_ 2549088375 KN_Getriebe_01_DiagPfad 5000;
BA_REL_ "GenSigTimeoutTime" BU_SG_REL_ Gateway_Max SG_ 2549088375 Getriebe_01_KD_Fehler 2500;
BA_REL_ "GenSigTimeoutTime" BU_SG_REL_ Gateway_Max SG_ 2549088374 Motor_Nachlauftyp 5000;
BA_REL_ "GenSigTimeoutTime" BU_SG_REL_ Gateway_Max SG_ 2549088374 KN_MO_DiagPfad 5000;
BA_REL_ "GenSigTimeoutTime" BU_SG_REL_ Gateway_Max SG_ 2549088374 MO_KD_Fehler 2500;
BA_REL_ "GenSigTimeoutTime" BU_SG_REL_ Getriebe_DQ SG_ 2463978753 KST_WFS_Fahrfreigabe_Anforderung 5000;
BA_REL_ "GenSigTimeoutTime" BU_SG_REL_ Getriebe_DQ SG_ 2463978753 KST_Sonderzustand_Status 5000;
BA_REL_ "GenSigTimeoutTime" BU_SG_REL_ Getriebe_DQ SG_ 2463978753 KST_Sonderzustand_Anforderung 5000;
BA_REL_ "GenSigTimeoutTime" BU_SG_REL_ Getriebe_DQ SG_ 960 Klemmen_Status_01_CRC 1000;
BA_REL_ "GenSigTimeoutTime" BU_SG_REL_ Getriebe_DQ SG_ 960 Klemmen_Status_01_BZ 1000;
BA_REL_ "GenSigTimeoutTime" BU_SG_REL_ Getriebe_DQ SG_ 960 ZAS_Kl_15 1000;
BA_REL_ "GenSigTimeoutTime" BU_SG_REL_ Getriebe_DQ SG_ 960 BCM_Remotestart_KL15_Anf 1000;
BA_REL_ "GenSigTimeoutTime" BU_SG_REL_ Getriebe_DQ SG_ 1719 KBI_Standzeit_02 5000;
BA_REL_ "GenSigTimeoutTime" BU_SG_REL_ Getriebe_DQ SG_ 134 LWI_QBit_Lenkradwinkel 500;
BA_REL_ "GenSigTimeoutTime" BU_SG_REL_ Getriebe_DQ SG_ 134 LWI_Lenkradwinkel 500;
BA_REL_ "GenSigTimeoutTime" BU_SG_REL_ Getriebe_DQ SG_ 134 LWI_VZ_Lenkradwinkel 500;
BA_REL_ "GenSigTimeoutTime" BU_SG_REL_ Motor_konv SG_ 792 Kamera_Systemzustand 800;
BA_REL_ "GenSigTimeoutTime" BU_SG_REL_ Motor_konv SG_ 1426 KY_StartStopp_Info 2000;
BA_REL_ "GenSigTimeoutTime" BU_SG_REL_ Motor_konv SG_ 2463978753 Klemmen_Status_02_CRC 5000;
BA_REL_ "GenSigTimeoutTime" BU_SG_REL_ Motor_konv SG_ 2463978753 Klemmen_Status_02_BZ 5000;
BA_REL_ "GenSigTimeoutTime" BU_SG_REL_ Motor_konv SG_ 2463978753 KST_Sonderzustand_Status 5000;
BA_REL_ "GenSigTimeoutTime" BU_SG_REL_ Motor_konv SG_ 2463978753 KST_Sonderzustand_Anforderung 5000;
BA_REL_ "GenSigTimeoutTime" BU_SG_REL_ Motor_konv SG_ 960 Klemmen_Status_01_CRC 1000;
BA_REL_ "GenSigTimeoutTime" BU_SG_REL_ Motor_konv SG_ 960 Klemmen_Status_01_BZ 1000;
BA_REL_ "GenSigTimeoutTime" BU_SG_REL_ Motor_konv SG_ 960 ZAS_Kl_15 1000;
BA_REL_ "GenSigTimeoutTime" BU_SG_REL_ Motor_konv SG_ 960 ZAS_Kl_50_Startanforderung 1000;
BA_REL_ "GenSigTimeoutTime" BU_SG_REL_ Motor_konv SG_ 960 BCM_Remotestart_Betrieb 1000;
BA_REL_ "GenSigTimeoutTime" BU_SG_REL_ Motor_konv SG_ 960 BCM_Remotestart_KL15_Anf 1000;
BA_REL_ "GenSigTimeoutTime" BU_SG_REL_ Motor_konv SG_ 960 BCM_Remotestart_MO_Start 1000;
BA_REL_ "GenSigTimeoutTime" BU_SG_REL_ Motor_konv SG_ 1420 Klemmen_Steuerung_01_CRC 5000;
BA_REL_ "GenSigTimeoutTime" BU_SG_REL_ Motor_konv SG_ 1420 Klemmen_Steuerung_01_BZ 5000;
BA_REL_ "GenSigTimeoutTime" BU_SG_REL_ Motor_konv SG_ 1420 KST_Anf_Klemme_50 5000;
BA_REL_ "GenSigTimeoutTime" BU_SG_REL_ Motor_konv SG_ 949 KL_Drehz_Anh 1000;
BA_REL_ "GenSigTimeoutTime" BU_SG_REL_ Motor_konv SG_ 949 KL_Vorwarn_Komp_ein 1000;
BA_REL_ "GenSigTimeoutTime" BU_SG_REL_ Motor_konv SG_ 949 KL_Zustand 1000;
BA_REL_ "GenSigTimeoutTime" BU_SG_REL_ Motor_konv SG_ 949 KL_nachtr_Stopp_Anf 1000;
BA_REL_ "GenSigTimeoutTime" BU_SG_REL_ Motor_konv SG_ 949 KL_Last_Kompr 1000;
BA_REL_ "GenSigTimeoutTime" BU_SG_REL_ Motor_konv SG_ 949 KL_Thermomanagement 1000;
BA_REL_ "GenSigTimeoutTime" BU_SG_REL_ Motor_konv SG_ 949 KL_StartStopp_Info 1000;
BA_REL_ "GenSigTimeoutTime" BU_SG_REL_ Motor_konv SG_ 949 KL_Freilauf_Info 1000;
BA_REL_ "GenSigTimeoutTime" BU_SG_REL_ Motor_konv SG_ 949 KL_Anf_KL 1000;
BA_REL_ "GenSigTimeoutTime" BU_SG_REL_ Motor_konv SG_ 949 KL_el_Zuheizer_Stufe 1000;
BA_REL_ "GenSigTimeoutTime" BU_SG_REL_ Motor_konv SG_ 949 KL_Ausstattung_Klima 1000;
BA_REL_ "GenSigTimeoutTime" BU_SG_REL_ Motor_konv SG_ 1640 KL_PTC_Verbauinfo 2000;
BA_REL_ "GenSigTimeoutTime" BU_SG_REL_ Motor_konv SG_ 2589283574 OBDProtocol_Klima 5000;
BA_REL_ "GenSigTimeoutTime" BU_SG_REL_ Motor_konv SG_ 1505 BCM1_Aussen_Temp_ungef 2000;
BA_REL_ "GenSigTimeoutTime" BU_SG_REL_ Motor_konv SG_ 1505 BCM1_OBD_FStatus_ATemp 2000;
BA_REL_ "GenSigTimeoutTime" BU_SG_REL_ Motor_konv SG_ 1513 DS_Kaeltemittel_P 2000;
BA_REL_ "GenSigTimeoutTime" BU_SG_REL_ Motor_konv SG_ 779 KBI_Vorglueh_System_Lampe 500;
BA_REL_ "GenSigTimeoutTime" BU_SG_REL_ Motor_konv SG_ 779 KBI_Anzeigestatus_GRA 500;
BA_REL_ "GenSigTimeoutTime" BU_SG_REL_ Motor_konv SG_ 779 KBI_Tankwarnung 500;
BA_REL_ "GenSigTimeoutTime" BU_SG_REL_ Motor_konv SG_ 779 KBI_MFA_v_Einheit_01 500;
BA_REL_ "GenSigTimeoutTime" BU_SG_REL_ Motor_konv SG_ 779 KBI_Handbremse 500;
BA_REL_ "GenSigTimeoutTime" BU_SG_REL_ Motor_konv SG_ 779 KBI_Anzeigestatus_LIM 500;
BA_REL_ "GenSigTimeoutTime" BU_SG_REL_ Motor_konv SG_ 779 KBI_angez_Geschw 500;
BA_REL_ "GenSigTimeoutTime" BU_SG_REL_ Motor_konv SG_ 1719 KBI_Standzeit_02 5000;
BA_REL_ "GenSigTimeoutTime" BU_SG_REL_ Motor_konv SG_ 1719 KBI_Inhalt_Tank 5000;
BA_REL_ "GenSigTimeoutTime" BU_SG_REL_ Motor_konv SG_ 1719 KBI_FStatus_Tank 5000;
BA_REL_ "GenSigTimeoutTime" BU_SG_REL_ Motor_konv SG_ 1719 KBI_aktive_Laengsfunktion_02 5000;
BA_REL_ "GenSigTimeoutTime" BU_SG_REL_ Motor_konv SG_ 1719 KBI_Oelwechsel_durchgefuehrt 5000;
BA_REL_ "GenSigTimeoutTime" BU_SG_REL_ Motor_konv SG_ 1719 KBI_QBit_Aussen_Temp_gef 5000;
BA_REL_ "GenSigTimeoutTime" BU_SG_REL_ Motor_konv SG_ 1719 KBI_Aussen_Temp_gef 5000;
BA_REL_ "GenSigTimeoutTime" BU_SG_REL_ Motor_konv SG_ 1720 KBI_Variante 5000;
BA_REL_ "GenSigTimeoutTime" BU_SG_REL_ Motor_konv SG_ 1720 KBI_GAP_Warn_Zeit_abgelaufen 5000;
BA_REL_ "GenSigTimeoutTime" BU_SG_REL_ Motor_konv SG_ 1720 KBI_Tankfuellstand_Prozent 5000;
BA_REL_ "GenSigTimeoutTime" BU_SG_REL_ Motor_konv SG_ 1720 KBI_Tankinhalt_hochaufl 5000;
BA_REL_ "GenSigTimeoutTime" BU_SG_REL_ Motor_konv SG_ 2589283631 KBI_Kilometerstand_HiRes 5000;
BA_REL_ "GenSigTimeoutTime" BU_SG_REL_ Motor_konv SG_ 285 EPS_StartStopp_Info 2000;
BA_REL_ "GenSigTimeoutTime" BU_SG_REL_ Motor_konv SG_ 982 BCM2_Bremsl_durch_ECD 1000;
BA_REL_ "GenSigTimeoutTime" BU_SG_REL_ Motor_konv SG_ 982 LH_3_Bremsl_def 1000;
BA_REL_ "GenSigTimeoutTime" BU_SG_REL_ Motor_konv SG_ 982 LH_Bremsl_li_ges_def 1000;
BA_REL_ "GenSigTimeoutTime" BU_SG_REL_ Motor_konv SG_ 982 LH_Bremsl_re_ges_def 1000;
BA_REL_ "GenSigTimeoutTime" BU_SG_REL_ Motor_konv SG_ 134 LWI_Sensorstatus 500;
BA_REL_ "GenSigTimeoutTime" BU_SG_REL_ Motor_konv SG_ 134 LWI_QBit_Lenkradwinkel 500;
BA_REL_ "GenSigTimeoutTime" BU_SG_REL_ Motor_konv SG_ 134 LWI_Lenkradwinkel 500;
BA_REL_ "GenSigTimeoutTime" BU_SG_REL_ Motor_konv SG_ 134 LWI_VZ_Lenkradwinkel 500;
BA_REL_ "GenSigTimeoutTime" BU_SG_REL_ Motor_konv SG_ 134 LWI_VZ_Lenkradw_Geschw 500;
BA_REL_ "GenSigTimeoutTime" BU_SG_REL_ Motor_konv SG_ 134 LWI_Lenkradw_Geschw 500;
BA_REL_ "GenSigTimeoutTime" BU_SG_REL_ Motor_konv SG_ 1153 Nav_FoD_Status 5000;
BA_REL_ "GenSigTimeoutTime" BU_SG_REL_ Parksperre SG_ 960 ZAS_Kl_15 1000;
BA_REL_ "GenSigTimeoutTime" BU_SG_REL_ Schaltbetaetigung SG_ 960 ZAS_Kl_15 1000;
VAL_ 792 Kamera_Systemzustand 0 "Kamera_operativ" 1 "Kamera_Initialisierung" 2 "Kamera_schaltet_ab" 3 "Kamera_Fehler" ;
VAL_ 792 Kamera_FDD_Eigenblend_Guete 14 "Init" 15 "Fehler" ;
VAL_ 792 Kamera_FDD_Eigenblend 0 "Keine_Eigenblendung_erkannt" 1 "Eigenblendung_erkannt" ;
VAL_ 792 Kamera_FDD_Strassenbeleuchung 0 "keine_Strassenbeleuchtung" 1 "Strassenbeleuchtung" 2 "Strassenleuchte" 3 "nicht_verfuegbar" ;
VAL_ 792 Kamera_FDD_Funktionsstatus 0 "FDD_ein_aktiv" 1 "FDD_ein_passiv" 2 "FDD_ein_Einschraenkung_Sicht" 3 "FDD_ein_Fehler_HW_SW" 4 "FDD_aus" 6 "Init" ;
VAL_ 792 Kamera_FDD_Anz_Strassenleuchten 15 "Init" ;
VAL_ 792 Kamera_FDD_Verkehrsrichtung 0 "rechtsverkehr" 1 "linksverkehr" 2 "Init" 3 "nicht verfuegbar" ;
VAL_ 792 Kamera_Helligkeit 1022 "Init" 1023 "Fehler" ;
VAL_ 792 VZE_Status_EDR 0 "Commanded_Off" 1 "On_but_Not_ControllingOrWarning" 2 "Actively_Warning" 3 "Actively_Controlling" 4 "Driver_Override" 5 "Faulted" ;
VAL_ 792 Kamera_FSH_aktiv 0 "Kamera_Frontscheibenheizung_nicht_aktiviert" 1 "Kamera_Frontscheibenheizung_aktiviert" ;
VAL_ 1426 KY_ID_Geber1_im_Fzg 0 "inaktiv" 1 "aktiv" ;
VAL_ 1426 KY_ID_Geber2_im_Fzg 0 "inaktiv" 1 "aktiv" ;
VAL_ 1426 KY_ID_Geber3_im_Fzg 0 "inaktiv" 1 "aktiv" ;
VAL_ 1426 KY_ID_Geber4_im_Fzg 0 "inaktiv" 1 "aktiv" ;
VAL_ 1426 KY_Startknopf_Bel 0 "inaktiv" 1 "aktiv" ;
VAL_ 1426 KY_ID_Geber_Suche 0 "inaktiv" 1 "aktiv" ;
VAL_ 1426 KY_Meldungen 0 "keine_Meldung" 1 "Schluessel_nicht_gefunden" 2 "Schluessel_im_Kofferraum" 3 "Schluessel_im_Fahrzeug" 4 "Kessy_defekt" ;
VAL_ 1426 KY_Gong_600 0 "inaktiv" 1 "aktiv" ;
VAL_ 1426 KY_Passiv_Autolock_Menue 0 "inaktiv" 1 "aktiv" ;
VAL_ 1426 KY_Passiv_Autolock_Akt 0 "inaktiv" 1 "aktiv" ;
VAL_ 1426 KY_Passiv_Autolock 0 "inaktiv" 1 "aktiv" ;
VAL_ 1426 KY_Passiv_Autounlock 0 "inaktiv" 1 "aktiv" ;
VAL_ 1426 KY_Gestik_HD 0 "inaktiv" 1 "aktiv" ;
VAL_ 1426 KY_StartStopp_Info 0 "Motorlauf_nicht_notwendig_(Stoppfreigabe)" 1 "Motoranlauf_nicht_zwingend_notwendig_(Stoppverbot,keine_Startanforderung)" 2 "Motoranlauf_zwingend_notwendig_(Startanforderung)" 3 "Systemfehler" ;
VAL_ 1426 KY_Fzg_Verlassen_erkannt 0 "nicht_erkannt" 1 "erkannt" ;
VAL_ 1426 KY_Fzg_Zugang_erkannt 0 "nicht_erkannt" 1 "erkannt" ;
VAL_ 1426 KY_EasyClose_Abbruch 0 "EasyClose_kein_Abbruch" 1 "EasyClose_Abbruch" ;
VAL_ 1426 KY_EasyClose_Status 0 "Lampe_AUS" 1 "Lampe_EIN" 2 "Lampe_NORMAL" 3 "Lampe_HEKTIK" 4 "Akustik_Verweigerung" ;
VAL_ 1426 KY_HD_Auffahrt 0 "keine_Anforderung" 1 "HD_Auffahrt_angefordert" ;
VAL_ 1426 KY_HD_Zufahrt 0 "keine_Anforderung" 1 "HD_Zufahrt_angefordert" ;
VAL_ 1426 KY_Aktive_LFScans 0 "Init" 1 "Entry_Exit_Scan_1" 2 "Entry_Exit_Scan_2" 3 "GO_Scan_1" 4 "GO_Scan_2" 5 "Keyminder_Scan" 6 "ServiceKey1_Scan" 7 "ServiceKey2_Scan" 8 "Komfortlauf_RW_Begrenzer" 9 "Komfortlauf_RW_Begrenzer_EHeck" 10 "RSSI_Scan_EasyClose" 11 "PU_Scan" 12 "Diagnose_Scan" ;
VAL_ 1426 KY_LF_Aktiv 0 "Funktempfang_nicht_aktiv" 1 "LF_Funkempfang_aktiv" ;
VAL_ 1426 KY_AnzKoord_Info 0 "Init" 1 "Keyminder_Suche_erfolgreich" 2 "Keyminder_Suche_negativ" ;
VAL_ 1426 KY_Schluesselposition_9 0 "nicht_gefunden" 1 "im_Innenraum_gefunden" 2 "im_Aussenraum_gefunden_nah" 3 "im_Aussenraum_gefunden_fern" ;
VAL_ 1426 KY_Schluesselposition_1 0 "nicht_gefunden" 1 "im_Innenraum_gefunden" 2 "im_Aussenraum_gefunden_nah" 3 "im_Aussenraum_gefunden_fern" ;
VAL_ 1426 KY_Schluesselposition_2 0 "nicht_gefunden" 1 "im_Innenraum_gefunden" 2 "im_Aussenraum_gefunden_nah" 3 "im_Aussenraum_gefunden_fern" ;
VAL_ 1426 KY_Schluesselposition_3 0 "nicht_gefunden" 1 "im_Innenraum_gefunden" 2 "im_Aussenraum_gefunden_nah" 3 "im_Aussenraum_gefunden_fern" ;
VAL_ 1426 KY_Schluesselposition_4 0 "nicht_gefunden" 1 "im_Innenraum_gefunden" 2 "im_Aussenraum_gefunden_nah" 3 "im_Aussenraum_gefunden_fern" ;
VAL_ 1426 KY_Schluesselposition_5 0 "nicht_gefunden" 1 "im_Innenraum_gefunden" 2 "im_Aussenraum_gefunden_nah" 3 "im_Aussenraum_gefunden_fern" ;
VAL_ 1426 KY_Schluesselposition_6 0 "nicht_gefunden" 1 "im_Innenraum_gefunden" 2 "im_Aussenraum_gefunden_nah" 3 "im_Aussenraum_gefunden_fern" ;
VAL_ 1426 KY_Schluesselposition_7 0 "nicht_gefunden" 1 "im_Innenraum_gefunden" 2 "im_Aussenraum_gefunden_nah" 3 "im_Aussenraum_gefunden_fern" ;
VAL_ 1426 KY_Schluesselposition_8 0 "nicht_gefunden" 1 "im_Innenraum_gefunden" 2 "im_Aussenraum_gefunden_nah" 3 "im_Aussenraum_gefunden_fern" ;
VAL_ 960 RSt_Fahrerhinweise 0 "Init" 1 "Fahreruebernahme_Hinweis_ZAT_Automat_ohne_Gong" 2 "Fahreruebernahme_Hinweis_ZAT_Automat_mit_Gong" 3 "Fahreruebernahme_Hinweis_ZAT_Handschalter_ohne_Gong" 4 "Fahreruebernahme_Hinweis_ZAT_Handschalter_mit_Gong" 5 "Fahreruebernahme_Hinweis_ZAS_Automat_ohne_Gong" 6 "Fahreruebernahme_Hinweis_ZAS_Automat_mit_Gong" 7 "Fahreruebernahme_Hinweis_ZAS_Handschalter_ohne_Gong" 8 "Fahreruebernahme_Hinweis_ZAS_Handschalter_mit_Gong" 9 "RemoteStart_aktiv_ohne_Gong" 10 "RemoteStart_aktiv_mit_Gong" 11 "void" 12 "void" 13 "void" 14 "void" 15 "void" ;
VAL_ 960 ZAS_Kl_S 0 "aus" 1 "S_Kontakt_ein" ;
VAL_ 960 ZAS_Kl_15 0 "aus" 1 "ein" ;
VAL_ 960 ZAS_Kl_X 0 "aus" 1 "ein" ;
VAL_ 960 ZAS_Kl_50_Startanforderung 0 "aus" 1 "KL50_ein_Startwunsch_Fahrer" ;
VAL_ 960 BCM_Remotestart_Betrieb 0 "kein_RS_Betrieb" 1 "RS_Betrieb" ;
VAL_ 960 ZAS_Kl_Infotainment 0 "inaktiv" 1 "aktiv" ;
VAL_ 960 BCM_Remotestart_KL15_Anf 0 "inaktiv" 1 "aktiv" ;
VAL_ 960 BCM_Remotestart_MO_Start 0 "nicht_angefordert" 1 "angefordert" ;
VAL_ 960 KST_Warn_P1_ZST_def 0 "nicht_defekt" 1 "defekt" ;
VAL_ 960 KST_Warn_P2_ZST_def 0 "nicht_defekt" 1 "defekt" ;
VAL_ 960 KST_Fahrerhinweis_1 0 "inaktiv" 1 "aktiv" ;
VAL_ 960 KST_Fahrerhinweis_2 0 "inaktiv" 1 "aktiv" ;
VAL_ 960 BCM_Ausparken_Betrieb 0 "kein_Betrieb" 1 "Ausparkvorgang_aktiv" ;
VAL_ 960 KST_Fahrerhinweis_4 0 "inaktiv" 1 "aktiv" ;
VAL_ 960 KST_Fahrerhinweis_5 0 "inaktiv" 1 "aktiv" ;
VAL_ 960 KST_Fahrerhinweis_6 0 "inaktiv" 1 "aktiv" ;
VAL_ 2463978753 KST_WFS_Fahrfreigabe_Anforderung 0 "Keine" 1 "Uneingeschraenkt" 2 "Eingeschraenkt" ;
VAL_ 2463978753 KST_Sonderzustand_Status 0 "Init" 1 "Uebergang_neue_Anforderung" 2 "Aktiv" 3 "Fehler" ;
VAL_ 2463978753 KST_Sonderzustand_Anforderung 0 "Init" 1 "RemoteStart" 2 "RemoteParkAssist" 3 "IntelligentParkAssist" 4 "TrainiertesParken" 5 "OnlineRemoteUpdate" 6 "Einfrierschutz" 7 "Klemme15ViaDiagnose" 8 "RueckwandklappenSicherungPDC" 9 "ParkHausPilot" 10 "AnhaengerAnkuppelAssistent" 11 "MotorWeiterlaufSchaltung" 31 "Fehler" ;
VAL_ 2463978753 KST_ComfortReadyStatus 0 "aus" 1 "ComfortReadyStatus_ein" ;
VAL_ 2463978753 KST_Freigabe_Zustand 0 "Init" 1 "Kl50_freigegeben" 2 "Kl50_gesperrt" ;
VAL_ 1420 KST_Anf_Klemme_15 0 "nicht_angefordert" 1 "angefordert" ;
VAL_ 1420 KST_Anf_Klemme_50 0 "nicht_angefordert" 1 "angefordert" ;
VAL_ 1420 KST_Anf_Klemme_S 0 "nicht_angefordert" 1 "angefordert" ;
VAL_ 1420 KST_Txt_Werkstatt 0 "Aus" 1 "Ein" ;
VAL_ 1420 KST_Txt_P_Gang 0 "Aus" 1 "Ein" ;
VAL_ 1420 KST_Txt_Panikabschaltung 0 "Aus" 1 "Ein" ;
VAL_ 1420 KST_Anf_Klemmenfreigabe_ELV 0 "nicht_angefordert" 1 "angefordert" ;
VAL_ 1420 KST_Txt_Komfortabschaltung 0 "inaktiv" 1 "aktiv" ;
VAL_ 1420 KST_ZAT_betaetigt 0 "Aus" 1 "Ein" ;
VAL_ 1420 KST_Unterdr_Zuendungsmeldung 0 "keine_Unterdr_der_Zuendungsmeldung" 1 "Unterdr_der_Zuendungsmeldung_aktiv" ;
VAL_ 1420 KST_aut_Abschaltung_Zuendung 0 "Zuendung_wird_bei_Verl_nicht_deaktiviert" 1 "Zuendung_wird_bei_Verl_deaktiviert" ;
VAL_ 1420 KST_Anf_Klemmenfreigabe_WFS 0 "nicht_angefordert" 1 "angefordert" ;
VAL_ 1420 KST_Anf_ZV_Verriegelung 0 "inaktiv" 1 "aktiv" ;
VAL_ 1420 Relais_VoKo_angesteuert 0 "nicht_angesteuert" 1 "angesteuert" ;
VAL_ 1420 RSt_Anforderung_HMS 0 "keine_Anforderung" 1 "halten" 2 "parken" 3 "halten_Standby" 4 "anfahren" 5 "Loesen_ueber_Rampe" 6 "Parken_mit_P" ;
VAL_ 1420 KST_Zuendungswarnung 0 "keine_Ausgabe_Zuendungswarnung" 1 "Ausg_Zuendungswarnung_Stillstand" 2 "Ausg_Zuendungswarnung_Fahrt" 3 "reserved" ;
VAL_ 1420 KST_Anzeige_Klemmenzustand 0 "keine_Anzeige" 1 "Fehler_Infotainment" 2 "Update_in_progress" 3 "Fehler_Infotainment_Fzg_Gesperrt" ;
VAL_ 949 KL_Drehz_Anh 0 "keine_Anhebung" 1 "Drehzahlanhebung_vom_Motor_angefordert" ;
VAL_ 949 KL_Vorwarn_Komp_ein 0 "Init" 1 "Vorwarnung_Kompressor_ein" ;
VAL_ 949 KL_AC_Schalter 0 "aus" 1 "ein" ;
VAL_ 949 KL_Komp_Moment_alt 1 "veraltet_bzw_Ermittlung_des_Moments_nicht_moeglich__zB_keine_Drehzahl_kein_Kaeltemitteldruck" ;
VAL_ 949 KL_Vorwarn_Zuheizer_ein 0 "keine_Vorwarnung" 1 "Vorwarnung_Zuheizer_ein" ;
VAL_ 949 KL_Zustand 0 "Aus" 1 "Ein" ;
VAL_ 949 KL_Kompressorkupplung_linear 253 "volle_Ansteuerung" 254 "Init__nicht_bedient" ;
VAL_ 949 KL_Charisma_FahrPr 0 "keine_Funktion" 1 "Programm_1" 2 "Programm_2" 3 "Programm_3" 4 "Programm_4" 5 "Programm_5" 6 "Programm_6" 7 "Programm_7" 8 "Programm_8" 9 "Programm_9" 10 "Programm_10" 11 "Programm_11" 12 "Programm_12" 13 "Programm_13" 14 "Programm_14" 15 "Programm_15" ;
VAL_ 949 KL_Charisma_Status 0 "Init" 1 "verfuegbar" 2 "nicht_verfuegbar" 3 "asynchron_durch_Fahrerwunsch" ;
VAL_ 949 KL_nachtr_Stopp_Anf 0 "nicht_angefordert" 1 "angefordert" ;
VAL_ 949 KL_T_Charge 0 "Taster_nicht_betaetigt" 1 "Taster_betaetigt" ;
VAL_ 949 KL_Last_Kompr 255 "Fehler" ;
VAL_ 949 KL_Spannungs_Anf 0 "keine_Anforderung" 1 "Anforderung_Stufe_1" 2 "Anforderung_Stufe_2" 3 "Anforderung_Stufe_3" ;
VAL_ 949 KL_Thermomanagement 0 "keine_Freigabe_TMM__max_Heizbedarf" 1 "kleine_Freigabe_TMM" 2 "mittlere_Freigabe_TMM" 3 "volle_Freigabe_TMM__kein_Heizbedarf" ;
VAL_ 949 KL_StartStopp_Info 0 "Motorlauf_nicht_notwendig_(Stoppfreigabe)" 1 "Motoranlauf_nicht_zwingend_notwendig_(Stoppverbot,keine_Startanforderung)" 2 "Motoranlauf_zwingend_notwendig_(Startanforderung)" 3 "Systemfehler" ;
VAL_ 949 KL_Freilauf_Info 0 "Freilauf_freigegeben" 1 "Uebergang_in_Freilauf_unzulaessig" 2 "Freilauf_nicht_freigegeben_Abbruch" 3 "Freilauf_Anforderung" ;
VAL_ 949 KL_Anf_KL 255 "Fehler" ;
VAL_ 949 KL_el_Zuheizer_Stufe 0 "Aus" 1 "Stufe_1" 2 "Stufe_2" 3 "Stufe_3" ;
VAL_ 949 KL_Ausstattung_Klima 0 "Heizung_elektrisch" 1 "Klimamanuell_elektrisch" 2 "Climatic__1_Zone" 3 "Climatronic__1_Zone" 4 "Climatronic__2_Zonen" 5 "Climatronic__3_Zonen" 6 "Climatronic__4_Zonen" 7 "reserviert" ;
VAL_ 949 KL_Variante_Standheizung 0 "Wasserstandheizung_60_min_Laufzeit" 1 "Luftstandheizung_120_min_Laufzeit" 2 "Wasserstandheizung_120_min_Laufzeit" 3 "Wasser_und_Luftstandheizung_120_min_Laufzeit" ;
VAL_ 949 KL_AirCleaner_aktiv 0 "AirCleaner_nicht_aktiv" 1 "AirCleaner_aktiv" ;
VAL_ 949 KL_Anf_KV 126 "Init" ;
VAL_ 1640 KL_LRH_Taster 0 "nicht_betaetigt" 1 "betaetigt" ;
VAL_ 1640 KL_LRH_Stufe 0 "Stufe_niedrig" 1 "Stufe_mittel" 2 "Stufe_hoch" 3 "AUS" ;
VAL_ 1640 HSH_Taster 0 "nicht_betaetigt" 1 "short_push" 2 "long_push" 3 "tbd" ;
VAL_ 1640 FSH_Taster 0 "nicht_betaetigt" 1 "betaetigt" ;
VAL_ 1640 KL_Zuheizer_Freigabe 0 "keine_Freigabe_Zuheizer" 1 "Zuheizerfreigabe" ;
VAL_ 1640 KL_Beschlagsgefahr 0 "keine_Beschlagsgefahr" 1 "Beschlagsgefahr" ;
VAL_ 1640 KRH_Soll_li 0 "aus" 1 "Stufe_1" 2 "Stufe_2" 3 "Stufe_3" ;
VAL_ 1640 KRH_Soll_re 0 "aus" 1 "Stufe_1" 2 "Stufe_2" 3 "Stufe_3" ;
VAL_ 1640 KL_Geblspng_Soll 0 "0V_Motorspannung" 252 "0V_sofort_Abschalten" 253 "0V_senken_mit_Rampe" 254 "reserviert" 255 "Fehler" ;
VAL_ 1640 KL_Geblspng_Fond_Soll 0 "0V_Motorspannung" 252 "0V_sofort_Abschalten" 253 "0V_senken_mit_Rampe" 254 "reserviert" 255 "Fehler" ;
VAL_ 1640 KL_I_Geblaese 255 "Fehler" ;
VAL_ 1640 KL_Kompressorstrom_soll 1022 "Init" 1023 "Fehler" ;
VAL_ 1640 KL_Umluftklappe_Status 0 "Frischluft" 1 "Teilumluft_10" 2 "Teilumluft_20" 3 "Teilumluft_30" 4 "Teilumluft_40" 5 "Teilumluft_50" 6 "Teilumluft_60" 7 "Teilumluft_70" 8 "Teilumluft_80" 9 "Teilumluft_90" 10 "Umluft" 14 "Init" 15 "Fehler" ;
VAL_ 1640 KL_PTC_Verbauinfo 0 "kein_PTC" 1 "600W_geschaltet" 2 "1000W_geschaltet" 3 "1400W_LIN" ;
VAL_ 1511 KL_HV_Heizer_Strom 255 "Init" ;
VAL_ 1511 KL_EKK_Strom 255 "Init" ;
VAL_ 1511 KL_Pumpe_02_Soll 126 "Init" 127 "Fehler" ;
VAL_ 1511 KL_Ventil_03_Soll 0 "nicht_ansteuern" 1 "Ventil_ansteuern" ;
VAL_ 1511 KL_Ventil_10_Status 0 "Ventil_nicht_angesteuert" 1 "Ventil_angesteuert" 2 "reserviert" 3 "reserviert" 4 "reserviert" 5 "Ventil_nicht_verbaut" 6 "Init" 7 "Fehler" ;
VAL_ 1511 KL_Senderkennung 0 "Sender Climatronic SG" 1 "Sender Waermepumpen SG" ;
VAL_ 1511 WP_KJ_Soll 0 "Init_Keine_Anforderung" 1 "KJ_oeffnen" 2 "KJ_schliessen" 3 "Fehler" ;
VAL_ 1511 KL_Fehler_HV_EKK 0 "Init" 1 "Kein HV Fehler am EKK erkannt" 2 "HV Fehler am EKK erkannt" 3 "Fehler" ;
VAL_ 1511 KL_Fehler_HV_Heizer 0 "Init" 1 "Kein HV Fehler am HV Heizer erkannt" 2 "HV Fehler am HV Heizer erkannt" 3 "Fehler" ;
VAL_ 1511 KL_BattKond_WaPu_DZMax 62 "Init" 63 "Fehler" ;
VAL_ 1511 WP_Kuehlerluefter_Anf 255 "Fehler" ;
VAL_ 1511 KL_KM_ASV_01_Status 0 "Ventil nicht geschaltet" 1 "Ventil geschaltet" 2 "Ventil nicht verbaut" 3 "Fehler" ;
VAL_ 1511 KL_KM_ASV_02_Status 0 "Ventil nicht geschaltet" 1 "Ventil geschaltet" 2 "Ventil nicht verbaut" 3 "Fehler" ;
VAL_ 1511 KL_Vorwarn_HVHeizer_Leistung 0 "Init_Aus" 1 "500W" 2 "1000W" 3 "1500W" 4 "2000W" 5 "2500W" 6 "3000W" 7 "3500W" 8 "4000W" 9 "4500W" 10 "5000W" 11 "5500W" 12 "6000W" 13 "6500W" 14 "7000W" 15 "Fehler" ;
VAL_ 1511 KL_Status_EoHVL_EKK 0 "Init" 1 "Keine_offene_HV_Leitung_erkannt" 2 "offene_HV_Leitung_erkannt" 3 "Fehler" ;
VAL_ 1511 KL_Status_EoHVL_Heizer 0 "Init" 1 "Keine_offene_HV_Leitung_erkannt" 2 "offene_HV_Leitung_erkannt" 3 "Fehler" ;
VAL_ 1511 KL_Status_EoHVL_EKK_2 0 "Init" 1 "Keine_offene_HV_Leitung_erkannt" 2 "offene_HV_Leitung_erkannt" 3 "Fehler" ;
VAL_ 1511 KL_Status_EoHVL_Heizer_2 0 "Init" 1 "Keine_offene_HV_Leitung_erkannt" 2 "offene_HV_Leitung_erkannt" 3 "Fehler" ;
VAL_ 1514 KL_Standklima_Status_03 0 "nicht_aktiv" 1 "aktiv" 2 "eingeschraenkt_aktiv" 3 "Systemfehler" 4 "nicht_moeglich" 5 "keine_Freigabe" 6 "Init" 7 "Fehler" ;
VAL_ 1514 KL_Kundenwunsch_Kuehlen 0 "Keine_Kuehlung_gewuenscht" 1 "Kuehlung_gewuenscht" ;
VAL_ 1514 KL_OBD_Status 0 "MILaus" 1 "MILan" ;
VAL_ 1514 KL_KLE_Fehler_Anf 0 "inaktiv" 1 "aktiv" ;
VAL_ 1514 KL_Fehler_NTKreis 0 "KeinFehler" 1 "Fehler" ;
VAL_ 1514 KL_VK_Anf 0 "keine_Startanf_von_Climatronic" 1 "Startanf_via_FFB" 2 "Startanf_via_Sofortheiztaste" 3 "VK_Strategie_STH" 4 "Startanf_via_ZV_FFB" 5 "VK_Abbruch" 6 "Init" 7 "Fehler" ;
VAL_ 1514 KL_Standklima_Status_02 0 "nicht_aktiv" 1 "aktiv" 2 "eingeschraenkt_aktiv" 3 "Abbruch_durch_Benutzer" 4 "nicht_moeglich" 5 "Aussenhuelle_offen" 6 "Init" 7 "Fehler" ;
VAL_ 1514 KL_Standklima_RemoteModus 0 "Init__nicht_aktiv" 1 "Lueften" 2 "Kuehlen" 3 "Heizen" 4 "reserviert" 5 "reserviert" 6 "reserviert" 7 "reserviert" ;
VAL_ 1514 KBT_Defrost_aktiv 0 "inaktiv" 1 "aktiv" ;
VAL_ 1514 KL_VK_Betriebsdauer 62 "Init" 63 "Fehler" ;
VAL_ 1514 KL_Heizbedarf 0 "Kein_Heizbedarf" 1022 "Init" 1023 "Fehler" ;
VAL_ 1514 KL_Innentemp_KBT_Sensor 1022 "Init" 1023 "Fehler" ;
VAL_ 1514 KL_Vorkond_Strategie 0 "Aus" 1 "Spülen" 2 "Kanalkühlung" 3 "Kühlwasserzirkulation" 4 "Aktive Kühlung" 5 "Heizen" 6 "Reheat" 7 "Heizen_elektrisch" 8 "Heizen_verbrennungstechnisch" 13 "Strategie_nicht_berechnet" 14 "Konditionierung_nicht_moeglich" 15 "Init" ;
VAL_ 2589283627 KL_HVH_1_VerbautStatus 0 "nicht_verbaut" 1 "verbaut" ;
VAL_ 2589283627 KL_EKK_1_VerbautStatus 0 "nicht_verbaut" 1 "verbaut" ;
VAL_ 2589283627 KL_Texte 0 "keine_Anzeige" 1 "Heizleistung_zu_gering" 2 "Kuehlleistung_zu_gering" 3 "Text_3" ;
VAL_ 2589283627 KL_HVH_2_VerbautStatus 0 "nicht_verbaut" 1 "verbaut" ;
VAL_ 2589283627 KL_EKK_2_VerbautStatus 0 "nicht_verbaut" 1 "verbaut" ;
VAL_ 2589283627 KL_Leistung_Klima_Anf 254 "Init" ;
VAL_ 2589283627 KL_Heizen_Status 0 "Keine_Heizleistung_Anfgefordert" 1 "Max_Defrost" 2 "Kaltstart" 3 "Eingeschwungen_hohe_Last" 4 "Eingeschwungen_niedrige_Last" 14 "Init" 15 "Fehler" ;
VAL_ 2589283627 KL_K_Status 0 "Init" 1 "Lueften" 2 "Kuehlen_Innenraum" 3 "Kuehlen_Chiller" 4 "Kuehlen_kombiniert" 5 "Heizen_Luft_WP" 6 "Heizen_kombiniert_WP" 7 "Kuehlen_Innenraum_mit_HGK" 8 "Kuehlen_kombiniert_mit_HGK" 9 "Heizen_Wasser_WP" 10 "Shutdown" 11 "Enteisen" 14 "Fehler" ;
VAL_ 2589283627 KL_Status_Battkuehlung 0 "Init" 1 "Keine_Kuehlanforderung" 2 "Kuehlung_in_Ordnung" 3 "Kuehlung_temporaer_nicht_aktiv" 4 "Kuehlung_inaktiv_fuer_Komfort" 5 "Kuehlung_nicht_moeglich" ;
VAL_ 2589283627 Kl_Klima_Aktiv 0 "Nicht_aktiv_oder_Init" 1 "Klima_aktiv" ;
VAL_ 2589283627 KL_Kuehlungs_Status 0 "Klimatisierung_ausgeschaltet" 1 "Pulldown" 2 "Eingeschwungen_hohe_Last" 3 "Eingeschwungen_niedrige_Last" 4 "Eingeschwungen_mit_Drehzahlbegre" 5 "BattK_nicht_moeglich" 6 "BattK_temporaer_nicht_moeglich" 14 "Init" 15 "Fehler" ;
VAL_ 2589283627 KL_HV_Energie_Anf 253 "nicht_berechnet" 254 "Init" 255 "Fehler" ;
VAL_ 2589283627 TME_HVEM_HV_Anf 0 "INIT" 1 "HV_Netz_nicht_angefordert" 2 "HV_Netz_angefordert" 3 "Fehler" ;
VAL_ 2589283627 KL_IstLeistung 254 "Init" 255 "Fehler" ;
VAL_ 2589283627 KL_Temp_Kundenwunsch 0 "Init" 1 "LO" 30 "HI" 63 "Fehler" ;
VAL_ 2589283574 KL_OBD_Status_Auth 0 "MILaus" 1 "MILan" ;
VAL_ 2589283574 OBDProtocol_Klima 0 "OBDonUDS" 1 "OBDclassic" 16 "NoOBD" 254 "Init" 255 "Fehler" ;
VAL_ 1505 BCM1_Aussen_Temp_ungef 253 "nicht_verbaut" 254 "Initwert" 255 "Fehler" ;
VAL_ 1505 BCM_Heizungsabsperrventil_Status 0 "HAV_offen" 1 "HAV_geschlossen" 2 "Init_oder_nicht_verbaut" 3 "Fehler" ;
VAL_ 1505 BCM_Heizungspumpe_Status 0 "Pumpe_aus" 1 "Pumpe_aktiv_und_Stauts_iO" 2 "Init_oder_nicht_verbaut" 3 "Fehler" ;
VAL_ 1505 BCM_Kompressorkupplung_Status 0 "Kupplung_offen" 1 "Kupplung_geschlossen" 2 "Init_oder_nicht_verbaut" 3 "Fehler" ;
VAL_ 1505 BCM1_PTC_stufig_Status 0 "Aus" 1 "Stufe_1_aktiv" 2 "Stufe_2_aktiv" 3 "Stufe_3_aktiv" 6 "Init_oder_nicht_verbaut" 7 "Fehler" ;
VAL_ 1505 BCM1_FStatus_Aussentemp_ungef 0 "iO" 1 "niO" ;
VAL_ 1505 BCM1_Kompressorstrom_ist 254 "Init, bzw. nicht verfuegbar" 255 "Fehler" ;
VAL_ 1505 BCM1_OBD_FStatus_ATemp 0 "kein Fehler / Init / nicht verbaut" 1 "KS- (Kurzschluss nach minus)" 2 "KS+ (Kurzschluss nach plus)" 3 "OC (Leitungsunterbrechung)" 4 "OOR+ (Signal zu gross)" 5 "OOR- (Signal zu klein)" 6 "RC+ (Signal unplausibel zu gross)" 7 "RC- (Signal unplausibel zu klein)" 8 "KS+/OC (Kurzschluss nach plus/Unterbrechung)" 9 "KS-/OC  (Kurzschluss nach minus/Unterbrechung)" 10 "KS-/KS+  (Kurzschluss nach minus/plus)" 11 "KS-/KS+/OC (Kurzschluss nach minus/plus/Unterbrechung)" 12 "frei" 13 "frei" 14 "frei" 15 "frei" ;
VAL_ 1513 DS_Kaeltemittel_P 2046 "Init" 2047 "Fehler" ;
VAL_ 1513 DS_Status 0 "i.O." 1 "t.b.d." 2 "Init bzw. nicht verfügbar" 3 "Fehler" ;
VAL_ 1513 ION_Status 0 "Hochspannung_ausgeschaltet" 1 "Hochspannung_eingeschaltet" 2 "Init" ;
VAL_ 1513 ION_Status_LED 0 "Aus" 1 "Ein" ;
VAL_ 1513 AAU_Geblaese 126 "Init" 127 "Fehler" ;
VAL_ 1513 ION_Status_Taster 0 "nicht_betaetigt" 1 "betaetigt" ;
VAL_ 1513 DS_Kaeltemittel_P_WP 2046 "Init" 2047 "Fehler" ;
VAL_ 2549088272 Gateway_KompSchutz 0 "inaktiv" 1 "aktiv" ;
VAL_ 2549088272 Gateway_Abschaltstufe 0 "keine_Einschraenkung" 1 "Funktionseinschraenkung" ;
VAL_ 2549088272 Gateway_Transport_Mode 0 "keine_Einschraenkung" 1 "Funktionseinschraenkung" ;
VAL_ 2549088272 Gateway_Nachlauftyp 0 "Komm_bei_KL15_EIN" 1 "Komm_nach_KL15_AUS" 2 "Komm_bei_KL15_AUS" ;
VAL_ 2549088272 NM_Gateway_Wakeup 0 "Peripherie_Wakeup__Ursache_nicht_bekannt" 1 "Bus_Wakeup" 2 "KL15_HW" 3 "ACAN_Wakeup" 4 "FCAN_Wakeup" 5 "KCAN_Wakeup" 6 "ICAN_Wakeup" 7 "DiagCAN_Wakeup" 8 "ECAN_Wakeup" 9 "Energie_LIN_Wakeup" 10 "Bedien_LIN_Wakeup" 11 "HybridCAN_Wakeup" 12 "Flexray_Wakeup" 13 "MFL_WakeUp" 14 "Ethernet" 15 "DCAN_Wakeup" 16 "K2CAN_Wakeup" 17 "CCAN" 18 "AFSCAN_Wakeup" 19 "LIN1" 20 "LIN2" 21 "LIN3" 22 "LIN4" 23 "LIN5" 24 "LIN6" 25 "FASCAN" 26 "FAS2CAN" 27 "MDKCAN" 32 "FlexRay_Branch1_WakeUp" 33 "FlexRay_Branch2_WakeUp" 34 "FlexRay_Branch3_WakeUp" 35 "FlexRay_Branch4_WakeUp" 36 "FlexRay_Branch5_WakeUp" 37 "FlexRay_Branch6_WakeUp" 38 "FlexRay_Branch7_WakeUp" 39 "FlexRay_Branch8_WakeUp" 40 "FlexRay_Branch9_WakeUp" 41 "FlexRay_Branch10_WakeUp" 42 "FlexRay_Branch11_WakeUp" 43 "FlexRay_Branch12_WakeUp" 44 "FlexRay_Branch13_WakeUp" 45 "FlexRay_Branch14_WakeUp" 46 "FlexRay_Branch15_WakeUp" 47 "FlexRay_Branch16_WakeUp" 128 "Energiemanagement" 129 "Funktionswakeup_OBDC" 130 "Hochvoltenergiemanagement" 131 "CWU_empfangen" 132 "Fuer_Bus_relevanten_FC_empfangen" 133 "OnlineDienst_empfangen" 134 "HV_Aktivieren" 135 "HV_Deaktivieren" 136 "VTS_Suche_DriverCard" 137 "VTS_Hupen_Blinken" 138 "Remote_Vehicle_Status" 139 "Plug_and_Charge" 140 "VTS_Wakeup_Infotainment" 141 "EMHLR" 142 "NFcGW_fordert_OTA_FC_an" 143 "Komponentenschutz" 144 "UserStateServer" 145 "Dimmung" 146 "Kessy" 147 "StandardAussenlicht" 148 "ParkKoordinator" 149 "HVLMDynamicChargingPOI" 150 "HVLMChargingManagementServer" 151 "HVLMExtendedChargingMonitoring" 152 "Zentralverriegelung" 153 "FunctionOnDemand" 154 "IAA" 155 "StandKlimatisierung" 156 "RealTimeMonitor" 157 "Klemmensteuerung" 158 "Fremdladung_erkannt" ;
VAL_ 2549088272 KN_GW_DiagPfad 0 "aktiv" 1 "inaktiv" ;
VAL_ 2549088272 GW_KD_Fehler 0 "kein_KD_Fehler" 1 "KD_Fehler" ;
VAL_ 2549088375 Getriebe_KompSchutz 0 "inaktiv" 1 "aktiv" ;
VAL_ 2549088375 Getriebe_01_Abschaltstufe 0 "keine_Einschraenkung" 1 "Funktionseinschraenkung" ;
VAL_ 2549088375 Getriebe_01_Transport_Mode 0 "keine_Einschraenkung" 1 "Funktionseinschraenkung" ;
VAL_ 2549088375 Getriebe_Nachlauftyp 0 "Komm_bei_KL15_EIN" 1 "Komm_nach_KL15_AUS" 2 "Komm_bei_KL15_AUS" 3 "Komm_bei_KL15_AUS_beschraenkt" ;
VAL_ 2549088375 KN_Getriebe_01_ECUKnockOutTimer 63 "ECUKnockOut_deaktiviert" ;
VAL_ 2549088375 KN_Getriebe_01_BusKnockOut 0 "Funktion_nicht_ausgeloest" 1 "Veto_aktiv" 2 "Funktion_ausgeloest" 3 "Funktion_deaktiviert" ;
VAL_ 2549088375 KN_Getriebe_01_BusKnockOutTimer 255 "BusKnockOut_deaktiviert" ;
VAL_ 2549088375 NM_Getriebe_01_Wakeup 0 "Peripherie_Wakeup__Ursache_nicht_bekannt" 1 "Bus_Wakeup" 2 "KL15_HW" 3 "Ende_N_Haltephase" 4 "WakeUp_Leitung" 5 "KL30_Reset" ;
VAL_ 2549088375 KN_Getriebe_01_ECUKnockOut 0 "Funktion_nicht_ausgeloest" 1 "Veto_war_aktiv" 2 "Funktion_ausgeloest" 3 "Funktion_deaktiviert" ;
VAL_ 2549088375 KN_Getriebe_01_DiagPfad 0 "aktiv" 1 "inaktiv" ;
VAL_ 2549088375 Getriebe_01_KD_Fehler 0 "Kein_KD_Fehler" 1 "KD_Fehler" ;
VAL_ 2549088374 Motor_KompSchutz 0 "inaktiv" 1 "aktiv" ;
VAL_ 2549088374 MO_01_Abschaltstufe 0 "keine_Einschraenkung" 1 "Funktionseinschraenkung" ;
VAL_ 2549088374 MO_01_Transport_Mode 0 "keine_Einschraenkung" 1 "Funktionseinschraenkung" ;
VAL_ 2549088374 Motor_Nachlauftyp 0 "Komm_bei_KL15_EIN" 1 "Komm_nach_KL15_AUS" 2 "Komm_bei_KL15_AUS" ;
VAL_ 2549088374 KN_Motor_ECUKnockOutTimer 63 "ECUKnockOut_deaktiviert" ;
VAL_ 2549088374 KN_Motor_BusKnockOut 0 "Funktion_nicht_ausgeloest" 1 "Veto_aktiv" 2 "Funktion_ausgeloest" 3 "Funktion_deaktiviert" ;
VAL_ 2549088374 KN_Motor_BusKnockOutTimer 255 "BusKnockOut_deaktiviert" ;
VAL_ 2549088374 NM_MO_01_Wakeup 0 "Peripherie_Wakeup_Ursache_nicht_bekannt" 1 "Bus_Wakeup" 2 "KL15_HW" 3 "Oelstandsmessung" 4 "Evakuierung_SCR_System" 5 "Druckbetankung" 6 "KL50_HW" 7 "Fahrstufenwechsel" ;
VAL_ 2549088374 KN_Motor_ECUKnockOut 0 "Funktion_nicht_ausgeloest" 1 "Veto_war_aktiv" 2 "Funktion_ausgeloest" 3 "Funktion_deaktiviert" ;
VAL_ 2549088374 KN_MO_DiagPfad 0 "aktiv" 1 "inaktiv" ;
VAL_ 2549088374 MO_KD_Fehler 0 "kein_KD_Fehler" 1 "KD_Fehler" ;
VAL_ 779 KBI_ABS_Lampe 0 "ABS Lampe aus" 1 "ABS Lampe ein" ;
VAL_ 779 KBI_ESP_Lampe 0 "ESP Lampe aus" 1 "ESP Lampe ein" ;
VAL_ 779 KBI_BKL_Lampe 0 "BKL aus" 1 "BKL ein" ;
VAL_ 779 KBI_Airbag_Lampe 0 "Airbag Lampe aus" 1 "Airbag Lampe ein" ;
VAL_ 779 KBI_SILA_gueltig 0 "ungueltig" 1 "gueltig" ;
VAL_ 779 KBI_Vorglueh_System_Lampe 0 "Lampe aus" 1 "Lampe ein" ;
VAL_ 779 KBI_NV_in_Anzeige 0 "NV_nicht_in_Anzeige" 1 "NV_in_Anzeige" ;
VAL_ 779 KBI_Anzeigestatus_ACC 0 "keine_ACC_Anzeige" 1 "ACC_Anzeige_aktiv" ;
VAL_ 779 KBI_Anzeigestatus_GRA 0 "nicht_vorhanden" 1 "Anzeigemoeglichkeit_vorhanden" 2 "reserviert" 3 "Fehler" ;
VAL_ 779 KBI_Oeldruck_Schalter 0 "offen____p_kleiner_pnenn" 1 "geschlossen____p_groessergleich_pnenn" ;
VAL_ 779 KBI_Tankwarnung 0 "Lampe aus" 1 "Lampe ein" ;
VAL_ 779 KBI_MFA_v_Einheit_01 0 "kmh" 1 "mph" ;
VAL_ 779 KBI_im_Stellgliedtest 0 "kein Stellgliedtest" 1 "Kombi im Stellgliedtest" ;
VAL_ 779 KBI_Anzeigefehler_LDW 0 "nicht vorhanden bzw. unterstützt" 1 "Anzeige iO" 2 "Anzeigefehler" 3 "nicht definiert" ;
VAL_ 779 KBI_Tankwarnung_ungueltig 0 "KBI_Tankwarnung_gueltig" 1 "KBI_Tankwarnung_ungueltig" ;
VAL_ 779 KBI_Oeldruckwarnung 0 "inaktiv" 1 "aktiv" ;
VAL_ 779 KBI_Handbremse 0 "nicht_angezogen" 1 "angezogen" ;
VAL_ 779 KBI_PLA_in_Anzeige 0 "PLA_nicht_in_Anzeige" 1 "PLA_in_Anzeige" ;
VAL_ 779 KBI_Anzeigefehler_NV 0 "kein_Anzeigefehler" 1 "Anzeigefehler" ;
VAL_ 779 KBI_Anzeigestatus_LIM 0 "nicht_vorhanden" 1 "Anzeigemoeglichkeit_vorhanden" 2 "reserviert" 3 "Fehler" ;
VAL_ 779 KBI_ARA_in_Anzeige 0 "ARA nicht in Anzeige" 1 "ARA in Anzeige" ;
VAL_ 779 KBI_Taster_Lift 0 "nicht_betaetigt" 1 "betaetigt" ;
VAL_ 779 KBI_Taster_Fahrwerk 0 "nicht_betaetigt" 1 "betaetigt" ;
VAL_ 779 KBI_Audioabsenkung_MIB 0 "keine_Audio_Absenkung" 1 "Audio_Absenkung_Stufe_1" 2 "Audio_Absenkung_Stufe_2" 3 "Audio_Absenkung_Stufe_3" ;
VAL_ 779 KBI_Bestaetigung_ESP_Off 0 "ESP_off_nicht_quittiert" 1 "ESP_off_quittiert" 2 "Abbruch" ;
VAL_ 779 KBI_Anzeigestatus_RHP 0 "nicht_unterstuetzt_oder_Startup" 1 "Anzeige iO" 2 "Anzeigefehler" 3 "nicht definiert" ;
VAL_ 779 KBI_Konsistenz_ACC 0 "ACC Botschaft konsistent" 1 "ACC Botschaft inkonsistent" ;
VAL_ 779 KBI_Fehler_Anzeige_ACC 0 " iO" 1 "Anzeigefehler ACC" ;
VAL_ 779 KBI_Anzeigefehler_SWA 0 "nicht vorhanden bzw. unterstützt" 1 "Anzeige iO" 2 "Anzeigefehler" 3 "nicht definiert" ;
VAL_ 779 KBI_Systemstatus 0 "KBI_IO" 1 "KBI_System_Failure" ;
VAL_ 1719 KBI_Kilometerstand 1048574 "Init" 1048575 "Fehler" ;
VAL_ 1719 KBI_Standzeit_02 131069 "nicht_verfuegbar" 131070 "Init" 131071 "Fehler" ;
VAL_ 1719 KBI_Reserve_Warnung_Sek 0 "Keine_Warnung" 1 "Sekundaere_Reservewarnung" ;
VAL_ 1719 KBI_RDK_Kalibrier_Anf 0 "keine_Kalibrieranforderung" 1 "Kalibrieranforderung" ;
VAL_ 1719 KBI_Inhalt_Tank 126 "Init" 127 "Fehler" ;
VAL_ 1719 KBI_FStatus_Tank 0 "Tankfüllstand i.O." 1 "Tankfüllstand n.i.O" ;
VAL_ 1719 KBI_aktive_Laengsfunktion_02 0 "Init" 1 "Speedlimiter" 2 "GRA_oder_ACC" 3 "PACCh" 4 "HDC" 5 "p_GRA" 6 "p_Lim" 7 "ACC_im_GRA_Modus" 8 "Travel_Assist" 9 "RHP" ;
VAL_ 1719 KBI_FoD_PopUP_Quittiert 0 "nicht_quittiert" 1 "Meldung_quittiert" ;
VAL_ 1719 KBI_GRA_im_ACC 0 "GRA_im_ACC_nicht_ausgewaehlt" 1 "GRA_im_ACC_ausgewaehlt" ;
VAL_ 1719 KBI_Oelwechsel_durchgefuehrt 0 "Oelwechsel_nicht_durchgefuehrt" 1 "Oelwechsel_durchgefuehrt" ;
VAL_ 1719 KBI_QBit_Aussen_Temp_gef 0 "gueltiger_Wert" 1 "Ersatz_Init_oder_Fehlerwert" ;
VAL_ 1719 KBI_Aussen_Temp_gef 253 "nicht verbaut" 254 "Init" 255 "Fehler" ;
VAL_ 1720 KBI_Variante_USA 0 "keine USA-Variante" 1 "USA-Variante" ;
VAL_ 1720 KBI_Variante 0 "Zeiger Kombiinstrument" 1 "Volldisplay Kombiinstrument" ;
VAL_ 1720 KBI_GAP_Warn_Zeit_abgelaufen 0 "Zaehler_nicht_abgelaufen" 1 "Zaehler_abgelaufen" ;
VAL_ 1720 KBI_Quittierung_Naesse 0 "nicht_quittiert" 1 "quittiert" ;
VAL_ 1720 KBI_BCmE_aktiv 0 "Anzeige_nicht_aktiv" 1 "Anzeige_aktiv" ;
VAL_ 1720 KBI_Sparhinweis_quittiert 0 "nicht_quittiert" 1 "quittiert" ;
VAL_ 1720 KBI_Tankfuellstand_Prozent 126 "Init" 127 "Fehler" ;
VAL_ 1720 KBI_Nachtanken_erkannt 0 "Geberbetrieb" 1 "Nachtankmodus" ;
VAL_ 1720 KBI_Tankinhalt_hochaufl 16382 "Init" 16383 "Fehler" ;
VAL_ 1720 KBI_Max_Tankinhalt 254 "Init" 255 "Fehler" ;
VAL_ 1720 KBI_Quittierung_cAQP 0 "nicht_quittiert" 1 "quittiert" ;
VAL_ 2589283631 KBI_Tankinhalt_roh 2046 "Init" 2047 "Fehler" ;
VAL_ 2589283631 KBI_BC_Reset_E1 0 "SG_Reset" 1 "Reset_Zaehler" 2 "Reset_Zaehler" 3 "Reset_Zaehler" 4 "Reset_Zaehler" 5 "Reset_Zaehler" 6 "Reset_Zaehler" 7 "Init" ;
VAL_ 2589283631 KBI_BC_Reset_E2 0 "SG_Reset" 1 "Reset_Zaehler" 2 "Reset_Zaehler" 3 "Reset_Zaehler" 4 "Reset_Zaehler" 5 "Reset_Zaehler" 6 "Reset_Zaehler" 7 "Init" ;
VAL_ 2589283631 KBI_BC_Reset_E3 0 "SG_Reset" 1 "Reset_Zaehler" 2 "Reset_Zaehler" 3 "Reset_Zaehler" 4 "Reset_Zaehler" 5 "Reset_Zaehler" 6 "Reset_Zaehler" 7 "Init" ;
VAL_ 285 EPS_Notlauf 0 "kein_Notlauf" 1 "Notlauf_Unterspannung" 2 "Notlauf_Ueberspannung" 3 "reserviert" 4 "Notlauf_Uebertemperatur" 5 "Notlauf_Unterspannung_und_Uebertemperatur" 6 "Notlauf_Ueberspannung_und_Uebertemperatur" 7 "reserviert" 8 "reserviert" 9 "reserviert" 10 "reserviert" 11 "reserviert" 12 "reserviert" 13 "reserviert" 14 "reserviert" 15 "reserviert" ;
VAL_ 285 EPS_Lastinfo 254 "Init" 255 "Fehler" ;
VAL_ 285 EPS_Unterstuetzungsleistung 254 "Init" 255 "Fehler" ;
VAL_ 285 EPS_Drehzahlreserve 126 "Init" 127 "Fehler" ;
VAL_ 285 EPS_VZ_Drehzahlreserve 0 "positiv" 1 "negativ" ;
VAL_ 285 EPS_Leistungsanforderung 0 "keine_Anforderung" 1 "Anforderung_hoehere_Spannung_oder_Leistung" ;
VAL_ 285 EPS_StartStopp_Info 0 "Motorlauf_nicht_notwendig_(Stoppfreigabe)" 1 "Motoranlauf_nicht_zwingend_notwendig_(Stoppverbot,keine_Startanforderung)" 2 "Motoranlauf_zwingend_notwendig_(Startanforderung)" 3 "Systemfehler" ;
VAL_ 285 EPS_Motorstartverzoegerung 0 "Motoranlauf_Freigabe" 1 "Motoranlauf_verzoegern" 3 "Systemfehler" ;
VAL_ 285 EPS_Warmstartunterstuetzung 0 "keine_Lenkunterstuetzung_im_Stopp_Modus_moeglich" 1 "Lenkung_fordert_keine_erhoehte_Startspannung" ;
VAL_ 285 EPS_Versorgungsspannung 254 "Init" 255 "Fehler" ;
VAL_ 982 BCM2_Bremsl_durch_ECD_invers 0 "Bremslicht_durch_ECD_aktiv" 1 "Bremslicht_ist_aus" ;
VAL_ 982 BCM2_Bremsl_durch_ECD 0 "Bremslicht_ist_aus" 1 "Bremslicht_durch_ECD_aktiv" ;
VAL_ 982 LH_Aussenlicht_def 0 "OK" 1 "defekt" ;
VAL_ 982 LH_Standlicht_H_aktiv 1 "Standlicht hinten aktiv" ;
VAL_ 982 LH_Parklicht_HL_aktiv 0 "nicht aktiv" 1 "Parklicht hinten links aktiv" ;
VAL_ 982 LH_Parklicht_HR_aktiv 0 "nicht aktiv" 1 "Parklicht hinten rechts aktiv" ;
VAL_ 982 LH_Bremslicht_H_aktiv 1 "Bremslicht hinten aktiv" ;
VAL_ 982 LH_Nebelschluss_aktiv 0 "nicht aktiv" 1 "aktiv" ;
VAL_ 982 LH_Rueckfahrlicht_aktiv 0 "nicht_aktiv" 1 "aktiv" ;
VAL_ 982 LH_Blinker_HL_akt 1 "Blinker hinten links aktiv" ;
VAL_ 982 LH_Blinker_HR_akt 1 "Blinker hinten rechts aktiv" ;
VAL_ 982 LH_Blinker_li_def 0 "OK" 1 "Blinker hinten links defekt" ;
VAL_ 982 LH_Bremsl_li_def 0 "OK" 1 "mindestens ein Bremslicht hinten links defekt" ;
VAL_ 982 LH_Schlusslicht_li_def 0 "OK" 1 "mindestens ein Schlusslicht hinten links defekt" ;
VAL_ 982 LH_Rueckf_li_def 0 "OK" 1 "Rückfahrlicht hinten links defekt" ;
VAL_ 982 LH_Nebel_li_def 0 "OK" 1 "Nebelschlusslicht_hinten_links_defekt" ;
VAL_ 982 LH_Schluss_Brems_Nebel_li_def 0 "iO" 1 "defekt" ;
VAL_ 982 LH_Schluss_Brems_Nebel_re_def 0 "iO" 1 "defekt" ;
VAL_ 982 LH_Zusatzschlussl_def 0 "OK" 1 "mindestens_ein_Zusatzschlusslicht_defekt" ;
VAL_ 982 LH_Schluss_Brems_li_def 0 "OK" 1 "defekt" ;
VAL_ 982 LH_Schluss_Nebel_li_def 0 "OK" 1 "defekt" ;
VAL_ 982 LH_SL_BRL_BLK_li_def 0 "OK" 1 "defekt" ;
VAL_ 982 LH_Brems_Blk_li_def 0 "OK" 1 "defekt" ;
VAL_ 982 LH_Diag_Status_re_def 0 "OK" 1 "Aussenlict_Diagnose_Systemstoerung_rechts" ;
VAL_ 982 LH_Diag_Status_li_def 0 "OK" 1 "Aussenlicht_Diagnose_Systemstoerung_links" ;
VAL_ 982 LH_Diag_LED_li_def 0 "OK" 1 "Heckleuchte_links_defekt" ;
VAL_ 982 LH_Diag_LED_re_def 0 "OK" 1 "Heckleuchte_rechts_defekt" ;
VAL_ 982 LH_Blinker_re_def 0 "OK" 1 "Blinker hinten rechts defekt" ;
VAL_ 982 LH_Bremsl_re_def 0 "OK" 1 "mindestens ein Bremslicht hinten rechts defekt" ;
VAL_ 982 LH_Schlusslicht_re_def 0 "OK" 1 "mindestens_ein_Schlusslicht_hinten_rechts_defekt" ;
VAL_ 982 LH_Rueckf_re_def 0 "OK" 1 "Rückfahrlicht hinten rechts defekt" ;
VAL_ 982 LH_Nebel_re_def 0 "OK" 1 "Nebelschlusslicht hinten rechts defekt" ;
VAL_ 982 LH_Schluss_Brems_re_def 0 "OK" 1 "defekt" ;
VAL_ 982 LH_Schluss_Nebel_re_def 0 "OK" 1 "defekt" ;
VAL_ 982 LH_SL_BRL_BLK_re_def 0 "OK" 1 "defekt" ;
VAL_ 982 LH_Brems_Blk_re_def 0 "OK" 1 "defekt" ;
VAL_ 982 LH_Kennzl_def 0 "OK" 1 "Kennzeichenbeleuchtung hinten defekt" ;
VAL_ 982 LH_3_Bremsl_def 0 "OK" 1 "hochgesetzte  Bremsleuchte defekt" ;
VAL_ 982 LH_Nebel_mi_def 0 "OK" 1 " Nebelschlusslicht hinten Mitte defekt" ;
VAL_ 982 LH_Rueckf_mi_def 0 "OK" 1 "Rückfahllicht Mitte defekt" ;
VAL_ 982 LH_Bremsl_li_ges_def 0 "OK" 1 "Alle Bremslichter hinten links defekt" ;
VAL_ 982 LH_Bremsl_re_ges_def 0 "OK" 1 "Alle Bremslichter hinten rechts defekt" ;
VAL_ 2527679634 LSH_Zuheizen 0 "Aus" 1 "Ein" ;
VAL_ 2527679634 LSH_KVS_Ueberlauf 0 "kein_Ueberlauf" 1 "Kraftstoff_Ueberlauf_erkannt" ;
VAL_ 2527679634 LSH_KL_DBetr_Anf 0 "nicht_angefordert" 1 "angefordert" ;
VAL_ 2527679634 LSH_Fehlerstatus 0 "kein_Fehler" 1 "Unterspannung" 2 "Tankfuellstand_zu_gering" 3 "Fehler_Betrieb_verhindert" 4 "Heizgeraet_verriegelt" 5 "Fehler_Betrieb_nicht_verhindert" 6 "Emissionsueberschreitung" ;
VAL_ 134 LWI_Sensorstatus 0 "iO" 1 "nicht kalibriert" ;
VAL_ 134 LWI_QBit_Sub_Daten 0 "LWS-Subinfo real (Lenkradwinkelinformation ADS-tauglich) " 1 "LWS-Subinfo simuliert (Lenkradwinkelinformation nicht ADS-tauglich )" ;
VAL_ 134 LWI_QBit_Lenkradwinkel 0 "gültiger Wert" 1 "ausserhalb der Spezifikation" ;
VAL_ 134 LWI_Lenkradwinkel 8190 "Init" 8191 "Fehler" ;
VAL_ 134 LWI_VZ_Lenkradwinkel 0 "positiv_links_von_der_Nullstellung" 1 "negativ" ;
VAL_ 134 LWI_VZ_Lenkradw_Geschw 0 "positiv_links_von_der_Nullstellung" 1 "negativ" ;
VAL_ 134 LWI_Lenkradw_Geschw 510 "Init" 511 "Fehler" ;
VAL_ 1153 ZR_LoGeWa_Event_Kombiwarnung 0 "Init" 1 "Unfall" 2 "Traktionsverlust" 3 "Panne" 4 "Sichtbehinderung" 5 "Aquaplaning" 6 "EEBL" 7 "SEF_stat" 8 "SEF_dyn_allgemein" 9 "SEF_dyn_vorne" 10 "SEF_dyn_hinten" 11 "SEF_dyn_links" 12 "SEF_dyn_rechts" 13 "Stauende" ;
VAL_ 1153 Nav_FoD_Status 0 "Init" 1 "Nav_permanently_available" 2 "FoD_Nav_not_activated" 3 "FoD_Nav_activated" 4 "R4N_Nav_not_activated" ;
VAL_ 1153 MIB_ASW_Diagnose 0 "ASW_Warnton_nicht_verfuegbar" 1 "ASW_Warnton_verfuegbar" ;
VAL_ 1153 ZR_Lichter_Tag 0 "Nacht" 1 "Tag" ;
VAL_ 1153 MIB_Tongenerator_PH_verfuegbar 0 "Tongenerator_nicht_verfuegbar" 1 "Tongenerator_vorne_verfuegbar" 2 "Tongenerator_hinten_verfuegbar" 3 "Tongenerator_gesamt_verfuegbar" 4 "Tongenerator_im_AMP" ;
VAL_ 1153 DSSS_Warning 0 "No_Warning" 1 "Red_traffic_light_guidance" 2 "Stop_sign_warning" 3 "Rear_end_collision_avoidance_warning" 4 "Intersection_collision_avoidance_warning_right" 5 "Intersection_collision_avoidance_warning_left" 6 "turn_right_collision_avoidance" 7 "turn_left_collision_avoidance" 8 "pedestrian_crossing_right" 9 "pedestrian_crossing_left" 10 "bicycle_collision_right" 11 "bicycle_collision_left" ;
VAL_ 1153 ZR_Kindersicherung_RSE 0 "inaktiv" 1 "aktiv" ;
VAL_ 1153 ZR_RSE_aktivieren 0 "inaktiv" 1 "aktiv" ;
VAL_ 1153 MMI_SDS_aktiv 0 "inaktiv" 1 "aktiv" ;
VAL_ 1153 MU_SecondDisplay 0 "Init" 1 "gueltige_Karte" 2 "ungueltiges_Signal" 3 "Nicht_Verbaut" ;
VAL_ 1153 MMI_Telefon_aktiv 0 "Telefongespraech_nicht_aktiv" 1 "Telefongespraech_aktiv" ;
VAL_ 1153 MMI_Gurt_Mic_ref 0 "Downlink_inaktiv" 1 "Downlink_aktiv" ;
VAL_ 1153 ZR_Sta_Inszenierung 0 "Init" 1 "Inszenierung_deaktiviert" 2 "Inszenierung_Start" 3 "Inszenierung_Stop" ;
VAL_ 1153 ZR_AppConnect_Zustand 0 "AppConnect_nicht_in_Anzeige" 1 "AppConnect_in_Anzeige" ;
VAL_ 1153 ZR_Parken_Sondermodus 0 "Init" 1 "Sondermodus_aktiv" 2 "Sondermodus_nicht_verfuegbar" 3 "WLAN_aus" 4 "WLAN_auscodiert" 15 "keine_WLAN_HW" ;
